VERSION ""

NS_ :

BS_:

BU_: VMCU TECU TACHO RECU_Virt IC3 HPCU EMS EBS DACU CIOM BBM ACM

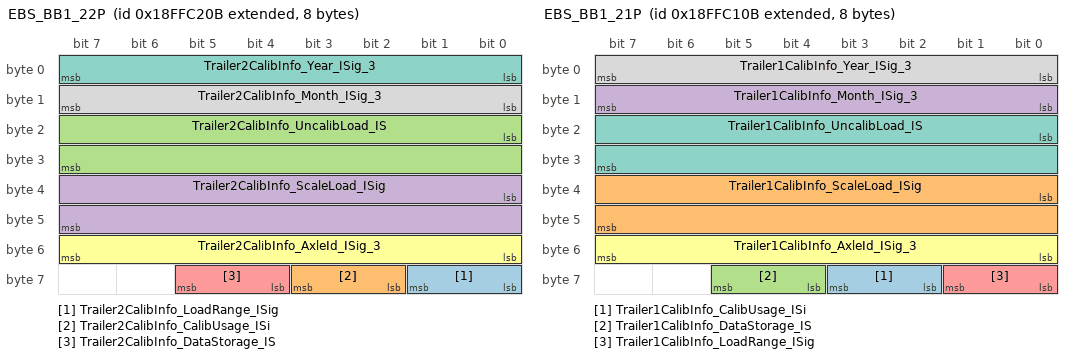
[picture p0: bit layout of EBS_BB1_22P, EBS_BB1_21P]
BO_ 2566898187 EBS_BB1_22P: 8 EBS
 SG_ Trailer2CalibInfo_LoadRange_ISig : 56|2@1+ (1,0) [0|0] ""  VMCU,IC3
 SG_ Trailer2CalibInfo_CalibUsage_ISi : 58|2@1+ (1,0) [0|0] ""  VMCU,IC3
 SG_ Trailer2CalibInfo_UncalibLoad_IS : 16|16@1+ (1,0) [0|65535] "kg"  IC3,VMCU
 SG_ Trailer2CalibInfo_ScaleLoad_ISig : 32|16@1+ (1,0) [0|65535] "kg"  IC3,VMCU
 SG_ Trailer2CalibInfo_DataStorage_IS : 60|2@1+ (1,0) [0|0] ""  IC3,VMCU
 SG_ Trailer2CalibInfo_AxleId_ISig_3 : 48|8@1+ (1,0) [0|255] "NotApplicable"  VMCU,IC3
 SG_ Trailer2CalibInfo_Year_ISig_3 : 0|8@1+ (1,1985) [1985|2240] "Years"  VMCU,IC3
 SG_ Trailer2CalibInfo_Month_ISig_3 : 8|8@1+ (1,0) [0|255] "Months"  IC3,VMCU

BO_ 2566897931 EBS_BB1_21P: 8 EBS
 SG_ Trailer1CalibInfo_CalibUsage_ISi : 58|2@1+ (1,0) [0|0] ""  IC3,VMCU
 SG_ Trailer1CalibInfo_ScaleLoad_ISig : 32|16@1+ (1,0) [0|65535] "kg"  IC3,VMCU
 SG_ Trailer1CalibInfo_DataStorage_IS : 60|2@1+ (1,0) [0|0] ""  IC3,VMCU
 SG_ Trailer1CalibInfo_Month_ISig_3 : 8|8@1+ (1,0) [0|255] "Months"  IC3,VMCU
 SG_ Trailer1CalibInfo_LoadRange_ISig : 56|2@1+ (1,0) [0|0] ""  VMCU,IC3
 SG_ Trailer1CalibInfo_AxleId_ISig_3 : 48|8@1+ (1,0) [0|255] "NotApplicable"  IC3,VMCU
 SG_ Trailer1CalibInfo_UncalibLoad_IS : 16|16@1+ (1,0) [0|65535] "kg"  VMCU,IC3
 SG_ Trailer1CalibInfo_Year_ISig_3 : 0|8@1+ (1,1985) [1985|2240] "Years"  IC3,VMCU

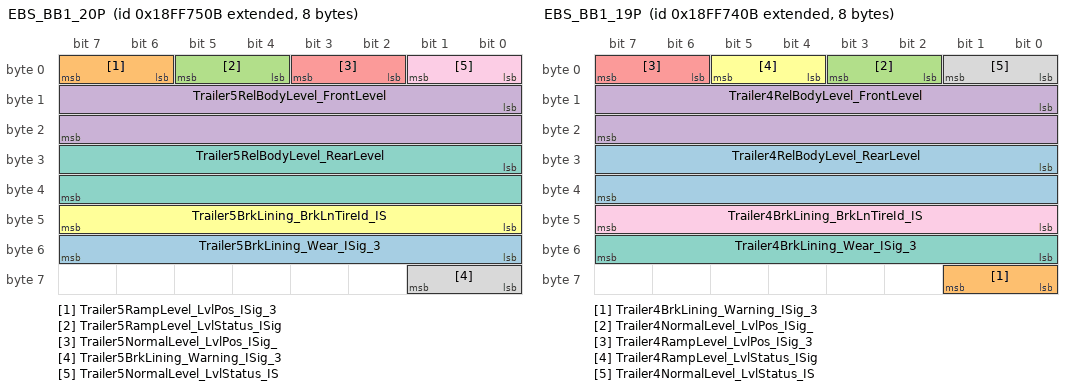
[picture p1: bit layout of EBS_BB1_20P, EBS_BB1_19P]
BO_ 2566878475 EBS_BB1_20P: 8 EBS
 SG_ Trailer5BrkLining_Wear_ISig_3 : 48|8@1+ (0.4,0) [0|102] "Percent"  IC3
 SG_ Trailer5RampLevel_LvlPos_ISig_3 : 6|2@1+ (1,0) [0|0] ""  IC3
 SG_ Trailer5RampLevel_LvlStatus_ISig : 4|2@1+ (1,0) [0|0] ""  IC3
 SG_ Trailer5RelBodyLevel_FrontLevel : 8|16@1+ (1,-32000) [-32000|33535] "mm"  VMCU
 SG_ Trailer5NormalLevel_LvlPos_ISig_ : 2|2@1+ (1,0) [0|0] ""  IC3
 SG_ Trailer5BrkLining_BrkLnTireId_IS : 40|8@1+ (1,0) [0|255] "NotApplicable"  IC3
 SG_ Trailer5RelBodyLevel_RearLevel : 24|16@1+ (1,-32000) [-32000|33535] "mm"  VMCU
 SG_ Trailer5BrkLining_Warning_ISig_3 : 56|2@1+ (1,0) [0|0] ""  IC3
 SG_ Trailer5NormalLevel_LvlStatus_IS : 0|2@1+ (1,0) [0|0] ""  IC3

BO_ 2566878219 EBS_BB1_19P: 8 EBS
 SG_ Trailer4RelBodyLevel_RearLevel : 24|16@1+ (1,-32000) [-32000|33535] "mm"  VMCU
 SG_ Trailer4BrkLining_Warning_ISig_3 : 56|2@1+ (1,0) [0|0] ""  IC3
 SG_ Trailer4NormalLevel_LvlPos_ISig_ : 2|2@1+ (1,0) [0|0] ""  IC3
 SG_ Trailer4RelBodyLevel_FrontLevel : 8|16@1+ (1,-32000) [-32000|33535] "mm"  VMCU
 SG_ Trailer4RampLevel_LvlPos_ISig_3 : 6|2@1+ (1,0) [0|0] ""  IC3
 SG_ Trailer4RampLevel_LvlStatus_ISig : 4|2@1+ (1,0) [0|0] ""  IC3
 SG_ Trailer4BrkLining_Wear_ISig_3 : 48|8@1+ (0.4,0) [0|102] "Percent"  IC3
 SG_ Trailer4NormalLevel_LvlStatus_IS : 0|2@1+ (1,0) [0|0] ""  IC3
 SG_ Trailer4BrkLining_BrkLnTireId_IS : 40|8@1+ (1,0) [0|255] "NotApplicable"  IC3

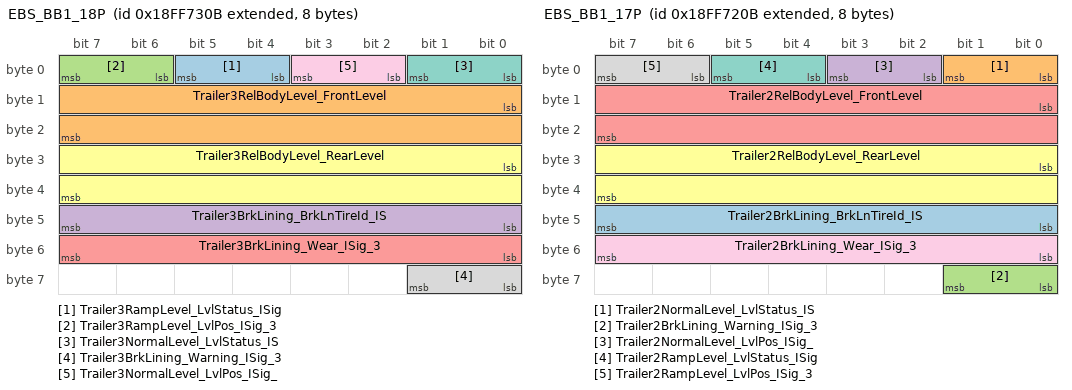
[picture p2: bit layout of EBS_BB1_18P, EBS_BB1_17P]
BO_ 2566877963 EBS_BB1_18P: 8 EBS
 SG_ Trailer3RampLevel_LvlStatus_ISig : 4|2@1+ (1,0) [0|0] ""  IC3
 SG_ Trailer3RelBodyLevel_FrontLevel : 8|16@1+ (1,-32000) [-32000|33535] "mm"  VMCU
 SG_ Trailer3RampLevel_LvlPos_ISig_3 : 6|2@1+ (1,0) [0|0] ""  IC3
 SG_ Trailer3BrkLining_BrkLnTireId_IS : 40|8@1+ (1,0) [0|255] "NotApplicable"  IC3
 SG_ Trailer3BrkLining_Wear_ISig_3 : 48|8@1+ (0.4,0) [0|102] "Percent"  IC3
 SG_ Trailer3RelBodyLevel_RearLevel : 24|16@1+ (1,-32000) [-32000|33535] "mm"  VMCU
 SG_ Trailer3NormalLevel_LvlStatus_IS : 0|2@1+ (1,0) [0|0] ""  IC3
 SG_ Trailer3BrkLining_Warning_ISig_3 : 56|2@1+ (1,0) [0|0] ""  IC3
 SG_ Trailer3NormalLevel_LvlPos_ISig_ : 2|2@1+ (1,0) [0|0] ""  IC3

BO_ 2566877707 EBS_BB1_17P: 8 EBS
 SG_ Trailer2BrkLining_BrkLnTireId_IS : 40|8@1+ (1,0) [0|255] "NotApplicable"  IC3
 SG_ Trailer2NormalLevel_LvlStatus_IS : 0|2@1+ (1,0) [0|0] ""  IC3
 SG_ Trailer2BrkLining_Warning_ISig_3 : 56|2@1+ (1,0) [0|0] ""  IC3
 SG_ Trailer2NormalLevel_LvlPos_ISig_ : 2|2@1+ (1,0) [0|0] ""  IC3
 SG_ Trailer2RelBodyLevel_FrontLevel : 8|16@1+ (1,-32000) [-32000|33535] "mm"  VMCU
 SG_ Trailer2RelBodyLevel_RearLevel : 24|16@1+ (1,-32000) [-32000|33535] "mm"  VMCU
 SG_ Trailer2RampLevel_LvlStatus_ISig : 4|2@1+ (1,0) [0|0] ""  IC3
 SG_ Trailer2RampLevel_LvlPos_ISig_3 : 6|2@1+ (1,0) [0|0] ""  IC3
 SG_ Trailer2BrkLining_Wear_ISig_3 : 48|8@1+ (0.4,0) [0|102] "Percent"  IC3

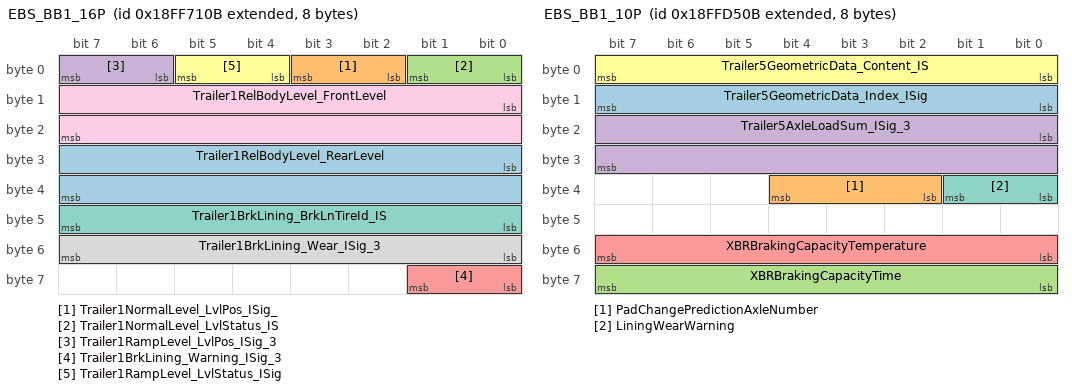
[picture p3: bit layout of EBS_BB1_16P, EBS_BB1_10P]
BO_ 2566877451 EBS_BB1_16P: 8 EBS
 SG_ Trailer1RelBodyLevel_RearLevel : 24|16@1+ (1,-32000) [-32000|33535] "mm"  VMCU
 SG_ Trailer1NormalLevel_LvlPos_ISig_ : 2|2@1+ (1,0) [0|0] ""  IC3
 SG_ Trailer1NormalLevel_LvlStatus_IS : 0|2@1+ (1,0) [0|0] ""  IC3
 SG_ Trailer1RampLevel_LvlPos_ISig_3 : 6|2@1+ (1,0) [0|0] ""  IC3
 SG_ Trailer1BrkLining_Warning_ISig_3 : 56|2@1+ (1,0) [0|0] ""  IC3
 SG_ Trailer1RampLevel_LvlStatus_ISig : 4|2@1+ (1,0) [0|0] ""  IC3
 SG_ Trailer1BrkLining_BrkLnTireId_IS : 40|8@1+ (1,0) [0|255] "NotApplicable"  IC3
 SG_ Trailer1BrkLining_Wear_ISig_3 : 48|8@1+ (0.4,0) [0|102] "Percent"  IC3
 SG_ Trailer1RelBodyLevel_FrontLevel : 8|16@1+ (1,-32000) [-32000|33535] "mm"  VMCU

BO_ 2566894859 EBS_BB1_15P: 17 EBS
 SG_ Trailer5VIN_ISig_3 : 0|136@1+ (1,0) [0|0] ""  IC3,VMCU

BO_ 2566894603 EBS_BB1_14P: 17 EBS
 SG_ Trailer4VIN_ISig_3 : 0|136@1+ (1,0) [0|0] ""  VMCU,IC3

BO_ 2566894347 EBS_BB1_13P: 17 EBS
 SG_ Trailer3VIN_ISig_3 : 0|136@1+ (1,0) [0|0] ""  VMCU,IC3

BO_ 2566894091 EBS_BB1_12P: 17 EBS
 SG_ Trailer2VIN_ISig_3 : 0|136@1+ (1,0) [0|0] ""  VMCU,IC3

BO_ 2566893835 EBS_BB1_11P: 17 EBS
 SG_ Trailer1VIN_ISig_3 : 0|136@1+ (1,0) [0|0] ""  IC3,VMCU

BO_ 2566903051 EBS_BB1_10P: 8 EBS
 SG_ Trailer5GeometricData_Index_ISig : 8|8@1+ (1,0) [0|0] ""  VMCU,IC3,DACU
 SG_ PadChangePredictionAxleNumber : 34|3@1+ (1,0) [0|0] ""  VMCU
 SG_ XBRBrakingCapacityTime : 56|8@1+ (1,0) [0|255] "s"  EMS,TECU,DACU
 SG_ Trailer5AxleLoadSum_ISig_3 : 16|16@1+ (2,0) [0|131070] "kg"  IC3,VMCU
 SG_ XBRBrakingCapacityTemperature : 48|8@1+ (0.4,0) [0|102] "Percent"  TECU,DACU,EMS
 SG_ Trailer5GeometricData_Content_IS : 0|8@1+ (1,0) [0|255] ""  VMCU,IC3,DACU
 SG_ LiningWearWarning : 32|2@1+ (1,0) [0|0] ""  IC3

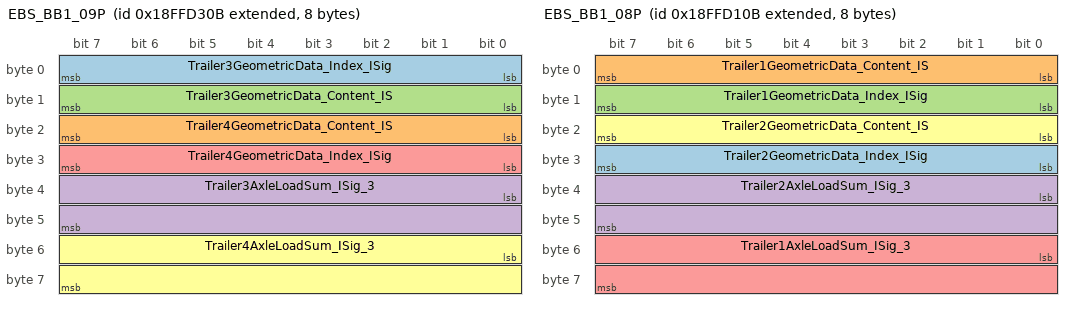
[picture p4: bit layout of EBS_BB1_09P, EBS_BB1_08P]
BO_ 2566902539 EBS_BB1_09P: 8 EBS
 SG_ Trailer3GeometricData_Index_ISig : 0|8@1+ (1,0) [0|0] ""  IC3,DACU,VMCU
 SG_ Trailer4GeometricData_Content_IS : 16|8@1+ (1,0) [0|255] ""  DACU,IC3,VMCU
 SG_ Trailer3GeometricData_Content_IS : 8|8@1+ (1,0) [0|255] ""  IC3,DACU,VMCU
 SG_ Trailer3AxleLoadSum_ISig_3 : 32|16@1+ (2,0) [0|131070] "kg"  IC3,TECU,VMCU
 SG_ Trailer4GeometricData_Index_ISig : 24|8@1+ (1,0) [0|0] ""  IC3,DACU,VMCU
 SG_ Trailer4AxleLoadSum_ISig_3 : 48|16@1+ (2,0) [0|131070] "kg"  TECU,VMCU,IC3

BO_ 2566902027 EBS_BB1_08P: 8 EBS
 SG_ Trailer2GeometricData_Index_ISig : 24|8@1+ (1,0) [0|0] ""  VMCU,DACU,IC3
 SG_ Trailer1GeometricData_Content_IS : 0|8@1+ (1,0) [0|255] ""  DACU,VMCU,IC3
 SG_ Trailer1GeometricData_Index_ISig : 8|8@1+ (1,0) [0|0] ""  IC3,DACU,VMCU
 SG_ Trailer2AxleLoadSum_ISig_3 : 32|16@1+ (2,0) [0|131070] "kg"  TECU,IC3,VMCU
 SG_ Trailer1AxleLoadSum_ISig_3 : 48|16@1+ (2,0) [0|131070] "kg"  IC3,TECU,VMCU
 SG_ Trailer2GeometricData_Content_IS : 16|8@1+ (1,0) [0|255] ""  DACU,VMCU,IC3

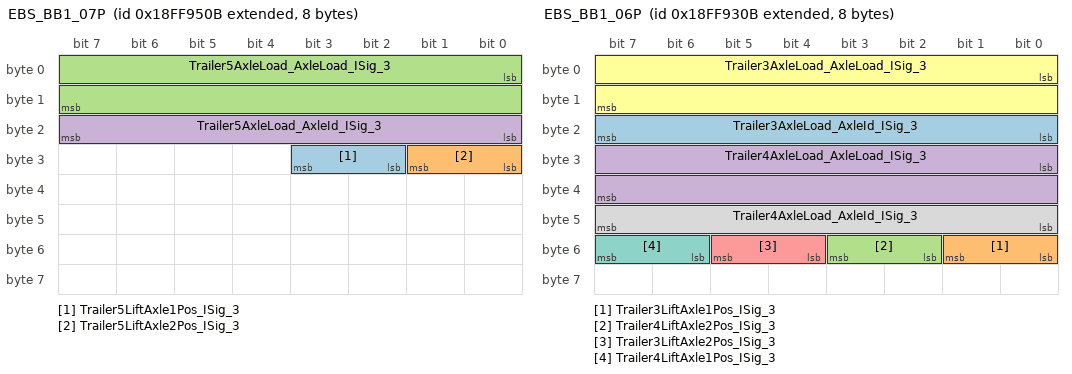
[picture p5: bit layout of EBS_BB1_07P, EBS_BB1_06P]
BO_ 2566886667 EBS_BB1_07P: 8 EBS
 SG_ Trailer5LiftAxle1Pos_ISig_3 : 26|2@1+ (1,0) [0|0] ""  VMCU,BBM,CIOM,IC3
 SG_ Trailer5LiftAxle2Pos_ISig_3 : 24|2@1+ (1,0) [0|0] ""  BBM,CIOM,VMCU,IC3
 SG_ Trailer5AxleLoad_AxleLoad_ISig_3 : 0|16@1+ (0.5,0) [0|32767.5] "kg"  BBM,VMCU,IC3
 SG_ Trailer5AxleLoad_AxleId_ISig_3 : 16|8@1+ (1,0) [0|255] "NotApplicable"  VMCU,BBM,IC3

BO_ 2566886155 EBS_BB1_06P: 8 EBS
 SG_ Trailer3AxleLoad_AxleId_ISig_3 : 16|8@1+ (1,0) [0|255] "NotApplicable"  VMCU,BBM,IC3
 SG_ Trailer3LiftAxle1Pos_ISig_3 : 48|2@1+ (1,0) [0|0] ""  BBM,VMCU,CIOM,IC3
 SG_ Trailer4LiftAxle2Pos_ISig_3 : 50|2@1+ (1,0) [0|0] ""  BBM,VMCU,CIOM,IC3
 SG_ Trailer4AxleLoad_AxleLoad_ISig_3 : 24|16@1+ (0.5,0) [0|32767.5] "kg"  BBM,VMCU,IC3
 SG_ Trailer3LiftAxle2Pos_ISig_3 : 52|2@1+ (1,0) [0|0] ""  CIOM,BBM,VMCU,IC3
 SG_ Trailer3AxleLoad_AxleLoad_ISig_3 : 0|16@1+ (0.5,0) [0|32767.5] "kg"  BBM,VMCU,IC3
 SG_ Trailer4LiftAxle1Pos_ISig_3 : 54|2@1+ (1,0) [0|0] ""  CIOM,IC3,VMCU,BBM
 SG_ Trailer4AxleLoad_AxleId_ISig_3 : 40|8@1+ (1,0) [0|255] "NotApplicable"  VMCU,IC3,BBM

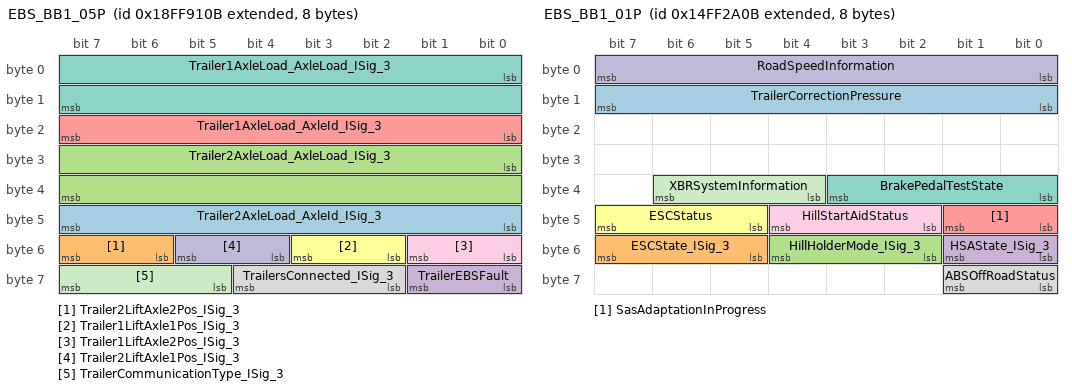
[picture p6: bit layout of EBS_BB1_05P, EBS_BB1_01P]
BO_ 2566885643 EBS_BB1_05P: 8 EBS
 SG_ Trailer2AxleLoad_AxleId_ISig_3 : 40|8@1+ (1,0) [0|255] "NotApplicable"  VMCU,BBM,IC3
 SG_ Trailer2LiftAxle2Pos_ISig_3 : 54|2@1+ (1,0) [0|0] ""  IC3,CIOM,BBM,VMCU
 SG_ Trailer2AxleLoad_AxleLoad_ISig_3 : 24|16@1+ (0.5,0) [0|32767.5] "kg"  IC3,BBM,VMCU
 SG_ TrailerEBSFault : 56|2@1+ (1,0) [0|0] ""  IC3
 SG_ Trailer1AxleLoad_AxleId_ISig_3 : 16|8@1+ (1,0) [0|255] "NotApplicable"  IC3,VMCU,BBM
 SG_ Trailer1LiftAxle1Pos_ISig_3 : 50|2@1+ (1,0) [0|0] ""  IC3,CIOM,BBM,VMCU
 SG_ Trailer1AxleLoad_AxleLoad_ISig_3 : 0|16@1+ (0.5,0) [0|32767.5] "kg"  BBM,IC3,VMCU
 SG_ TrailersConnected_ISig_3 : 58|3@1+ (1,0) [0|7] "Count"  DACU,CIOM,IC3,TECU,VMCU
 SG_ Trailer1LiftAxle2Pos_ISig_3 : 48|2@1+ (1,0) [0|0] ""  IC3,BBM,CIOM,VMCU
 SG_ Trailer2LiftAxle1Pos_ISig_3 : 52|2@1+ (1,0) [0|0] ""  IC3,CIOM,VMCU,BBM
 SG_ TrailerCommunicationType_ISig_3 : 61|3@1+ (1,0) [0|0] ""  IC3

BO_ 2566906635 EBS_BB1_04P: 8 EBS
 SG_ PredictedMileageOfNextPadChg : 0|32@1+ (1,0) [0|4294967295] "km"  IC3,VMCU
 SG_ PadChgPredictionLastPadChg : 32|32@1+ (1,0) [0|4294967295] "km"  VMCU

BO_ 2499761675 EBS_BB1_02P: 8 EBS
 SG_ HSAAvailability : 22|2@1+ (1,0) [0|0] ""  BBM,TECU
 SG_ DTCActive : 6|2@1+ (1,0) [0|0] ""  IC3
 SG_ StretchBrake_Stat_ISig_3 : 58|3@1+ (1,0) [0|0] ""  IC3,VMCU
 SG_ TrcnCtrlSlipperyRoadWarning_ISig : 4|2@1+ (1,0) [0|0] ""  BBM,IC3,DACU
 SG_ RearAxleDiffLockActvnFuncReq_ISi : 10|2@1+ (1,0) [0|0] ""  VMCU
 SG_ BrakeTempWarningLevel : 24|8@1+ (1,0) [0|255] "Percent"  VMCU,DACU,TECU,EMS
 SG_ RollerBenchModeStatus : 0|2@1+ (1,0) [0|0] ""  DACU,CIOM,IC3,VMCU
 SG_ BrakeAssistStatus : 8|2@1+ (1,0) [0|0] ""  VMCU
 SG_ LongitudinalAcceleration_ISig_3 : 32|16@1+ (0.00048828125,-15.687) [-15.687|16.31251171875] "m_per_s_squared"  BBM,IC3
 SG_ ABSManAutoInhibitionStat_ISig_3 : 61|3@1+ (1,0) [0|0] ""  IC3
 SG_ TractionFunctionSelected_ISig_3 : 53|3@1+ (1,0) [0|0] ""  IC3
 SG_ PoorBrakePerformanceWarning : 14|2@1+ (1,0) [0|0] ""  IC3
 SG_ VDCActive_ISig_3 : 56|2@1+ (1,0) [0|0] ""  IC3
 SG_ ABSInhibitionStatus_ISig_3 : 16|2@1+ (1,0) [0|0] ""  TECU,CIOM,VMCU,IC3
 SG_ RearAxleSteeringFunctionStatus : 50|3@1+ (1,0) [0|0] ""  DACU,CIOM
 SG_ AutoRearAxleDiffLockFnc_stat : 48|2@1+ (1,0) [0|0] ""  IC3
 SG_ RearAxleDiffLockActvnFuncReq_UB_ : 2|1@1+ (1,0) [0|0] ""  VMCU

BO_ 2499750411 EBS_BB1_01P: 8 EBS
 SG_ TrailerCorrectionPressure : 8|8@1+ (0.05,-1.5) [-1.5|11.25] "Bar"  VMCU
 SG_ ESCState_ISig_3 : 53|3@1+ (1,0) [0|0] ""  CIOM,IC3
 SG_ HillHolderMode_ISig_3 : 50|3@1+ (1,0) [0|0] ""  DACU,TECU
 SG_ HSAState_ISig_3 : 48|2@1+ (1,0) [0|0] ""  DACU
 SG_ SasAdaptationInProgress : 40|2@1+ (1,0) [0|0] ""  IC3
 SG_ ESCStatus : 45|3@1+ (1,0) [0|0] ""  IC3
 SG_ BrakePedalTestState : 32|4@1+ (1,0) [0|0] ""  IC3
 SG_ ABSOffRoadStatus : 56|2@1+ (1,0) [0|0] ""  VMCU,IC3,TECU
 SG_ HillStartAidStatus : 42|3@1+ (1,0) [0|0] ""  IC3
 SG_ RoadSpeedInformation : 0|8@1+ (0.805,0) [0|205.275] "Km_per_h"  VMCU
 SG_ XBRSystemInformation : 36|3@1+ (1,0) [0|0] ""  TECU,DACU,EMS

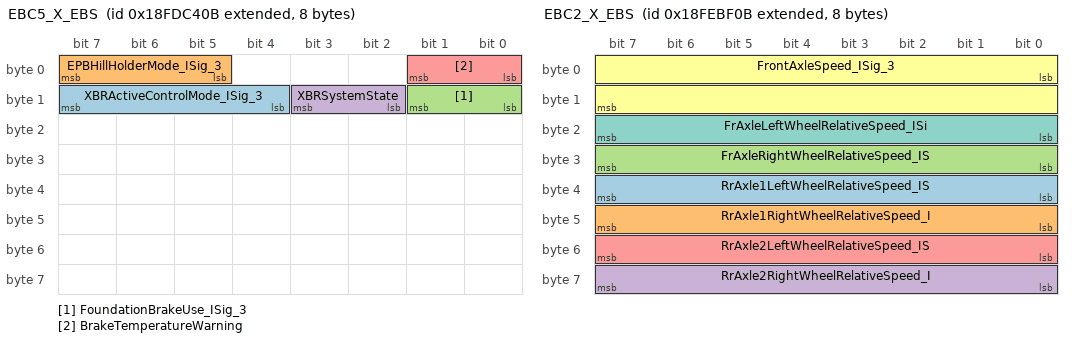
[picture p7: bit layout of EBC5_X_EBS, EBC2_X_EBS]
BO_ 2566767627 EBC5_X_EBS: 8 EBS
 SG_ XBRActiveControlMode_ISig_3 : 12|4@1+ (1,0) [0|0] ""  BBM,EMS,TECU,DACU,VMCU
 SG_ EPBHillHolderMode_ISig_3 : 5|3@1+ (1,0) [0|0] ""  TECU,IC3,VMCU
 SG_ FoundationBrakeUse_ISig_3 : 8|2@1+ (1,0) [0|0] ""  DACU,CIOM,EMS,TECU,VMCU
 SG_ XBRSystemState : 10|2@1+ (1,0) [0|0] ""  BBM,DACU,EMS,TECU
 SG_ BrakeTemperatureWarning : 0|2@1+ (1,0) [0|0] ""  IC3

BO_ 2566831883 EBC2_X_EBS: 8 EBS
 SG_ RrAxle1LeftWheelRelativeSpeed_IS : 32|8@1+ (0.0625,-7.8125) [-7.8125|8.125] "Km_per_h"  TECU,VMCU
 SG_ RrAxle1RightWheelRelativeSpeed_I : 40|8@1+ (0.0625,-7.8125) [-7.8125|8.125] "Km_per_h"  VMCU,TECU
 SG_ FrAxleRightWheelRelativeSpeed_IS : 24|8@1+ (0.0625,-7.8125) [-7.8125|8.125] "Km_per_h"  TECU,VMCU
 SG_ RrAxle2RightWheelRelativeSpeed_I : 56|8@1+ (0.0625,-7.8125) [-7.8125|8.125] "Km_per_h"  TECU,VMCU
 SG_ RrAxle2LeftWheelRelativeSpeed_IS : 48|8@1+ (0.0625,-7.8125) [-7.8125|8.125] "Km_per_h"  TECU,VMCU
 SG_ FrontAxleSpeed_ISig_3 : 0|16@1+ (0.00390625,0) [0|255.99609375] "Km_per_h"  IC3,VMCU,BBM,EMS,CIOM,DACU,TECU,TACHO
 SG_ FrAxleLeftWheelRelativeSpeed_ISi : 16|8@1+ (0.0625,-7.8125) [-7.8125|8.125] "Km_per_h"  TECU,VMCU

CM_ SG_ 2566898187 Trailer2CalibInfo_UncalibLoad_IS "10000-65023: Spare, 65024-65279: Error, 65280-65535: NotAvailable";
CM_ SG_ 2566898187 Trailer2CalibInfo_ScaleLoad_ISig "10000-65023: Spare, 65024-65279: Error, 65280-65535: NotAvailable";
CM_ SG_ 2566898187 Trailer2CalibInfo_Year_ISig_3 "254 Error ; 255 Not available";
CM_ SG_ 2566898187 Trailer2CalibInfo_Month_ISig_3 "254 Error ; 255 Not available";
CM_ SG_ 2566897931 Trailer1CalibInfo_ScaleLoad_ISig "10000-65023: Spare, 65024-65279: Error, 65280-65535: NotAvailable";
CM_ SG_ 2566897931 Trailer1CalibInfo_Month_ISig_3 "254 Error ; 255 Not available";
CM_ SG_ 2566897931 Trailer1CalibInfo_UncalibLoad_IS "10000-65023: Spare, 65024-65279: Error, 65280-65535: NotAvailable";
CM_ SG_ 2566897931 Trailer1CalibInfo_Year_ISig_3 "254 Error ; 255 Not available";
CM_ SG_ 2566903051 Trailer5AxleLoadSum_ISig_3 "65024 - 65279 Error ; 65280 - 65535 Not Available";
CM_ SG_ 2566903051 Trailer5GeometricData_Content_IS "254 Error ; 255 Not Available";
CM_ SG_ 2566902539 Trailer4GeometricData_Content_IS "254 Error ; 255 Not Available";
CM_ SG_ 2566902539 Trailer3GeometricData_Content_IS "254 Error ; 255 Not Available";
CM_ SG_ 2566902539 Trailer3AxleLoadSum_ISig_3 "65024 - 65279 Error ; 65280 - 65535 Not Available";
CM_ SG_ 2566902539 Trailer4AxleLoadSum_ISig_3 "65024 - 65279 Error ; 65280 - 65535 Not Available";
CM_ SG_ 2566902027 Trailer1GeometricData_Content_IS "254 Error ; 255 Not Available";
CM_ SG_ 2566902027 Trailer2AxleLoadSum_ISig_3 "65024 - 65279 Error ; 65280 - 65535 Not Available";
CM_ SG_ 2566902027 Trailer1AxleLoadSum_ISig_3 "65024 - 65279 Error ; 65280 - 65535 Not Available";
CM_ SG_ 2566902027 Trailer2GeometricData_Content_IS "254 Error ; 255 Not Available";
CM_ SG_ 2566886667 Trailer5AxleLoad_AxleLoad_ISig_3 "65024 - 65279 Error ; 65280 - 65535 Not available";
CM_ SG_ 2566886155 Trailer4AxleLoad_AxleLoad_ISig_3 "65024 - 65279 Error ; 65280 - 65535 Not available";
CM_ SG_ 2566886155 Trailer3AxleLoad_AxleLoad_ISig_3 "65024 - 65279 Error ; 65280 - 65535 Not available";
CM_ SG_ 2566885643 Trailer2AxleLoad_AxleLoad_ISig_3 "65024 - 65279 Error ; 65280 - 65535 Not available";
CM_ SG_ 2566885643 Trailer1AxleLoad_AxleLoad_ISig_3 "65024 - 65279 Error ; 65280 - 65535 Not available";
CM_ SG_ 2566885643 TrailersConnected_ISig_3 "6 Error ; 7 Not available";
CM_ SG_ 2566906635 PredictedMileageOfNextPadChg "4261412864 - 4278190079 Error ; 4278190080 - 4294967295 Not available";
CM_ SG_ 2566906635 PadChgPredictionLastPadChg "4261412864 - 4278190079 Error ; 4278190080 - 4294967295 Not available";
CM_ SG_ 2499761675 BrakeTempWarningLevel "254 Error ; 255 Not available";
CM_ SG_ 2499761675 LongitudinalAcceleration_ISig_3 "65024 - 65279 Error ; 65280 - 65535 Not available";
CM_ SG_ 2499750411 TrailerCorrectionPressure "254 Error ; 255 Not available";
CM_ SG_ 2499750411 RoadSpeedInformation "254 Error ; 255 Not available";
CM_ BO_ 2566767627 "PGN 64964 Electronic Brake Controller 5";
CM_ BO_ 2566831883 "PGN 65215 Wheel Speed Information";
CM_ SG_ 2566831883 RrAxle1LeftWheelRelativeSpeed_IS "254 Error ; 255 Not available";
CM_ SG_ 2566831883 RrAxle1RightWheelRelativeSpeed_I "254 Error ; 255 Not available";
CM_ SG_ 2566831883 FrAxleRightWheelRelativeSpeed_IS "254 Error ; 255 Not available";
CM_ SG_ 2566831883 RrAxle2RightWheelRelativeSpeed_I "254 Error ; 255 Not available";
CM_ SG_ 2566831883 RrAxle2LeftWheelRelativeSpeed_IS "254 Error ; 255 Not available";
CM_ SG_ 2566831883 FrontAxleSpeed_ISig_3 "65024 - 65279 Error ; 65280 - 65535 Not available";
CM_ SG_ 2566831883 FrAxleLeftWheelRelativeSpeed_ISi "254 Error ; 255 Not available";
BA_DEF_ BO_  "GenMsgStartDelayTime" INT 0 0;
BA_DEF_ BO_  "GenMsgDelayTime" INT 0 0;
BA_DEF_ BO_  "GenMsgNrOfRepetition" INT 0 0;
BA_DEF_ BO_  "GenMsgCycleTimeFast" INT 0 0;
BA_DEF_ BO_  "GenMsgCycleTime" INT 0 0;
BA_DEF_ BO_  "GenMsgSendType" ENUM  "Cyclic","NotUsed","NotUsed","NotUsed","NotUsed","NotUsed","NotUsed","IfActive","NoMsgSendType","NotUsed";
BA_DEF_ SG_  "GenSigStartValue" INT 0 0;
BA_DEF_ SG_  "GenSigCycleTimeActive" INT 0 0;
BA_DEF_ SG_  "GenSigCycleTime" INT 0 0;
BA_DEF_ SG_  "GenSigSendType" ENUM  "Cyclic","OnWrite","OnWriteWithRepetition","OnChange","OnChangeWithRepetition","IfActive","IfActiveWithRepetition","NoSigSendType","NotUsed","NotUsed","NotUsed","NotUsed","NotUsed";
BA_DEF_ BO_  "VFrameFormat" ENUM  "StandardCAN","ExtendedCAN","reserved","J1939PG","reserved","reserved","reserved","reserved","reserved","reserved","reserved","reserved","reserved","reserved","StandardCAN_FD","ExtendedCAN_FD";
BA_DEF_ BO_  "TpJ1939VarDlc" ENUM  "No","Yes";
BA_DEF_ SG_  "SigType" ENUM  "Default","Range","RangeSigned","ASCII","Discrete","Control","ReferencePGN","DTC","StringDelimiter","StringLength","StringLengthControl";
BA_DEF_ SG_  "SeToolVersion_SIGNAL" STRING ;
BA_DEF_ SG_  "SeToolUniqueID_SIGNAL" STRING ;
BA_DEF_ SG_  "SeToolOwnerSigGroup_SIGNAL" STRING ;
BA_DEF_ SG_  "SeToolOwnerSigGroupID_SIGNAL" STRING ;
BA_DEF_ SG_  "SeToolName_SIGNAL" STRING ;
BA_DEF_ SG_  "SeToolItemID_SIGNAL" STRING ;
BA_DEF_ SG_  "SeToolAncestorID_SIGNAL" STRING ;
BA_DEF_ SG_  "SPN" INT 0 524287;
BA_DEF_ SG_  "Platform_VMCU1_Sig" ENUM  "No","Yes";
BA_DEF_ SG_  "Platform_FactoryIf_Sig" ENUM  "No","Yes";
BA_DEF_ SG_  "NeedsUpdateBit" ENUM  "No","Yes";
BA_DEF_ SG_  "GenSigMaxLatency" INT 0 65535;
BA_DEF_ SG_  "GenSigILSupport" ENUM  "Yes","No";
BA_DEF_ BO_  "GenMsgILSupport" ENUM  "No","Yes";
BA_DEF_ BO_  "DiagUUDTResponse" ENUM  "No","Yes";
BA_DEF_ BO_  "DiagState" ENUM  "No","Yes";
BA_DEF_ BO_  "DiagResponse" ENUM  "No","Yes";
BA_DEF_ BO_  "DiagRequest" ENUM  "No","Yes";
BA_DEF_ BO_  "DiagConnection" HEX 0 65535;
BA_DEF_ BO_  "CanTpFcFrameId" HEX 0 2147483647;
BA_DEF_ BO_  "CanTpBs" INT 0 255;
BA_DEF_ SG_  "SystemSignalLongSymbol" STRING ;
BA_DEF_REL_ BU_SG_REL_  "GenSigTimeoutTime" INT 0 65535;
BA_DEF_REL_ BU_SG_REL_  "GenSigFirstTimeoutTime" INT 0 65535;
BA_DEF_DEF_  "GenMsgStartDelayTime" 0;
BA_DEF_DEF_  "GenMsgDelayTime" 0;
BA_DEF_DEF_  "GenMsgNrOfRepetition" 0;
BA_DEF_DEF_  "GenMsgCycleTimeFast" 0;
BA_DEF_DEF_  "GenMsgCycleTime" 0;
BA_DEF_DEF_  "GenMsgSendType" "Cyclic";
BA_DEF_DEF_  "GenSigStartValue" 0;
BA_DEF_DEF_  "GenSigCycleTimeActive" 0;
BA_DEF_DEF_  "GenSigCycleTime" 0;
BA_DEF_DEF_  "GenSigSendType" "Cyclic";
BA_DEF_DEF_  "VFrameFormat" "ExtendedCAN";
BA_DEF_DEF_  "TpJ1939VarDlc" "No";
BA_DEF_DEF_  "SigType" "Default";
BA_DEF_DEF_  "SeToolVersion_SIGNAL" "";
BA_DEF_DEF_  "SeToolUniqueID_SIGNAL" "";
BA_DEF_DEF_  "SeToolOwnerSigGroup_SIGNAL" "";
BA_DEF_DEF_  "SeToolOwnerSigGroupID_SIGNAL" "";
BA_DEF_DEF_  "SeToolName_SIGNAL" "";
BA_DEF_DEF_  "SeToolItemID_SIGNAL" "";
BA_DEF_DEF_  "SeToolAncestorID_SIGNAL" "";
BA_DEF_DEF_  "SPN" 0;
BA_DEF_DEF_  "Platform_VMCU1_Sig" "No";
BA_DEF_DEF_  "Platform_FactoryIf_Sig" "No";
BA_DEF_DEF_  "NeedsUpdateBit" "No";
BA_DEF_DEF_  "GenSigMaxLatency" 0;
BA_DEF_DEF_  "GenSigILSupport" "Yes";
BA_DEF_DEF_  "GenMsgILSupport" "Yes";
BA_DEF_DEF_  "DiagUUDTResponse" "No";
BA_DEF_DEF_  "DiagState" "No";
BA_DEF_DEF_  "DiagResponse" "No";
BA_DEF_DEF_  "DiagRequest" "No";
BA_DEF_DEF_  "DiagConnection" 0;
BA_DEF_DEF_  "CanTpFcFrameId" 2147483647;
BA_DEF_DEF_  "CanTpBs" 255;
BA_DEF_DEF_REL_ "GenSigTimeoutTime" 0;
BA_DEF_DEF_REL_ "GenSigFirstTimeoutTime" 0;
BA_DEF_DEF_  "SystemSignalLongSymbol" "";
BA_ "GenMsgCycleTime" BO_ 2566898187 1000;
BA_ "GenMsgStartDelayTime" BO_ 2566898187 160;
BA_ "VFrameFormat" BO_ 2566898187 3;
BA_ "GenMsgCycleTime" BO_ 2566897931 1000;
BA_ "GenMsgStartDelayTime" BO_ 2566897931 55;
BA_ "VFrameFormat" BO_ 2566897931 3;
BA_ "GenMsgCycleTime" BO_ 2566878475 100;
BA_ "GenMsgStartDelayTime" BO_ 2566878475 60;
BA_ "VFrameFormat" BO_ 2566878475 3;
BA_ "GenMsgCycleTime" BO_ 2566878219 100;
BA_ "GenMsgStartDelayTime" BO_ 2566878219 25;
BA_ "VFrameFormat" BO_ 2566878219 3;
BA_ "GenMsgCycleTime" BO_ 2566877963 100;
BA_ "GenMsgStartDelayTime" BO_ 2566877963 20;
BA_ "VFrameFormat" BO_ 2566877963 3;
BA_ "GenMsgCycleTime" BO_ 2566877707 100;
BA_ "GenMsgStartDelayTime" BO_ 2566877707 15;
BA_ "VFrameFormat" BO_ 2566877707 3;
BA_ "GenMsgCycleTime" BO_ 2566877451 100;
BA_ "GenMsgStartDelayTime" BO_ 2566877451 10;
BA_ "VFrameFormat" BO_ 2566877451 3;
BA_ "GenMsgCycleTime" BO_ 2566894859 10000;
BA_ "GenMsgStartDelayTime" BO_ 2566894859 2040;
BA_ "VFrameFormat" BO_ 2566894859 3;
BA_ "GenMsgCycleTime" BO_ 2566894603 10000;
BA_ "GenMsgStartDelayTime" BO_ 2566894603 1530;
BA_ "VFrameFormat" BO_ 2566894603 3;
BA_ "GenMsgCycleTime" BO_ 2566894347 10000;
BA_ "GenMsgStartDelayTime" BO_ 2566894347 1020;
BA_ "VFrameFormat" BO_ 2566894347 3;
BA_ "GenMsgCycleTime" BO_ 2566894091 10000;
BA_ "GenMsgStartDelayTime" BO_ 2566894091 510;
BA_ "VFrameFormat" BO_ 2566894091 3;
BA_ "GenMsgCycleTime" BO_ 2566893835 10000;
BA_ "GenMsgStartDelayTime" BO_ 2566893835 100;
BA_ "VFrameFormat" BO_ 2566893835 3;
BA_ "GenMsgCycleTime" BO_ 2566903051 1000;
BA_ "GenMsgStartDelayTime" BO_ 2566903051 360;
BA_ "VFrameFormat" BO_ 2566903051 3;
BA_ "GenMsgCycleTime" BO_ 2566902539 1000;
BA_ "GenMsgStartDelayTime" BO_ 2566902539 265;
BA_ "VFrameFormat" BO_ 2566902539 3;
BA_ "GenMsgCycleTime" BO_ 2566902027 1000;
BA_ "GenMsgStartDelayTime" BO_ 2566902027 170;
BA_ "VFrameFormat" BO_ 2566902027 3;
BA_ "GenMsgCycleTime" BO_ 2566886667 100;
BA_ "GenMsgStartDelayTime" BO_ 2566886667 50;
BA_ "VFrameFormat" BO_ 2566886667 3;
BA_ "GenMsgCycleTime" BO_ 2566886155 100;
BA_ "GenMsgStartDelayTime" BO_ 2566886155 45;
BA_ "VFrameFormat" BO_ 2566886155 3;
BA_ "GenMsgCycleTime" BO_ 2566885643 100;
BA_ "GenMsgStartDelayTime" BO_ 2566885643 40;
BA_ "VFrameFormat" BO_ 2566885643 3;
BA_ "GenMsgCycleTime" BO_ 2566906635 2000;
BA_ "GenMsgStartDelayTime" BO_ 2566906635 555;
BA_ "VFrameFormat" BO_ 2566906635 3;
BA_ "GenMsgCycleTime" BO_ 2499761675 40;
BA_ "GenMsgStartDelayTime" BO_ 2499761675 10;
BA_ "VFrameFormat" BO_ 2499761675 3;
BA_ "GenMsgCycleTime" BO_ 2499750411 50;
BA_ "GenMsgStartDelayTime" BO_ 2499750411 15;
BA_ "VFrameFormat" BO_ 2499750411 3;
BA_ "GenMsgCycleTime" BO_ 2566767627 100;
BA_ "GenMsgStartDelayTime" BO_ 2566767627 35;
BA_ "VFrameFormat" BO_ 2566767627 3;
BA_ "GenMsgCycleTime" BO_ 2566831883 40;
BA_ "GenMsgStartDelayTime" BO_ 2566831883 30;
BA_ "VFrameFormat" BO_ 2566831883 3;
BA_ "GenSigCycleTime" SG_ 2566898187 Trailer2CalibInfo_LoadRange_ISig 100;
BA_ "GenSigCycleTimeActive" SG_ 2566898187 Trailer2CalibInfo_LoadRange_ISig 100;
BA_ "GenSigMaxLatency" SG_ 2566898187 Trailer2CalibInfo_LoadRange_ISig 1220;
BA_ "SystemSignalLongSymbol" SG_ 2566898187 Trailer2CalibInfo_LoadRange_ISig "Trailer2CalibInfo_LoadRange_ISig_3";
BA_ "GenSigCycleTime" SG_ 2566898187 Trailer2CalibInfo_CalibUsage_ISi 100;
BA_ "GenSigCycleTimeActive" SG_ 2566898187 Trailer2CalibInfo_CalibUsage_ISi 100;
BA_ "SystemSignalLongSymbol" SG_ 2566898187 Trailer2CalibInfo_CalibUsage_ISi "Trailer2CalibInfo_CalibUsage_ISig_3";
BA_ "GenSigCycleTime" SG_ 2566898187 Trailer2CalibInfo_UncalibLoad_IS 100;
BA_ "GenSigCycleTimeActive" SG_ 2566898187 Trailer2CalibInfo_UncalibLoad_IS 100;
BA_ "GenSigStartValue" SG_ 2566898187 Trailer2CalibInfo_UncalibLoad_IS 65535;
BA_ "GenSigMaxLatency" SG_ 2566898187 Trailer2CalibInfo_UncalibLoad_IS 1220;
BA_ "SystemSignalLongSymbol" SG_ 2566898187 Trailer2CalibInfo_UncalibLoad_IS "Trailer2CalibInfo_UncalibLoad_ISig_3";
BA_ "GenSigCycleTime" SG_ 2566898187 Trailer2CalibInfo_ScaleLoad_ISig 100;
BA_ "GenSigCycleTimeActive" SG_ 2566898187 Trailer2CalibInfo_ScaleLoad_ISig 100;
BA_ "GenSigStartValue" SG_ 2566898187 Trailer2CalibInfo_ScaleLoad_ISig 65535;
BA_ "GenSigMaxLatency" SG_ 2566898187 Trailer2CalibInfo_ScaleLoad_ISig 1220;
BA_ "SystemSignalLongSymbol" SG_ 2566898187 Trailer2CalibInfo_ScaleLoad_ISig "Trailer2CalibInfo_ScaleLoad_ISig_3";
BA_ "GenSigCycleTime" SG_ 2566898187 Trailer2CalibInfo_DataStorage_IS 100;
BA_ "GenSigCycleTimeActive" SG_ 2566898187 Trailer2CalibInfo_DataStorage_IS 100;
BA_ "GenSigStartValue" SG_ 2566898187 Trailer2CalibInfo_DataStorage_IS 3;
BA_ "SystemSignalLongSymbol" SG_ 2566898187 Trailer2CalibInfo_DataStorage_IS "Trailer2CalibInfo_DataStorage_ISig_3";
BA_ "GenSigCycleTime" SG_ 2566898187 Trailer2CalibInfo_AxleId_ISig_3 100;
BA_ "GenSigCycleTimeActive" SG_ 2566898187 Trailer2CalibInfo_AxleId_ISig_3 100;
BA_ "GenSigMaxLatency" SG_ 2566898187 Trailer2CalibInfo_AxleId_ISig_3 1220;
BA_ "GenSigCycleTime" SG_ 2566898187 Trailer2CalibInfo_Year_ISig_3 100;
BA_ "GenSigCycleTimeActive" SG_ 2566898187 Trailer2CalibInfo_Year_ISig_3 100;
BA_ "GenSigStartValue" SG_ 2566898187 Trailer2CalibInfo_Year_ISig_3 255;
BA_ "GenSigMaxLatency" SG_ 2566898187 Trailer2CalibInfo_Year_ISig_3 1220;
BA_ "GenSigCycleTime" SG_ 2566898187 Trailer2CalibInfo_Month_ISig_3 100;
BA_ "GenSigCycleTimeActive" SG_ 2566898187 Trailer2CalibInfo_Month_ISig_3 100;
BA_ "GenSigStartValue" SG_ 2566898187 Trailer2CalibInfo_Month_ISig_3 255;
BA_ "GenSigMaxLatency" SG_ 2566898187 Trailer2CalibInfo_Month_ISig_3 1220;
BA_ "GenSigCycleTime" SG_ 2566897931 Trailer1CalibInfo_CalibUsage_ISi 100;
BA_ "GenSigCycleTimeActive" SG_ 2566897931 Trailer1CalibInfo_CalibUsage_ISi 100;
BA_ "SystemSignalLongSymbol" SG_ 2566897931 Trailer1CalibInfo_CalibUsage_ISi "Trailer1CalibInfo_CalibUsage_ISig_3";
BA_ "GenSigCycleTime" SG_ 2566897931 Trailer1CalibInfo_ScaleLoad_ISig 100;
BA_ "GenSigCycleTimeActive" SG_ 2566897931 Trailer1CalibInfo_ScaleLoad_ISig 100;
BA_ "GenSigStartValue" SG_ 2566897931 Trailer1CalibInfo_ScaleLoad_ISig 65535;
BA_ "GenSigMaxLatency" SG_ 2566897931 Trailer1CalibInfo_ScaleLoad_ISig 1210;
BA_ "SystemSignalLongSymbol" SG_ 2566897931 Trailer1CalibInfo_ScaleLoad_ISig "Trailer1CalibInfo_ScaleLoad_ISig_3";
BA_ "GenSigCycleTime" SG_ 2566897931 Trailer1CalibInfo_DataStorage_IS 100;
BA_ "GenSigCycleTimeActive" SG_ 2566897931 Trailer1CalibInfo_DataStorage_IS 100;
BA_ "GenSigStartValue" SG_ 2566897931 Trailer1CalibInfo_DataStorage_IS 3;
BA_ "SystemSignalLongSymbol" SG_ 2566897931 Trailer1CalibInfo_DataStorage_IS "Trailer1CalibInfo_DataStorage_ISig_3";
BA_ "GenSigCycleTime" SG_ 2566897931 Trailer1CalibInfo_Month_ISig_3 100;
BA_ "GenSigCycleTimeActive" SG_ 2566897931 Trailer1CalibInfo_Month_ISig_3 100;
BA_ "GenSigStartValue" SG_ 2566897931 Trailer1CalibInfo_Month_ISig_3 255;
BA_ "GenSigMaxLatency" SG_ 2566897931 Trailer1CalibInfo_Month_ISig_3 1210;
BA_ "GenSigCycleTime" SG_ 2566897931 Trailer1CalibInfo_LoadRange_ISig 100;
BA_ "GenSigCycleTimeActive" SG_ 2566897931 Trailer1CalibInfo_LoadRange_ISig 100;
BA_ "GenSigMaxLatency" SG_ 2566897931 Trailer1CalibInfo_LoadRange_ISig 1210;
BA_ "SystemSignalLongSymbol" SG_ 2566897931 Trailer1CalibInfo_LoadRange_ISig "Trailer1CalibInfo_LoadRange_ISig_3";
BA_ "GenSigCycleTime" SG_ 2566897931 Trailer1CalibInfo_AxleId_ISig_3 100;
BA_ "GenSigCycleTimeActive" SG_ 2566897931 Trailer1CalibInfo_AxleId_ISig_3 100;
BA_ "GenSigMaxLatency" SG_ 2566897931 Trailer1CalibInfo_AxleId_ISig_3 1210;
BA_ "GenSigCycleTime" SG_ 2566897931 Trailer1CalibInfo_UncalibLoad_IS 100;
BA_ "GenSigCycleTimeActive" SG_ 2566897931 Trailer1CalibInfo_UncalibLoad_IS 100;
BA_ "GenSigStartValue" SG_ 2566897931 Trailer1CalibInfo_UncalibLoad_IS 65535;
BA_ "GenSigMaxLatency" SG_ 2566897931 Trailer1CalibInfo_UncalibLoad_IS 1210;
BA_ "SystemSignalLongSymbol" SG_ 2566897931 Trailer1CalibInfo_UncalibLoad_IS "Trailer1CalibInfo_UncalibLoad_ISig_3";
BA_ "GenSigCycleTime" SG_ 2566897931 Trailer1CalibInfo_Year_ISig_3 100;
BA_ "GenSigCycleTimeActive" SG_ 2566897931 Trailer1CalibInfo_Year_ISig_3 100;
BA_ "GenSigStartValue" SG_ 2566897931 Trailer1CalibInfo_Year_ISig_3 255;
BA_ "GenSigMaxLatency" SG_ 2566897931 Trailer1CalibInfo_Year_ISig_3 1210;
BA_ "GenSigCycleTime" SG_ 2566878475 Trailer5BrkLining_Wear_ISig_3 100;
BA_ "GenSigCycleTimeActive" SG_ 2566878475 Trailer5BrkLining_Wear_ISig_3 100;
BA_ "GenSigStartValue" SG_ 2566878475 Trailer5BrkLining_Wear_ISig_3 255;
BA_ "GenSigMaxLatency" SG_ 2566878475 Trailer5BrkLining_Wear_ISig_3 100;
BA_ "GenSigCycleTime" SG_ 2566878475 Trailer5RampLevel_LvlPos_ISig_3 100;
BA_ "GenSigCycleTimeActive" SG_ 2566878475 Trailer5RampLevel_LvlPos_ISig_3 100;
BA_ "GenSigStartValue" SG_ 2566878475 Trailer5RampLevel_LvlPos_ISig_3 3;
BA_ "GenSigMaxLatency" SG_ 2566878475 Trailer5RampLevel_LvlPos_ISig_3 150;
BA_ "GenSigCycleTime" SG_ 2566878475 Trailer5RampLevel_LvlStatus_ISig 100;
BA_ "GenSigCycleTimeActive" SG_ 2566878475 Trailer5RampLevel_LvlStatus_ISig 100;
BA_ "GenSigStartValue" SG_ 2566878475 Trailer5RampLevel_LvlStatus_ISig 3;
BA_ "GenSigMaxLatency" SG_ 2566878475 Trailer5RampLevel_LvlStatus_ISig 150;
BA_ "SystemSignalLongSymbol" SG_ 2566878475 Trailer5RampLevel_LvlStatus_ISig "Trailer5RampLevel_LvlStatus_ISig_3";
BA_ "GenSigCycleTime" SG_ 2566878475 Trailer5RelBodyLevel_FrontLevel 100;
BA_ "GenSigCycleTimeActive" SG_ 2566878475 Trailer5RelBodyLevel_FrontLevel 100;
BA_ "GenSigStartValue" SG_ 2566878475 Trailer5RelBodyLevel_FrontLevel 65535;
BA_ "GenSigMaxLatency" SG_ 2566878475 Trailer5RelBodyLevel_FrontLevel 150;
BA_ "GenSigCycleTime" SG_ 2566878475 Trailer5NormalLevel_LvlPos_ISig_ 100;
BA_ "GenSigCycleTimeActive" SG_ 2566878475 Trailer5NormalLevel_LvlPos_ISig_ 100;
BA_ "GenSigStartValue" SG_ 2566878475 Trailer5NormalLevel_LvlPos_ISig_ 3;
BA_ "GenSigMaxLatency" SG_ 2566878475 Trailer5NormalLevel_LvlPos_ISig_ 150;
BA_ "SystemSignalLongSymbol" SG_ 2566878475 Trailer5NormalLevel_LvlPos_ISig_ "Trailer5NormalLevel_LvlPos_ISig_3";
BA_ "GenSigCycleTime" SG_ 2566878475 Trailer5BrkLining_BrkLnTireId_IS 100;
BA_ "GenSigCycleTimeActive" SG_ 2566878475 Trailer5BrkLining_BrkLnTireId_IS 100;
BA_ "GenSigMaxLatency" SG_ 2566878475 Trailer5BrkLining_BrkLnTireId_IS 100;
BA_ "SystemSignalLongSymbol" SG_ 2566878475 Trailer5BrkLining_BrkLnTireId_IS "Trailer5BrkLining_BrkLnTireId_ISig_3";
BA_ "GenSigCycleTime" SG_ 2566878475 Trailer5RelBodyLevel_RearLevel 100;
BA_ "GenSigCycleTimeActive" SG_ 2566878475 Trailer5RelBodyLevel_RearLevel 100;
BA_ "GenSigStartValue" SG_ 2566878475 Trailer5RelBodyLevel_RearLevel 65535;
BA_ "GenSigMaxLatency" SG_ 2566878475 Trailer5RelBodyLevel_RearLevel 150;
BA_ "GenSigCycleTime" SG_ 2566878475 Trailer5BrkLining_Warning_ISig_3 100;
BA_ "GenSigCycleTimeActive" SG_ 2566878475 Trailer5BrkLining_Warning_ISig_3 100;
BA_ "GenSigStartValue" SG_ 2566878475 Trailer5BrkLining_Warning_ISig_3 3;
BA_ "GenSigMaxLatency" SG_ 2566878475 Trailer5BrkLining_Warning_ISig_3 100;
BA_ "GenSigCycleTime" SG_ 2566878475 Trailer5NormalLevel_LvlStatus_IS 100;
BA_ "GenSigCycleTimeActive" SG_ 2566878475 Trailer5NormalLevel_LvlStatus_IS 100;
BA_ "GenSigStartValue" SG_ 2566878475 Trailer5NormalLevel_LvlStatus_IS 3;
BA_ "GenSigMaxLatency" SG_ 2566878475 Trailer5NormalLevel_LvlStatus_IS 150;
BA_ "SystemSignalLongSymbol" SG_ 2566878475 Trailer5NormalLevel_LvlStatus_IS "Trailer5NormalLevel_LvlStatus_ISig_3";
BA_ "GenSigCycleTime" SG_ 2566878219 Trailer4RelBodyLevel_RearLevel 100;
BA_ "GenSigCycleTimeActive" SG_ 2566878219 Trailer4RelBodyLevel_RearLevel 100;
BA_ "GenSigStartValue" SG_ 2566878219 Trailer4RelBodyLevel_RearLevel 65535;
BA_ "GenSigMaxLatency" SG_ 2566878219 Trailer4RelBodyLevel_RearLevel 140;
BA_ "GenSigCycleTime" SG_ 2566878219 Trailer4BrkLining_Warning_ISig_3 100;
BA_ "GenSigCycleTimeActive" SG_ 2566878219 Trailer4BrkLining_Warning_ISig_3 100;
BA_ "GenSigStartValue" SG_ 2566878219 Trailer4BrkLining_Warning_ISig_3 3;
BA_ "GenSigMaxLatency" SG_ 2566878219 Trailer4BrkLining_Warning_ISig_3 100;
BA_ "GenSigCycleTime" SG_ 2566878219 Trailer4NormalLevel_LvlPos_ISig_ 100;
BA_ "GenSigCycleTimeActive" SG_ 2566878219 Trailer4NormalLevel_LvlPos_ISig_ 100;
BA_ "GenSigStartValue" SG_ 2566878219 Trailer4NormalLevel_LvlPos_ISig_ 3;
BA_ "GenSigMaxLatency" SG_ 2566878219 Trailer4NormalLevel_LvlPos_ISig_ 140;
BA_ "SystemSignalLongSymbol" SG_ 2566878219 Trailer4NormalLevel_LvlPos_ISig_ "Trailer4NormalLevel_LvlPos_ISig_3";
BA_ "GenSigCycleTime" SG_ 2566878219 Trailer4RelBodyLevel_FrontLevel 100;
BA_ "GenSigCycleTimeActive" SG_ 2566878219 Trailer4RelBodyLevel_FrontLevel 100;
BA_ "GenSigStartValue" SG_ 2566878219 Trailer4RelBodyLevel_FrontLevel 65535;
BA_ "GenSigMaxLatency" SG_ 2566878219 Trailer4RelBodyLevel_FrontLevel 140;
BA_ "GenSigCycleTime" SG_ 2566878219 Trailer4RampLevel_LvlPos_ISig_3 100;
BA_ "GenSigCycleTimeActive" SG_ 2566878219 Trailer4RampLevel_LvlPos_ISig_3 100;
BA_ "GenSigStartValue" SG_ 2566878219 Trailer4RampLevel_LvlPos_ISig_3 3;
BA_ "GenSigMaxLatency" SG_ 2566878219 Trailer4RampLevel_LvlPos_ISig_3 140;
BA_ "GenSigCycleTime" SG_ 2566878219 Trailer4RampLevel_LvlStatus_ISig 100;
BA_ "GenSigCycleTimeActive" SG_ 2566878219 Trailer4RampLevel_LvlStatus_ISig 100;
BA_ "GenSigStartValue" SG_ 2566878219 Trailer4RampLevel_LvlStatus_ISig 3;
BA_ "GenSigMaxLatency" SG_ 2566878219 Trailer4RampLevel_LvlStatus_ISig 140;
BA_ "SystemSignalLongSymbol" SG_ 2566878219 Trailer4RampLevel_LvlStatus_ISig "Trailer4RampLevel_LvlStatus_ISig_3";
BA_ "GenSigCycleTime" SG_ 2566878219 Trailer4BrkLining_Wear_ISig_3 100;
BA_ "GenSigCycleTimeActive" SG_ 2566878219 Trailer4BrkLining_Wear_ISig_3 100;
BA_ "GenSigStartValue" SG_ 2566878219 Trailer4BrkLining_Wear_ISig_3 255;
BA_ "GenSigMaxLatency" SG_ 2566878219 Trailer4BrkLining_Wear_ISig_3 100;
BA_ "GenSigCycleTime" SG_ 2566878219 Trailer4NormalLevel_LvlStatus_IS 100;
BA_ "GenSigCycleTimeActive" SG_ 2566878219 Trailer4NormalLevel_LvlStatus_IS 100;
BA_ "GenSigStartValue" SG_ 2566878219 Trailer4NormalLevel_LvlStatus_IS 3;
BA_ "GenSigMaxLatency" SG_ 2566878219 Trailer4NormalLevel_LvlStatus_IS 140;
BA_ "SystemSignalLongSymbol" SG_ 2566878219 Trailer4NormalLevel_LvlStatus_IS "Trailer4NormalLevel_LvlStatus_ISig_3";
BA_ "GenSigCycleTime" SG_ 2566878219 Trailer4BrkLining_BrkLnTireId_IS 100;
BA_ "GenSigCycleTimeActive" SG_ 2566878219 Trailer4BrkLining_BrkLnTireId_IS 100;
BA_ "GenSigMaxLatency" SG_ 2566878219 Trailer4BrkLining_BrkLnTireId_IS 100;
BA_ "SystemSignalLongSymbol" SG_ 2566878219 Trailer4BrkLining_BrkLnTireId_IS "Trailer4BrkLining_BrkLnTireId_ISig_3";
BA_ "GenSigCycleTime" SG_ 2566877963 Trailer3RampLevel_LvlStatus_ISig 100;
BA_ "GenSigCycleTimeActive" SG_ 2566877963 Trailer3RampLevel_LvlStatus_ISig 100;
BA_ "GenSigStartValue" SG_ 2566877963 Trailer3RampLevel_LvlStatus_ISig 3;
BA_ "GenSigMaxLatency" SG_ 2566877963 Trailer3RampLevel_LvlStatus_ISig 130;
BA_ "SystemSignalLongSymbol" SG_ 2566877963 Trailer3RampLevel_LvlStatus_ISig "Trailer3RampLevel_LvlStatus_ISig_3";
BA_ "GenSigCycleTime" SG_ 2566877963 Trailer3RelBodyLevel_FrontLevel 100;
BA_ "GenSigCycleTimeActive" SG_ 2566877963 Trailer3RelBodyLevel_FrontLevel 100;
BA_ "GenSigStartValue" SG_ 2566877963 Trailer3RelBodyLevel_FrontLevel 65535;
BA_ "GenSigMaxLatency" SG_ 2566877963 Trailer3RelBodyLevel_FrontLevel 130;
BA_ "GenSigCycleTime" SG_ 2566877963 Trailer3RampLevel_LvlPos_ISig_3 100;
BA_ "GenSigCycleTimeActive" SG_ 2566877963 Trailer3RampLevel_LvlPos_ISig_3 100;
BA_ "GenSigStartValue" SG_ 2566877963 Trailer3RampLevel_LvlPos_ISig_3 3;
BA_ "GenSigMaxLatency" SG_ 2566877963 Trailer3RampLevel_LvlPos_ISig_3 130;
BA_ "GenSigCycleTime" SG_ 2566877963 Trailer3BrkLining_BrkLnTireId_IS 100;
BA_ "GenSigCycleTimeActive" SG_ 2566877963 Trailer3BrkLining_BrkLnTireId_IS 100;
BA_ "GenSigMaxLatency" SG_ 2566877963 Trailer3BrkLining_BrkLnTireId_IS 100;
BA_ "SystemSignalLongSymbol" SG_ 2566877963 Trailer3BrkLining_BrkLnTireId_IS "Trailer3BrkLining_BrkLnTireId_ISig_3";
BA_ "GenSigCycleTime" SG_ 2566877963 Trailer3BrkLining_Wear_ISig_3 100;
BA_ "GenSigCycleTimeActive" SG_ 2566877963 Trailer3BrkLining_Wear_ISig_3 100;
BA_ "GenSigStartValue" SG_ 2566877963 Trailer3BrkLining_Wear_ISig_3 255;
BA_ "GenSigMaxLatency" SG_ 2566877963 Trailer3BrkLining_Wear_ISig_3 100;
BA_ "GenSigCycleTime" SG_ 2566877963 Trailer3RelBodyLevel_RearLevel 100;
BA_ "GenSigCycleTimeActive" SG_ 2566877963 Trailer3RelBodyLevel_RearLevel 100;
BA_ "GenSigStartValue" SG_ 2566877963 Trailer3RelBodyLevel_RearLevel 65535;
BA_ "GenSigMaxLatency" SG_ 2566877963 Trailer3RelBodyLevel_RearLevel 130;
BA_ "GenSigCycleTime" SG_ 2566877963 Trailer3NormalLevel_LvlStatus_IS 100;
BA_ "GenSigCycleTimeActive" SG_ 2566877963 Trailer3NormalLevel_LvlStatus_IS 100;
BA_ "GenSigStartValue" SG_ 2566877963 Trailer3NormalLevel_LvlStatus_IS 3;
BA_ "GenSigMaxLatency" SG_ 2566877963 Trailer3NormalLevel_LvlStatus_IS 130;
BA_ "SystemSignalLongSymbol" SG_ 2566877963 Trailer3NormalLevel_LvlStatus_IS "Trailer3NormalLevel_LvlStatus_ISig_3";
BA_ "GenSigCycleTime" SG_ 2566877963 Trailer3BrkLining_Warning_ISig_3 100;
BA_ "GenSigCycleTimeActive" SG_ 2566877963 Trailer3BrkLining_Warning_ISig_3 100;
BA_ "GenSigStartValue" SG_ 2566877963 Trailer3BrkLining_Warning_ISig_3 3;
BA_ "GenSigMaxLatency" SG_ 2566877963 Trailer3BrkLining_Warning_ISig_3 100;
BA_ "GenSigCycleTime" SG_ 2566877963 Trailer3NormalLevel_LvlPos_ISig_ 100;
BA_ "GenSigCycleTimeActive" SG_ 2566877963 Trailer3NormalLevel_LvlPos_ISig_ 100;
BA_ "GenSigStartValue" SG_ 2566877963 Trailer3NormalLevel_LvlPos_ISig_ 3;
BA_ "GenSigMaxLatency" SG_ 2566877963 Trailer3NormalLevel_LvlPos_ISig_ 130;
BA_ "SystemSignalLongSymbol" SG_ 2566877963 Trailer3NormalLevel_LvlPos_ISig_ "Trailer3NormalLevel_LvlPos_ISig_3";
BA_ "GenSigCycleTime" SG_ 2566877707 Trailer2BrkLining_BrkLnTireId_IS 100;
BA_ "GenSigCycleTimeActive" SG_ 2566877707 Trailer2BrkLining_BrkLnTireId_IS 100;
BA_ "GenSigMaxLatency" SG_ 2566877707 Trailer2BrkLining_BrkLnTireId_IS 100;
BA_ "SystemSignalLongSymbol" SG_ 2566877707 Trailer2BrkLining_BrkLnTireId_IS "Trailer2BrkLining_BrkLnTireId_ISig_3";
BA_ "GenSigCycleTime" SG_ 2566877707 Trailer2NormalLevel_LvlStatus_IS 100;
BA_ "GenSigCycleTimeActive" SG_ 2566877707 Trailer2NormalLevel_LvlStatus_IS 100;
BA_ "GenSigStartValue" SG_ 2566877707 Trailer2NormalLevel_LvlStatus_IS 3;
BA_ "GenSigMaxLatency" SG_ 2566877707 Trailer2NormalLevel_LvlStatus_IS 120;
BA_ "SystemSignalLongSymbol" SG_ 2566877707 Trailer2NormalLevel_LvlStatus_IS "Trailer2NormalLevel_LvlStatus_ISig_3";
BA_ "GenSigCycleTime" SG_ 2566877707 Trailer2BrkLining_Warning_ISig_3 100;
BA_ "GenSigCycleTimeActive" SG_ 2566877707 Trailer2BrkLining_Warning_ISig_3 100;
BA_ "GenSigStartValue" SG_ 2566877707 Trailer2BrkLining_Warning_ISig_3 3;
BA_ "GenSigMaxLatency" SG_ 2566877707 Trailer2BrkLining_Warning_ISig_3 100;
BA_ "GenSigCycleTime" SG_ 2566877707 Trailer2NormalLevel_LvlPos_ISig_ 100;
BA_ "GenSigCycleTimeActive" SG_ 2566877707 Trailer2NormalLevel_LvlPos_ISig_ 100;
BA_ "GenSigStartValue" SG_ 2566877707 Trailer2NormalLevel_LvlPos_ISig_ 3;
BA_ "GenSigMaxLatency" SG_ 2566877707 Trailer2NormalLevel_LvlPos_ISig_ 120;
BA_ "SystemSignalLongSymbol" SG_ 2566877707 Trailer2NormalLevel_LvlPos_ISig_ "Trailer2NormalLevel_LvlPos_ISig_3";
BA_ "GenSigCycleTime" SG_ 2566877707 Trailer2RelBodyLevel_FrontLevel 100;
BA_ "GenSigCycleTimeActive" SG_ 2566877707 Trailer2RelBodyLevel_FrontLevel 100;
BA_ "GenSigStartValue" SG_ 2566877707 Trailer2RelBodyLevel_FrontLevel 65535;
BA_ "GenSigMaxLatency" SG_ 2566877707 Trailer2RelBodyLevel_FrontLevel 120;
BA_ "GenSigCycleTime" SG_ 2566877707 Trailer2RelBodyLevel_RearLevel 100;
BA_ "GenSigCycleTimeActive" SG_ 2566877707 Trailer2RelBodyLevel_RearLevel 100;
BA_ "GenSigStartValue" SG_ 2566877707 Trailer2RelBodyLevel_RearLevel 65535;
BA_ "GenSigMaxLatency" SG_ 2566877707 Trailer2RelBodyLevel_RearLevel 120;
BA_ "GenSigCycleTime" SG_ 2566877707 Trailer2RampLevel_LvlStatus_ISig 100;
BA_ "GenSigCycleTimeActive" SG_ 2566877707 Trailer2RampLevel_LvlStatus_ISig 100;
BA_ "GenSigStartValue" SG_ 2566877707 Trailer2RampLevel_LvlStatus_ISig 3;
BA_ "GenSigMaxLatency" SG_ 2566877707 Trailer2RampLevel_LvlStatus_ISig 120;
BA_ "SystemSignalLongSymbol" SG_ 2566877707 Trailer2RampLevel_LvlStatus_ISig "Trailer2RampLevel_LvlStatus_ISig_3";
BA_ "GenSigCycleTime" SG_ 2566877707 Trailer2RampLevel_LvlPos_ISig_3 100;
BA_ "GenSigCycleTimeActive" SG_ 2566877707 Trailer2RampLevel_LvlPos_ISig_3 100;
BA_ "GenSigStartValue" SG_ 2566877707 Trailer2RampLevel_LvlPos_ISig_3 3;
BA_ "GenSigMaxLatency" SG_ 2566877707 Trailer2RampLevel_LvlPos_ISig_3 120;
BA_ "GenSigCycleTime" SG_ 2566877707 Trailer2BrkLining_Wear_ISig_3 100;
BA_ "GenSigCycleTimeActive" SG_ 2566877707 Trailer2BrkLining_Wear_ISig_3 100;
BA_ "GenSigStartValue" SG_ 2566877707 Trailer2BrkLining_Wear_ISig_3 255;
BA_ "GenSigMaxLatency" SG_ 2566877707 Trailer2BrkLining_Wear_ISig_3 100;
BA_ "GenSigCycleTime" SG_ 2566877451 Trailer1RelBodyLevel_RearLevel 100;
BA_ "GenSigCycleTimeActive" SG_ 2566877451 Trailer1RelBodyLevel_RearLevel 100;
BA_ "GenSigStartValue" SG_ 2566877451 Trailer1RelBodyLevel_RearLevel 65535;
BA_ "GenSigMaxLatency" SG_ 2566877451 Trailer1RelBodyLevel_RearLevel 110;
BA_ "GenSigCycleTime" SG_ 2566877451 Trailer1NormalLevel_LvlPos_ISig_ 100;
BA_ "GenSigCycleTimeActive" SG_ 2566877451 Trailer1NormalLevel_LvlPos_ISig_ 100;
BA_ "GenSigStartValue" SG_ 2566877451 Trailer1NormalLevel_LvlPos_ISig_ 3;
BA_ "GenSigMaxLatency" SG_ 2566877451 Trailer1NormalLevel_LvlPos_ISig_ 110;
BA_ "SystemSignalLongSymbol" SG_ 2566877451 Trailer1NormalLevel_LvlPos_ISig_ "Trailer1NormalLevel_LvlPos_ISig_3";
BA_ "GenSigCycleTime" SG_ 2566877451 Trailer1NormalLevel_LvlStatus_IS 100;
BA_ "GenSigCycleTimeActive" SG_ 2566877451 Trailer1NormalLevel_LvlStatus_IS 100;
BA_ "GenSigStartValue" SG_ 2566877451 Trailer1NormalLevel_LvlStatus_IS 3;
BA_ "GenSigMaxLatency" SG_ 2566877451 Trailer1NormalLevel_LvlStatus_IS 110;
BA_ "SystemSignalLongSymbol" SG_ 2566877451 Trailer1NormalLevel_LvlStatus_IS "Trailer1NormalLevel_LvlStatus_ISig_3";
BA_ "GenSigCycleTime" SG_ 2566877451 Trailer1RampLevel_LvlPos_ISig_3 100;
BA_ "GenSigCycleTimeActive" SG_ 2566877451 Trailer1RampLevel_LvlPos_ISig_3 100;
BA_ "GenSigStartValue" SG_ 2566877451 Trailer1RampLevel_LvlPos_ISig_3 3;
BA_ "GenSigMaxLatency" SG_ 2566877451 Trailer1RampLevel_LvlPos_ISig_3 110;
BA_ "GenSigCycleTime" SG_ 2566877451 Trailer1BrkLining_Warning_ISig_3 100;
BA_ "GenSigCycleTimeActive" SG_ 2566877451 Trailer1BrkLining_Warning_ISig_3 100;
BA_ "GenSigStartValue" SG_ 2566877451 Trailer1BrkLining_Warning_ISig_3 3;
BA_ "GenSigMaxLatency" SG_ 2566877451 Trailer1BrkLining_Warning_ISig_3 100;
BA_ "GenSigCycleTime" SG_ 2566877451 Trailer1RampLevel_LvlStatus_ISig 100;
BA_ "GenSigCycleTimeActive" SG_ 2566877451 Trailer1RampLevel_LvlStatus_ISig 100;
BA_ "GenSigStartValue" SG_ 2566877451 Trailer1RampLevel_LvlStatus_ISig 3;
BA_ "GenSigMaxLatency" SG_ 2566877451 Trailer1RampLevel_LvlStatus_ISig 110;
BA_ "SystemSignalLongSymbol" SG_ 2566877451 Trailer1RampLevel_LvlStatus_ISig "Trailer1RampLevel_LvlStatus_ISig_3";
BA_ "GenSigCycleTime" SG_ 2566877451 Trailer1BrkLining_BrkLnTireId_IS 100;
BA_ "GenSigCycleTimeActive" SG_ 2566877451 Trailer1BrkLining_BrkLnTireId_IS 100;
BA_ "GenSigMaxLatency" SG_ 2566877451 Trailer1BrkLining_BrkLnTireId_IS 100;
BA_ "SystemSignalLongSymbol" SG_ 2566877451 Trailer1BrkLining_BrkLnTireId_IS "Trailer1BrkLining_BrkLnTireId_ISig_3";
BA_ "GenSigCycleTime" SG_ 2566877451 Trailer1BrkLining_Wear_ISig_3 100;
BA_ "GenSigCycleTimeActive" SG_ 2566877451 Trailer1BrkLining_Wear_ISig_3 100;
BA_ "GenSigStartValue" SG_ 2566877451 Trailer1BrkLining_Wear_ISig_3 255;
BA_ "GenSigMaxLatency" SG_ 2566877451 Trailer1BrkLining_Wear_ISig_3 100;
BA_ "GenSigCycleTime" SG_ 2566877451 Trailer1RelBodyLevel_FrontLevel 100;
BA_ "GenSigCycleTimeActive" SG_ 2566877451 Trailer1RelBodyLevel_FrontLevel 100;
BA_ "GenSigStartValue" SG_ 2566877451 Trailer1RelBodyLevel_FrontLevel 65535;
BA_ "GenSigMaxLatency" SG_ 2566877451 Trailer1RelBodyLevel_FrontLevel 110;
BA_ "GenSigCycleTime" SG_ 2566894859 Trailer5VIN_ISig_3 100;
BA_ "GenSigCycleTimeActive" SG_ 2566894859 Trailer5VIN_ISig_3 100;
BA_ "GenSigMaxLatency" SG_ 2566894859 Trailer5VIN_ISig_3 10000;
BA_ "GenSigCycleTime" SG_ 2566894603 Trailer4VIN_ISig_3 100;
BA_ "GenSigCycleTimeActive" SG_ 2566894603 Trailer4VIN_ISig_3 100;
BA_ "GenSigMaxLatency" SG_ 2566894603 Trailer4VIN_ISig_3 10000;
BA_ "GenSigCycleTime" SG_ 2566894347 Trailer3VIN_ISig_3 100;
BA_ "GenSigCycleTimeActive" SG_ 2566894347 Trailer3VIN_ISig_3 100;
BA_ "GenSigMaxLatency" SG_ 2566894347 Trailer3VIN_ISig_3 10000;
BA_ "GenSigCycleTime" SG_ 2566894091 Trailer2VIN_ISig_3 100;
BA_ "GenSigCycleTimeActive" SG_ 2566894091 Trailer2VIN_ISig_3 100;
BA_ "GenSigMaxLatency" SG_ 2566894091 Trailer2VIN_ISig_3 10000;
BA_ "GenSigCycleTime" SG_ 2566893835 Trailer1VIN_ISig_3 100;
BA_ "GenSigCycleTimeActive" SG_ 2566893835 Trailer1VIN_ISig_3 100;
BA_ "GenSigMaxLatency" SG_ 2566893835 Trailer1VIN_ISig_3 10000;
BA_ "GenSigCycleTime" SG_ 2566903051 Trailer5GeometricData_Index_ISig 100;
BA_ "GenSigCycleTimeActive" SG_ 2566903051 Trailer5GeometricData_Index_ISig 100;
BA_ "GenSigStartValue" SG_ 2566903051 Trailer5GeometricData_Index_ISig 255;
BA_ "GenSigMaxLatency" SG_ 2566903051 Trailer5GeometricData_Index_ISig 1010;
BA_ "Platform_VMCU1_Sig" SG_ 2566903051 Trailer5GeometricData_Index_ISig 1;
BA_ "SystemSignalLongSymbol" SG_ 2566903051 Trailer5GeometricData_Index_ISig "Trailer5GeometricData_Index_ISig_3";
BA_ "GenSigCycleTime" SG_ 2566903051 PadChangePredictionAxleNumber 100;
BA_ "GenSigCycleTimeActive" SG_ 2566903051 PadChangePredictionAxleNumber 100;
BA_ "GenSigStartValue" SG_ 2566903051 PadChangePredictionAxleNumber 7;
BA_ "Platform_VMCU1_Sig" SG_ 2566903051 PadChangePredictionAxleNumber 1;
BA_ "GenSigCycleTime" SG_ 2566903051 XBRBrakingCapacityTime 100;
BA_ "GenSigCycleTimeActive" SG_ 2566903051 XBRBrakingCapacityTime 100;
BA_ "GenSigStartValue" SG_ 2566903051 XBRBrakingCapacityTime 255;
BA_ "Platform_VMCU1_Sig" SG_ 2566903051 XBRBrakingCapacityTime 1;
BA_ "GenSigCycleTime" SG_ 2566903051 Trailer5AxleLoadSum_ISig_3 100;
BA_ "GenSigCycleTimeActive" SG_ 2566903051 Trailer5AxleLoadSum_ISig_3 100;
BA_ "GenSigStartValue" SG_ 2566903051 Trailer5AxleLoadSum_ISig_3 65535;
BA_ "GenSigMaxLatency" SG_ 2566903051 Trailer5AxleLoadSum_ISig_3 500;
BA_ "Platform_VMCU1_Sig" SG_ 2566903051 Trailer5AxleLoadSum_ISig_3 1;
BA_ "GenSigCycleTime" SG_ 2566903051 XBRBrakingCapacityTemperature 100;
BA_ "GenSigCycleTimeActive" SG_ 2566903051 XBRBrakingCapacityTemperature 100;
BA_ "GenSigStartValue" SG_ 2566903051 XBRBrakingCapacityTemperature 255;
BA_ "Platform_VMCU1_Sig" SG_ 2566903051 XBRBrakingCapacityTemperature 1;
BA_ "GenSigCycleTime" SG_ 2566903051 Trailer5GeometricData_Content_IS 100;
BA_ "GenSigCycleTimeActive" SG_ 2566903051 Trailer5GeometricData_Content_IS 100;
BA_ "GenSigStartValue" SG_ 2566903051 Trailer5GeometricData_Content_IS 255;
BA_ "GenSigMaxLatency" SG_ 2566903051 Trailer5GeometricData_Content_IS 1010;
BA_ "Platform_VMCU1_Sig" SG_ 2566903051 Trailer5GeometricData_Content_IS 1;
BA_ "SystemSignalLongSymbol" SG_ 2566903051 Trailer5GeometricData_Content_IS "Trailer5GeometricData_Content_ISig_3";
BA_ "GenSigCycleTime" SG_ 2566903051 LiningWearWarning 100;
BA_ "GenSigCycleTimeActive" SG_ 2566903051 LiningWearWarning 100;
BA_ "GenSigStartValue" SG_ 2566903051 LiningWearWarning 3;
BA_ "Platform_VMCU1_Sig" SG_ 2566903051 LiningWearWarning 1;
BA_ "GenSigCycleTime" SG_ 2566902539 Trailer3GeometricData_Index_ISig 100;
BA_ "GenSigCycleTimeActive" SG_ 2566902539 Trailer3GeometricData_Index_ISig 100;
BA_ "GenSigStartValue" SG_ 2566902539 Trailer3GeometricData_Index_ISig 255;
BA_ "GenSigMaxLatency" SG_ 2566902539 Trailer3GeometricData_Index_ISig 1012;
BA_ "Platform_VMCU1_Sig" SG_ 2566902539 Trailer3GeometricData_Index_ISig 1;
BA_ "SystemSignalLongSymbol" SG_ 2566902539 Trailer3GeometricData_Index_ISig "Trailer3GeometricData_Index_ISig_3";
BA_ "GenSigCycleTime" SG_ 2566902539 Trailer4GeometricData_Content_IS 100;
BA_ "GenSigCycleTimeActive" SG_ 2566902539 Trailer4GeometricData_Content_IS 100;
BA_ "GenSigStartValue" SG_ 2566902539 Trailer4GeometricData_Content_IS 255;
BA_ "GenSigMaxLatency" SG_ 2566902539 Trailer4GeometricData_Content_IS 1012;
BA_ "Platform_VMCU1_Sig" SG_ 2566902539 Trailer4GeometricData_Content_IS 1;
BA_ "SystemSignalLongSymbol" SG_ 2566902539 Trailer4GeometricData_Content_IS "Trailer4GeometricData_Content_ISig_3";
BA_ "GenSigCycleTime" SG_ 2566902539 Trailer3GeometricData_Content_IS 100;
BA_ "GenSigCycleTimeActive" SG_ 2566902539 Trailer3GeometricData_Content_IS 100;
BA_ "GenSigStartValue" SG_ 2566902539 Trailer3GeometricData_Content_IS 255;
BA_ "GenSigMaxLatency" SG_ 2566902539 Trailer3GeometricData_Content_IS 1012;
BA_ "Platform_VMCU1_Sig" SG_ 2566902539 Trailer3GeometricData_Content_IS 1;
BA_ "SystemSignalLongSymbol" SG_ 2566902539 Trailer3GeometricData_Content_IS "Trailer3GeometricData_Content_ISig_3";
BA_ "GenSigCycleTime" SG_ 2566902539 Trailer3AxleLoadSum_ISig_3 100;
BA_ "GenSigCycleTimeActive" SG_ 2566902539 Trailer3AxleLoadSum_ISig_3 100;
BA_ "GenSigStartValue" SG_ 2566902539 Trailer3AxleLoadSum_ISig_3 65535;
BA_ "GenSigMaxLatency" SG_ 2566902539 Trailer3AxleLoadSum_ISig_3 1012;
BA_ "Platform_VMCU1_Sig" SG_ 2566902539 Trailer3AxleLoadSum_ISig_3 1;
BA_ "GenSigCycleTime" SG_ 2566902539 Trailer4GeometricData_Index_ISig 100;
BA_ "GenSigCycleTimeActive" SG_ 2566902539 Trailer4GeometricData_Index_ISig 100;
BA_ "GenSigStartValue" SG_ 2566902539 Trailer4GeometricData_Index_ISig 255;
BA_ "GenSigMaxLatency" SG_ 2566902539 Trailer4GeometricData_Index_ISig 1012;
BA_ "Platform_VMCU1_Sig" SG_ 2566902539 Trailer4GeometricData_Index_ISig 1;
BA_ "SystemSignalLongSymbol" SG_ 2566902539 Trailer4GeometricData_Index_ISig "Trailer4GeometricData_Index_ISig_3";
BA_ "GenSigCycleTime" SG_ 2566902539 Trailer4AxleLoadSum_ISig_3 100;
BA_ "GenSigCycleTimeActive" SG_ 2566902539 Trailer4AxleLoadSum_ISig_3 100;
BA_ "GenSigStartValue" SG_ 2566902539 Trailer4AxleLoadSum_ISig_3 65535;
BA_ "GenSigMaxLatency" SG_ 2566902539 Trailer4AxleLoadSum_ISig_3 1012;
BA_ "Platform_VMCU1_Sig" SG_ 2566902539 Trailer4AxleLoadSum_ISig_3 1;
BA_ "GenSigCycleTime" SG_ 2566902027 Trailer2GeometricData_Index_ISig 100;
BA_ "GenSigCycleTimeActive" SG_ 2566902027 Trailer2GeometricData_Index_ISig 100;
BA_ "GenSigStartValue" SG_ 2566902027 Trailer2GeometricData_Index_ISig 255;
BA_ "GenSigMaxLatency" SG_ 2566902027 Trailer2GeometricData_Index_ISig 1011;
BA_ "Platform_VMCU1_Sig" SG_ 2566902027 Trailer2GeometricData_Index_ISig 1;
BA_ "SystemSignalLongSymbol" SG_ 2566902027 Trailer2GeometricData_Index_ISig "Trailer2GeometricData_Index_ISig_3";
BA_ "GenSigCycleTime" SG_ 2566902027 Trailer1GeometricData_Content_IS 100;
BA_ "GenSigCycleTimeActive" SG_ 2566902027 Trailer1GeometricData_Content_IS 100;
BA_ "GenSigStartValue" SG_ 2566902027 Trailer1GeometricData_Content_IS 255;
BA_ "GenSigMaxLatency" SG_ 2566902027 Trailer1GeometricData_Content_IS 1011;
BA_ "Platform_VMCU1_Sig" SG_ 2566902027 Trailer1GeometricData_Content_IS 1;
BA_ "SystemSignalLongSymbol" SG_ 2566902027 Trailer1GeometricData_Content_IS "Trailer1GeometricData_Content_ISig_3";
BA_ "GenSigCycleTime" SG_ 2566902027 Trailer1GeometricData_Index_ISig 100;
BA_ "GenSigCycleTimeActive" SG_ 2566902027 Trailer1GeometricData_Index_ISig 100;
BA_ "GenSigStartValue" SG_ 2566902027 Trailer1GeometricData_Index_ISig 255;
BA_ "GenSigMaxLatency" SG_ 2566902027 Trailer1GeometricData_Index_ISig 1011;
BA_ "Platform_VMCU1_Sig" SG_ 2566902027 Trailer1GeometricData_Index_ISig 1;
BA_ "SystemSignalLongSymbol" SG_ 2566902027 Trailer1GeometricData_Index_ISig "Trailer1GeometricData_Index_ISig_3";
BA_ "GenSigCycleTime" SG_ 2566902027 Trailer2AxleLoadSum_ISig_3 100;
BA_ "GenSigCycleTimeActive" SG_ 2566902027 Trailer2AxleLoadSum_ISig_3 100;
BA_ "GenSigStartValue" SG_ 2566902027 Trailer2AxleLoadSum_ISig_3 65535;
BA_ "GenSigMaxLatency" SG_ 2566902027 Trailer2AxleLoadSum_ISig_3 1011;
BA_ "Platform_VMCU1_Sig" SG_ 2566902027 Trailer2AxleLoadSum_ISig_3 1;
BA_ "GenSigCycleTime" SG_ 2566902027 Trailer1AxleLoadSum_ISig_3 100;
BA_ "GenSigCycleTimeActive" SG_ 2566902027 Trailer1AxleLoadSum_ISig_3 100;
BA_ "GenSigStartValue" SG_ 2566902027 Trailer1AxleLoadSum_ISig_3 65535;
BA_ "GenSigMaxLatency" SG_ 2566902027 Trailer1AxleLoadSum_ISig_3 1011;
BA_ "Platform_VMCU1_Sig" SG_ 2566902027 Trailer1AxleLoadSum_ISig_3 1;
BA_ "GenSigCycleTime" SG_ 2566902027 Trailer2GeometricData_Content_IS 100;
BA_ "GenSigCycleTimeActive" SG_ 2566902027 Trailer2GeometricData_Content_IS 100;
BA_ "GenSigStartValue" SG_ 2566902027 Trailer2GeometricData_Content_IS 255;
BA_ "GenSigMaxLatency" SG_ 2566902027 Trailer2GeometricData_Content_IS 1011;
BA_ "Platform_VMCU1_Sig" SG_ 2566902027 Trailer2GeometricData_Content_IS 1;
BA_ "SystemSignalLongSymbol" SG_ 2566902027 Trailer2GeometricData_Content_IS "Trailer2GeometricData_Content_ISig_3";
BA_ "GenSigCycleTime" SG_ 2566886667 Trailer5LiftAxle1Pos_ISig_3 100;
BA_ "GenSigCycleTimeActive" SG_ 2566886667 Trailer5LiftAxle1Pos_ISig_3 100;
BA_ "GenSigStartValue" SG_ 2566886667 Trailer5LiftAxle1Pos_ISig_3 3;
BA_ "GenSigMaxLatency" SG_ 2566886667 Trailer5LiftAxle1Pos_ISig_3 111;
BA_ "Platform_VMCU1_Sig" SG_ 2566886667 Trailer5LiftAxle1Pos_ISig_3 1;
BA_ "GenSigCycleTime" SG_ 2566886667 Trailer5LiftAxle2Pos_ISig_3 100;
BA_ "GenSigCycleTimeActive" SG_ 2566886667 Trailer5LiftAxle2Pos_ISig_3 100;
BA_ "GenSigStartValue" SG_ 2566886667 Trailer5LiftAxle2Pos_ISig_3 3;
BA_ "GenSigMaxLatency" SG_ 2566886667 Trailer5LiftAxle2Pos_ISig_3 111;
BA_ "Platform_VMCU1_Sig" SG_ 2566886667 Trailer5LiftAxle2Pos_ISig_3 1;
BA_ "GenSigCycleTime" SG_ 2566886667 Trailer5AxleLoad_AxleLoad_ISig_3 100;
BA_ "GenSigCycleTimeActive" SG_ 2566886667 Trailer5AxleLoad_AxleLoad_ISig_3 100;
BA_ "GenSigStartValue" SG_ 2566886667 Trailer5AxleLoad_AxleLoad_ISig_3 65535;
BA_ "GenSigMaxLatency" SG_ 2566886667 Trailer5AxleLoad_AxleLoad_ISig_3 111;
BA_ "Platform_VMCU1_Sig" SG_ 2566886667 Trailer5AxleLoad_AxleLoad_ISig_3 1;
BA_ "GenSigCycleTime" SG_ 2566886667 Trailer5AxleLoad_AxleId_ISig_3 100;
BA_ "GenSigCycleTimeActive" SG_ 2566886667 Trailer5AxleLoad_AxleId_ISig_3 100;
BA_ "GenSigMaxLatency" SG_ 2566886667 Trailer5AxleLoad_AxleId_ISig_3 111;
BA_ "Platform_VMCU1_Sig" SG_ 2566886667 Trailer5AxleLoad_AxleId_ISig_3 1;
BA_ "GenSigCycleTime" SG_ 2566886155 Trailer3AxleLoad_AxleId_ISig_3 100;
BA_ "GenSigCycleTimeActive" SG_ 2566886155 Trailer3AxleLoad_AxleId_ISig_3 100;
BA_ "GenSigMaxLatency" SG_ 2566886155 Trailer3AxleLoad_AxleId_ISig_3 110;
BA_ "Platform_VMCU1_Sig" SG_ 2566886155 Trailer3AxleLoad_AxleId_ISig_3 1;
BA_ "GenSigCycleTime" SG_ 2566886155 Trailer3LiftAxle1Pos_ISig_3 100;
BA_ "GenSigCycleTimeActive" SG_ 2566886155 Trailer3LiftAxle1Pos_ISig_3 100;
BA_ "GenSigStartValue" SG_ 2566886155 Trailer3LiftAxle1Pos_ISig_3 3;
BA_ "GenSigMaxLatency" SG_ 2566886155 Trailer3LiftAxle1Pos_ISig_3 110;
BA_ "Platform_VMCU1_Sig" SG_ 2566886155 Trailer3LiftAxle1Pos_ISig_3 1;
BA_ "GenSigCycleTime" SG_ 2566886155 Trailer4LiftAxle2Pos_ISig_3 100;
BA_ "GenSigCycleTimeActive" SG_ 2566886155 Trailer4LiftAxle2Pos_ISig_3 100;
BA_ "GenSigStartValue" SG_ 2566886155 Trailer4LiftAxle2Pos_ISig_3 3;
BA_ "GenSigMaxLatency" SG_ 2566886155 Trailer4LiftAxle2Pos_ISig_3 110;
BA_ "Platform_VMCU1_Sig" SG_ 2566886155 Trailer4LiftAxle2Pos_ISig_3 1;
BA_ "GenSigCycleTime" SG_ 2566886155 Trailer4AxleLoad_AxleLoad_ISig_3 100;
BA_ "GenSigCycleTimeActive" SG_ 2566886155 Trailer4AxleLoad_AxleLoad_ISig_3 100;
BA_ "GenSigStartValue" SG_ 2566886155 Trailer4AxleLoad_AxleLoad_ISig_3 65535;
BA_ "GenSigMaxLatency" SG_ 2566886155 Trailer4AxleLoad_AxleLoad_ISig_3 110;
BA_ "Platform_VMCU1_Sig" SG_ 2566886155 Trailer4AxleLoad_AxleLoad_ISig_3 1;
BA_ "GenSigCycleTime" SG_ 2566886155 Trailer3LiftAxle2Pos_ISig_3 100;
BA_ "GenSigCycleTimeActive" SG_ 2566886155 Trailer3LiftAxle2Pos_ISig_3 100;
BA_ "GenSigStartValue" SG_ 2566886155 Trailer3LiftAxle2Pos_ISig_3 3;
BA_ "GenSigMaxLatency" SG_ 2566886155 Trailer3LiftAxle2Pos_ISig_3 110;
BA_ "Platform_VMCU1_Sig" SG_ 2566886155 Trailer3LiftAxle2Pos_ISig_3 1;
BA_ "GenSigCycleTime" SG_ 2566886155 Trailer3AxleLoad_AxleLoad_ISig_3 100;
BA_ "GenSigCycleTimeActive" SG_ 2566886155 Trailer3AxleLoad_AxleLoad_ISig_3 100;
BA_ "GenSigStartValue" SG_ 2566886155 Trailer3AxleLoad_AxleLoad_ISig_3 65535;
BA_ "GenSigMaxLatency" SG_ 2566886155 Trailer3AxleLoad_AxleLoad_ISig_3 110;
BA_ "Platform_VMCU1_Sig" SG_ 2566886155 Trailer3AxleLoad_AxleLoad_ISig_3 1;
BA_ "GenSigCycleTime" SG_ 2566886155 Trailer4LiftAxle1Pos_ISig_3 100;
BA_ "GenSigCycleTimeActive" SG_ 2566886155 Trailer4LiftAxle1Pos_ISig_3 100;
BA_ "GenSigStartValue" SG_ 2566886155 Trailer4LiftAxle1Pos_ISig_3 3;
BA_ "GenSigMaxLatency" SG_ 2566886155 Trailer4LiftAxle1Pos_ISig_3 110;
BA_ "Platform_VMCU1_Sig" SG_ 2566886155 Trailer4LiftAxle1Pos_ISig_3 1;
BA_ "GenSigCycleTime" SG_ 2566886155 Trailer4AxleLoad_AxleId_ISig_3 100;
BA_ "GenSigCycleTimeActive" SG_ 2566886155 Trailer4AxleLoad_AxleId_ISig_3 100;
BA_ "GenSigMaxLatency" SG_ 2566886155 Trailer4AxleLoad_AxleId_ISig_3 110;
BA_ "Platform_VMCU1_Sig" SG_ 2566886155 Trailer4AxleLoad_AxleId_ISig_3 1;
BA_ "GenSigCycleTime" SG_ 2566885643 Trailer2AxleLoad_AxleId_ISig_3 100;
BA_ "GenSigCycleTimeActive" SG_ 2566885643 Trailer2AxleLoad_AxleId_ISig_3 100;
BA_ "GenSigMaxLatency" SG_ 2566885643 Trailer2AxleLoad_AxleId_ISig_3 109;
BA_ "Platform_VMCU1_Sig" SG_ 2566885643 Trailer2AxleLoad_AxleId_ISig_3 1;
BA_ "GenSigCycleTime" SG_ 2566885643 Trailer2LiftAxle2Pos_ISig_3 100;
BA_ "GenSigCycleTimeActive" SG_ 2566885643 Trailer2LiftAxle2Pos_ISig_3 100;
BA_ "GenSigStartValue" SG_ 2566885643 Trailer2LiftAxle2Pos_ISig_3 3;
BA_ "GenSigMaxLatency" SG_ 2566885643 Trailer2LiftAxle2Pos_ISig_3 109;
BA_ "Platform_VMCU1_Sig" SG_ 2566885643 Trailer2LiftAxle2Pos_ISig_3 1;
BA_ "GenSigCycleTime" SG_ 2566885643 Trailer2AxleLoad_AxleLoad_ISig_3 100;
BA_ "GenSigCycleTimeActive" SG_ 2566885643 Trailer2AxleLoad_AxleLoad_ISig_3 100;
BA_ "GenSigStartValue" SG_ 2566885643 Trailer2AxleLoad_AxleLoad_ISig_3 65535;
BA_ "GenSigMaxLatency" SG_ 2566885643 Trailer2AxleLoad_AxleLoad_ISig_3 109;
BA_ "Platform_VMCU1_Sig" SG_ 2566885643 Trailer2AxleLoad_AxleLoad_ISig_3 1;
BA_ "GenSigCycleTime" SG_ 2566885643 TrailerEBSFault 100;
BA_ "GenSigCycleTimeActive" SG_ 2566885643 TrailerEBSFault 100;
BA_ "GenSigStartValue" SG_ 2566885643 TrailerEBSFault 3;
BA_ "GenSigMaxLatency" SG_ 2566885643 TrailerEBSFault 109;
BA_ "Platform_VMCU1_Sig" SG_ 2566885643 TrailerEBSFault 1;
BA_ "GenSigCycleTime" SG_ 2566885643 Trailer1AxleLoad_AxleId_ISig_3 100;
BA_ "GenSigCycleTimeActive" SG_ 2566885643 Trailer1AxleLoad_AxleId_ISig_3 100;
BA_ "GenSigMaxLatency" SG_ 2566885643 Trailer1AxleLoad_AxleId_ISig_3 109;
BA_ "Platform_VMCU1_Sig" SG_ 2566885643 Trailer1AxleLoad_AxleId_ISig_3 1;
BA_ "GenSigCycleTime" SG_ 2566885643 Trailer1LiftAxle1Pos_ISig_3 100;
BA_ "GenSigCycleTimeActive" SG_ 2566885643 Trailer1LiftAxle1Pos_ISig_3 100;
BA_ "GenSigStartValue" SG_ 2566885643 Trailer1LiftAxle1Pos_ISig_3 3;
BA_ "GenSigCycleTime" SG_ 2566885643 Trailer1AxleLoad_AxleLoad_ISig_3 100;
BA_ "GenSigCycleTimeActive" SG_ 2566885643 Trailer1AxleLoad_AxleLoad_ISig_3 100;
BA_ "GenSigStartValue" SG_ 2566885643 Trailer1AxleLoad_AxleLoad_ISig_3 65535;
BA_ "GenSigMaxLatency" SG_ 2566885643 Trailer1AxleLoad_AxleLoad_ISig_3 109;
BA_ "Platform_VMCU1_Sig" SG_ 2566885643 Trailer1AxleLoad_AxleLoad_ISig_3 1;
BA_ "GenSigCycleTime" SG_ 2566885643 TrailersConnected_ISig_3 100;
BA_ "GenSigCycleTimeActive" SG_ 2566885643 TrailersConnected_ISig_3 100;
BA_ "GenSigStartValue" SG_ 2566885643 TrailersConnected_ISig_3 7;
BA_ "GenSigMaxLatency" SG_ 2566885643 TrailersConnected_ISig_3 1010;
BA_ "Platform_VMCU1_Sig" SG_ 2566885643 TrailersConnected_ISig_3 1;
BA_ "GenSigCycleTime" SG_ 2566885643 Trailer1LiftAxle2Pos_ISig_3 100;
BA_ "GenSigCycleTimeActive" SG_ 2566885643 Trailer1LiftAxle2Pos_ISig_3 100;
BA_ "GenSigStartValue" SG_ 2566885643 Trailer1LiftAxle2Pos_ISig_3 3;
BA_ "GenSigMaxLatency" SG_ 2566885643 Trailer1LiftAxle2Pos_ISig_3 109;
BA_ "Platform_VMCU1_Sig" SG_ 2566885643 Trailer1LiftAxle2Pos_ISig_3 1;
BA_ "GenSigCycleTime" SG_ 2566885643 Trailer2LiftAxle1Pos_ISig_3 100;
BA_ "GenSigCycleTimeActive" SG_ 2566885643 Trailer2LiftAxle1Pos_ISig_3 100;
BA_ "GenSigStartValue" SG_ 2566885643 Trailer2LiftAxle1Pos_ISig_3 3;
BA_ "GenSigMaxLatency" SG_ 2566885643 Trailer2LiftAxle1Pos_ISig_3 109;
BA_ "Platform_VMCU1_Sig" SG_ 2566885643 Trailer2LiftAxle1Pos_ISig_3 1;
BA_ "GenSigCycleTime" SG_ 2566885643 TrailerCommunicationType_ISig_3 100;
BA_ "GenSigCycleTimeActive" SG_ 2566885643 TrailerCommunicationType_ISig_3 100;
BA_ "GenSigStartValue" SG_ 2566885643 TrailerCommunicationType_ISig_3 7;
BA_ "GenSigCycleTime" SG_ 2566906635 PredictedMileageOfNextPadChg 100;
BA_ "GenSigCycleTimeActive" SG_ 2566906635 PredictedMileageOfNextPadChg 100;
BA_ "GenSigStartValue" SG_ 2566906635 PredictedMileageOfNextPadChg 4294967295;
BA_ "Platform_VMCU1_Sig" SG_ 2566906635 PredictedMileageOfNextPadChg 1;
BA_ "GenSigCycleTime" SG_ 2566906635 PadChgPredictionLastPadChg 100;
BA_ "GenSigCycleTimeActive" SG_ 2566906635 PadChgPredictionLastPadChg 100;
BA_ "GenSigStartValue" SG_ 2566906635 PadChgPredictionLastPadChg 4294967295;
BA_ "Platform_VMCU1_Sig" SG_ 2566906635 PadChgPredictionLastPadChg 1;
BA_ "GenSigCycleTime" SG_ 2499761675 HSAAvailability 100;
BA_ "GenSigCycleTimeActive" SG_ 2499761675 HSAAvailability 100;
BA_ "GenSigStartValue" SG_ 2499761675 HSAAvailability 3;
BA_ "GenSigMaxLatency" SG_ 2499761675 HSAAvailability 60;
BA_ "Platform_VMCU1_Sig" SG_ 2499761675 HSAAvailability 1;
BA_ "SeToolAncestorID_SIGNAL" SG_ 2499761675 HSAAvailability "x0000001D0410DBE6";
BA_ "SeToolItemID_SIGNAL" SG_ 2499761675 HSAAvailability "x0000001D0410DBE6";
BA_ "SeToolName_SIGNAL" SG_ 2499761675 HSAAvailability "HSAAvailability";
BA_ "SeToolVersion_SIGNAL" SG_ 2499761675 HSAAvailability "1";
BA_ "GenSigCycleTime" SG_ 2499761675 DTCActive 100;
BA_ "GenSigCycleTimeActive" SG_ 2499761675 DTCActive 100;
BA_ "GenSigStartValue" SG_ 2499761675 DTCActive 3;
BA_ "Platform_VMCU1_Sig" SG_ 2499761675 DTCActive 1;
BA_ "GenSigCycleTime" SG_ 2499761675 StretchBrake_Stat_ISig_3 100;
BA_ "GenSigCycleTimeActive" SG_ 2499761675 StretchBrake_Stat_ISig_3 100;
BA_ "GenSigStartValue" SG_ 2499761675 StretchBrake_Stat_ISig_3 7;
BA_ "Platform_VMCU1_Sig" SG_ 2499761675 StretchBrake_Stat_ISig_3 1;
BA_ "GenSigCycleTime" SG_ 2499761675 TrcnCtrlSlipperyRoadWarning_ISig 100;
BA_ "GenSigCycleTimeActive" SG_ 2499761675 TrcnCtrlSlipperyRoadWarning_ISig 100;
BA_ "GenSigStartValue" SG_ 2499761675 TrcnCtrlSlipperyRoadWarning_ISig 3;
BA_ "GenSigMaxLatency" SG_ 2499761675 TrcnCtrlSlipperyRoadWarning_ISig 60;
BA_ "Platform_VMCU1_Sig" SG_ 2499761675 TrcnCtrlSlipperyRoadWarning_ISig 1;
BA_ "SeToolAncestorID_SIGNAL" SG_ 2499761675 TrcnCtrlSlipperyRoadWarning_ISig "x0000001D04125C5E";
BA_ "SeToolItemID_SIGNAL" SG_ 2499761675 TrcnCtrlSlipperyRoadWarning_ISig "x0000001D04125C5E";
BA_ "SeToolName_SIGNAL" SG_ 2499761675 TrcnCtrlSlipperyRoadWarning_ISig "TractionControlSlipperyRoadWarning";
BA_ "SeToolVersion_SIGNAL" SG_ 2499761675 TrcnCtrlSlipperyRoadWarning_ISig "1";
BA_ "SystemSignalLongSymbol" SG_ 2499761675 TrcnCtrlSlipperyRoadWarning_ISig "TrcnCtrlSlipperyRoadWarning_ISig_3";
BA_ "GenSigCycleTime" SG_ 2499761675 RearAxleDiffLockActvnFuncReq_ISi 100;
BA_ "GenSigCycleTimeActive" SG_ 2499761675 RearAxleDiffLockActvnFuncReq_ISi 100;
BA_ "GenSigStartValue" SG_ 2499761675 RearAxleDiffLockActvnFuncReq_ISi 3;
BA_ "GenSigMaxLatency" SG_ 2499761675 RearAxleDiffLockActvnFuncReq_ISi 60;
BA_ "NeedsUpdateBit" SG_ 2499761675 RearAxleDiffLockActvnFuncReq_ISi 1;
BA_ "Platform_VMCU1_Sig" SG_ 2499761675 RearAxleDiffLockActvnFuncReq_ISi 1;
BA_ "SeToolAncestorID_SIGNAL" SG_ 2499761675 RearAxleDiffLockActvnFuncReq_ISi "x0000001D0412880F";
BA_ "SeToolItemID_SIGNAL" SG_ 2499761675 RearAxleDiffLockActvnFuncReq_ISi "x0000001D0412880F";
BA_ "SeToolName_SIGNAL" SG_ 2499761675 RearAxleDiffLockActvnFuncReq_ISi "RearAxleDiffLockActivationFunctionRequest";
BA_ "SeToolVersion_SIGNAL" SG_ 2499761675 RearAxleDiffLockActvnFuncReq_ISi "1";
BA_ "SystemSignalLongSymbol" SG_ 2499761675 RearAxleDiffLockActvnFuncReq_ISi "RearAxleDiffLockActvnFuncReq_ISig_3";
BA_ "GenSigCycleTime" SG_ 2499761675 BrakeTempWarningLevel 100;
BA_ "GenSigCycleTimeActive" SG_ 2499761675 BrakeTempWarningLevel 100;
BA_ "GenSigStartValue" SG_ 2499761675 BrakeTempWarningLevel 255;
BA_ "Platform_VMCU1_Sig" SG_ 2499761675 BrakeTempWarningLevel 1;
BA_ "SeToolAncestorID_SIGNAL" SG_ 2499761675 BrakeTempWarningLevel "x0000001D0417DD85";
BA_ "SeToolItemID_SIGNAL" SG_ 2499761675 BrakeTempWarningLevel "x0000001D0417DD85";
BA_ "SeToolName_SIGNAL" SG_ 2499761675 BrakeTempWarningLevel "BrakeTempartureWarningLevelPercentage";
BA_ "SeToolVersion_SIGNAL" SG_ 2499761675 BrakeTempWarningLevel "1";
BA_ "GenSigCycleTime" SG_ 2499761675 RollerBenchModeStatus 100;
BA_ "GenSigCycleTimeActive" SG_ 2499761675 RollerBenchModeStatus 100;
BA_ "GenSigStartValue" SG_ 2499761675 RollerBenchModeStatus 3;
BA_ "GenSigMaxLatency" SG_ 2499761675 RollerBenchModeStatus 60;
BA_ "Platform_VMCU1_Sig" SG_ 2499761675 RollerBenchModeStatus 1;
BA_ "SeToolAncestorID_SIGNAL" SG_ 2499761675 RollerBenchModeStatus "x0000001D0412BB57";
BA_ "SeToolItemID_SIGNAL" SG_ 2499761675 RollerBenchModeStatus "x0000001D0412BB57";
BA_ "SeToolName_SIGNAL" SG_ 2499761675 RollerBenchModeStatus "RollerBenchModeStatus";
BA_ "SeToolVersion_SIGNAL" SG_ 2499761675 RollerBenchModeStatus "1";
BA_ "GenSigCycleTime" SG_ 2499761675 BrakeAssistStatus 100;
BA_ "GenSigCycleTimeActive" SG_ 2499761675 BrakeAssistStatus 100;
BA_ "GenSigStartValue" SG_ 2499761675 BrakeAssistStatus 3;
BA_ "Platform_VMCU1_Sig" SG_ 2499761675 BrakeAssistStatus 1;
BA_ "GenSigCycleTime" SG_ 2499761675 LongitudinalAcceleration_ISig_3 100;
BA_ "GenSigCycleTimeActive" SG_ 2499761675 LongitudinalAcceleration_ISig_3 100;
BA_ "GenSigStartValue" SG_ 2499761675 LongitudinalAcceleration_ISig_3 65535;
BA_ "Platform_VMCU1_Sig" SG_ 2499761675 LongitudinalAcceleration_ISig_3 1;
BA_ "GenSigCycleTime" SG_ 2499761675 ABSManAutoInhibitionStat_ISig_3 100;
BA_ "GenSigCycleTimeActive" SG_ 2499761675 ABSManAutoInhibitionStat_ISig_3 100;
BA_ "GenSigStartValue" SG_ 2499761675 ABSManAutoInhibitionStat_ISig_3 7;
BA_ "GenSigCycleTime" SG_ 2499761675 TractionFunctionSelected_ISig_3 100;
BA_ "GenSigCycleTimeActive" SG_ 2499761675 TractionFunctionSelected_ISig_3 100;
BA_ "GenSigStartValue" SG_ 2499761675 TractionFunctionSelected_ISig_3 7;
BA_ "Platform_VMCU1_Sig" SG_ 2499761675 TractionFunctionSelected_ISig_3 1;
BA_ "GenSigCycleTime" SG_ 2499761675 PoorBrakePerformanceWarning 100;
BA_ "GenSigCycleTimeActive" SG_ 2499761675 PoorBrakePerformanceWarning 100;
BA_ "GenSigStartValue" SG_ 2499761675 PoorBrakePerformanceWarning 3;
BA_ "GenSigMaxLatency" SG_ 2499761675 PoorBrakePerformanceWarning 60;
BA_ "Platform_VMCU1_Sig" SG_ 2499761675 PoorBrakePerformanceWarning 1;
BA_ "SeToolAncestorID_SIGNAL" SG_ 2499761675 PoorBrakePerformanceWarning "x0000001D04161723";
BA_ "SeToolItemID_SIGNAL" SG_ 2499761675 PoorBrakePerformanceWarning "x0000001D04161723";
BA_ "SeToolName_SIGNAL" SG_ 2499761675 PoorBrakePerformanceWarning "PoorBrakePerformanceWarning";
BA_ "SeToolVersion_SIGNAL" SG_ 2499761675 PoorBrakePerformanceWarning "1";
BA_ "GenSigCycleTime" SG_ 2499761675 VDCActive_ISig_3 100;
BA_ "GenSigCycleTimeActive" SG_ 2499761675 VDCActive_ISig_3 100;
BA_ "GenSigStartValue" SG_ 2499761675 VDCActive_ISig_3 3;
BA_ "Platform_VMCU1_Sig" SG_ 2499761675 VDCActive_ISig_3 1;
BA_ "GenSigCycleTime" SG_ 2499761675 ABSInhibitionStatus_ISig_3 100;
BA_ "GenSigCycleTimeActive" SG_ 2499761675 ABSInhibitionStatus_ISig_3 100;
BA_ "GenSigStartValue" SG_ 2499761675 ABSInhibitionStatus_ISig_3 3;
BA_ "GenSigMaxLatency" SG_ 2499761675 ABSInhibitionStatus_ISig_3 60;
BA_ "Platform_VMCU1_Sig" SG_ 2499761675 ABSInhibitionStatus_ISig_3 1;
BA_ "SeToolAncestorID_SIGNAL" SG_ 2499761675 ABSInhibitionStatus_ISig_3 "x0000001D0412B5DD";
BA_ "SeToolItemID_SIGNAL" SG_ 2499761675 ABSInhibitionStatus_ISig_3 "x0000001D042957DE";
BA_ "SeToolName_SIGNAL" SG_ 2499761675 ABSInhibitionStatus_ISig_3 "ABSInhibitionStatus";
BA_ "SeToolVersion_SIGNAL" SG_ 2499761675 ABSInhibitionStatus_ISig_3 "2";
BA_ "GenSigCycleTime" SG_ 2499761675 RearAxleSteeringFunctionStatus 100;
BA_ "GenSigCycleTimeActive" SG_ 2499761675 RearAxleSteeringFunctionStatus 100;
BA_ "GenSigStartValue" SG_ 2499761675 RearAxleSteeringFunctionStatus 7;
BA_ "Platform_VMCU1_Sig" SG_ 2499761675 RearAxleSteeringFunctionStatus 1;
BA_ "GenSigCycleTime" SG_ 2499761675 AutoRearAxleDiffLockFnc_stat 100;
BA_ "GenSigCycleTimeActive" SG_ 2499761675 AutoRearAxleDiffLockFnc_stat 100;
BA_ "GenSigStartValue" SG_ 2499761675 AutoRearAxleDiffLockFnc_stat 3;
BA_ "Platform_VMCU1_Sig" SG_ 2499761675 AutoRearAxleDiffLockFnc_stat 1;
BA_ "GenSigSendType" SG_ 2499761675 RearAxleDiffLockActvnFuncReq_UB_ 7;
BA_ "Platform_VMCU1_Sig" SG_ 2499761675 RearAxleDiffLockActvnFuncReq_UB_ 1;
BA_ "SystemSignalLongSymbol" SG_ 2499761675 RearAxleDiffLockActvnFuncReq_UB_ "RearAxleDiffLockActvnFuncReq_UB_ISig_3";
BA_ "GenSigCycleTime" SG_ 2499750411 TrailerCorrectionPressure 100;
BA_ "GenSigCycleTimeActive" SG_ 2499750411 TrailerCorrectionPressure 100;
BA_ "GenSigStartValue" SG_ 2499750411 TrailerCorrectionPressure 255;
BA_ "Platform_VMCU1_Sig" SG_ 2499750411 TrailerCorrectionPressure 1;
BA_ "GenSigCycleTime" SG_ 2499750411 ESCState_ISig_3 100;
BA_ "GenSigCycleTimeActive" SG_ 2499750411 ESCState_ISig_3 100;
BA_ "GenSigStartValue" SG_ 2499750411 ESCState_ISig_3 7;
BA_ "Platform_VMCU1_Sig" SG_ 2499750411 ESCState_ISig_3 1;
BA_ "GenSigCycleTime" SG_ 2499750411 HillHolderMode_ISig_3 100;
BA_ "GenSigCycleTimeActive" SG_ 2499750411 HillHolderMode_ISig_3 100;
BA_ "GenSigStartValue" SG_ 2499750411 HillHolderMode_ISig_3 7;
BA_ "Platform_VMCU1_Sig" SG_ 2499750411 HillHolderMode_ISig_3 1;
BA_ "GenSigCycleTime" SG_ 2499750411 HSAState_ISig_3 100;
BA_ "GenSigCycleTimeActive" SG_ 2499750411 HSAState_ISig_3 100;
BA_ "GenSigStartValue" SG_ 2499750411 HSAState_ISig_3 3;
BA_ "Platform_VMCU1_Sig" SG_ 2499750411 HSAState_ISig_3 1;
BA_ "GenSigCycleTime" SG_ 2499750411 SasAdaptationInProgress 100;
BA_ "GenSigCycleTimeActive" SG_ 2499750411 SasAdaptationInProgress 100;
BA_ "GenSigStartValue" SG_ 2499750411 SasAdaptationInProgress 3;
BA_ "Platform_VMCU1_Sig" SG_ 2499750411 SasAdaptationInProgress 1;
BA_ "GenSigCycleTime" SG_ 2499750411 ESCStatus 100;
BA_ "GenSigCycleTimeActive" SG_ 2499750411 ESCStatus 100;
BA_ "GenSigStartValue" SG_ 2499750411 ESCStatus 7;
BA_ "Platform_VMCU1_Sig" SG_ 2499750411 ESCStatus 1;
BA_ "GenSigCycleTime" SG_ 2499750411 BrakePedalTestState 100;
BA_ "GenSigCycleTimeActive" SG_ 2499750411 BrakePedalTestState 100;
BA_ "GenSigStartValue" SG_ 2499750411 BrakePedalTestState 15;
BA_ "Platform_VMCU1_Sig" SG_ 2499750411 BrakePedalTestState 1;
BA_ "GenSigCycleTime" SG_ 2499750411 ABSOffRoadStatus 100;
BA_ "GenSigCycleTimeActive" SG_ 2499750411 ABSOffRoadStatus 100;
BA_ "GenSigStartValue" SG_ 2499750411 ABSOffRoadStatus 3;
BA_ "GenSigCycleTime" SG_ 2499750411 HillStartAidStatus 100;
BA_ "GenSigCycleTimeActive" SG_ 2499750411 HillStartAidStatus 100;
BA_ "GenSigStartValue" SG_ 2499750411 HillStartAidStatus 7;
BA_ "Platform_VMCU1_Sig" SG_ 2499750411 HillStartAidStatus 1;
BA_ "GenSigCycleTime" SG_ 2499750411 RoadSpeedInformation 100;
BA_ "GenSigCycleTimeActive" SG_ 2499750411 RoadSpeedInformation 100;
BA_ "GenSigStartValue" SG_ 2499750411 RoadSpeedInformation 255;
BA_ "GenSigMaxLatency" SG_ 2499750411 RoadSpeedInformation 59;
BA_ "Platform_VMCU1_Sig" SG_ 2499750411 RoadSpeedInformation 1;
BA_ "SeToolAncestorID_SIGNAL" SG_ 2499750411 RoadSpeedInformation "x0000001D0416ED0C";
BA_ "SeToolItemID_SIGNAL" SG_ 2499750411 RoadSpeedInformation "x0000001D0416ED0C";
BA_ "SeToolName_SIGNAL" SG_ 2499750411 RoadSpeedInformation "RoadSpeedInformation";
BA_ "SeToolVersion_SIGNAL" SG_ 2499750411 RoadSpeedInformation "1";
BA_ "GenSigCycleTime" SG_ 2499750411 XBRSystemInformation 100;
BA_ "GenSigCycleTimeActive" SG_ 2499750411 XBRSystemInformation 100;
BA_ "GenSigStartValue" SG_ 2499750411 XBRSystemInformation 7;
BA_ "Platform_VMCU1_Sig" SG_ 2499750411 XBRSystemInformation 1;
BA_ "GenSigCycleTime" SG_ 2566767627 XBRActiveControlMode_ISig_3 100;
BA_ "GenSigCycleTimeActive" SG_ 2566767627 XBRActiveControlMode_ISig_3 100;
BA_ "GenSigStartValue" SG_ 2566767627 XBRActiveControlMode_ISig_3 15;
BA_ "Platform_VMCU1_Sig" SG_ 2566767627 XBRActiveControlMode_ISig_3 1;
BA_ "SPN" SG_ 2566767627 XBRActiveControlMode_ISig_3 2918;
BA_ "SeToolAncestorID_SIGNAL" SG_ 2566767627 XBRActiveControlMode_ISig_3 "x0000001D0415286A";
BA_ "SeToolItemID_SIGNAL" SG_ 2566767627 XBRActiveControlMode_ISig_3 "x0000001D0415286A";
BA_ "SeToolName_SIGNAL" SG_ 2566767627 XBRActiveControlMode_ISig_3 "XBRActiveControlMode";
BA_ "SeToolVersion_SIGNAL" SG_ 2566767627 XBRActiveControlMode_ISig_3 "1";
BA_ "GenSigCycleTime" SG_ 2566767627 EPBHillHolderMode_ISig_3 100;
BA_ "GenSigCycleTimeActive" SG_ 2566767627 EPBHillHolderMode_ISig_3 100;
BA_ "GenSigStartValue" SG_ 2566767627 EPBHillHolderMode_ISig_3 7;
BA_ "Platform_VMCU1_Sig" SG_ 2566767627 EPBHillHolderMode_ISig_3 1;
BA_ "SPN" SG_ 2566767627 EPBHillHolderMode_ISig_3 2912;
BA_ "SeToolAncestorID_SIGNAL" SG_ 2566767627 EPBHillHolderMode_ISig_3 "x0000001D0410DBE4";
BA_ "SeToolItemID_SIGNAL" SG_ 2566767627 EPBHillHolderMode_ISig_3 "x0000001D04295780";
BA_ "SeToolName_SIGNAL" SG_ 2566767627 EPBHillHolderMode_ISig_3 "HillHolderMode";
BA_ "SeToolVersion_SIGNAL" SG_ 2566767627 EPBHillHolderMode_ISig_3 "2";
BA_ "GenSigCycleTime" SG_ 2566767627 FoundationBrakeUse_ISig_3 100;
BA_ "GenSigCycleTimeActive" SG_ 2566767627 FoundationBrakeUse_ISig_3 100;
BA_ "GenSigStartValue" SG_ 2566767627 FoundationBrakeUse_ISig_3 3;
BA_ "Platform_VMCU1_Sig" SG_ 2566767627 FoundationBrakeUse_ISig_3 1;
BA_ "SPN" SG_ 2566767627 FoundationBrakeUse_ISig_3 2919;
BA_ "SeToolAncestorID_SIGNAL" SG_ 2566767627 FoundationBrakeUse_ISig_3 "x0000001D04149A2F";
BA_ "SeToolItemID_SIGNAL" SG_ 2566767627 FoundationBrakeUse_ISig_3 "x0000001D043574DF";
BA_ "SeToolName_SIGNAL" SG_ 2566767627 FoundationBrakeUse_ISig_3 "FoundationBrakeUse";
BA_ "SeToolVersion_SIGNAL" SG_ 2566767627 FoundationBrakeUse_ISig_3 "2";
BA_ "GenSigCycleTime" SG_ 2566767627 XBRSystemState 100;
BA_ "GenSigCycleTimeActive" SG_ 2566767627 XBRSystemState 100;
BA_ "GenSigStartValue" SG_ 2566767627 XBRSystemState 3;
BA_ "Platform_VMCU1_Sig" SG_ 2566767627 XBRSystemState 1;
BA_ "SPN" SG_ 2566767627 XBRSystemState 2917;
BA_ "SeToolAncestorID_SIGNAL" SG_ 2566767627 XBRSystemState "x0000001D04151C3B";
BA_ "SeToolItemID_SIGNAL" SG_ 2566767627 XBRSystemState "x0000001D04151C3B";
BA_ "SeToolName_SIGNAL" SG_ 2566767627 XBRSystemState "XBRSystemState";
BA_ "SeToolVersion_SIGNAL" SG_ 2566767627 XBRSystemState "1";
BA_ "GenSigCycleTime" SG_ 2566767627 BrakeTemperatureWarning 100;
BA_ "GenSigCycleTimeActive" SG_ 2566767627 BrakeTemperatureWarning 100;
BA_ "GenSigStartValue" SG_ 2566767627 BrakeTemperatureWarning 3;
BA_ "Platform_VMCU1_Sig" SG_ 2566767627 BrakeTemperatureWarning 1;
BA_ "SPN" SG_ 2566767627 BrakeTemperatureWarning 3839;
BA_ "GenSigCycleTime" SG_ 2566831883 RrAxle1LeftWheelRelativeSpeed_IS 100;
BA_ "GenSigCycleTimeActive" SG_ 2566831883 RrAxle1LeftWheelRelativeSpeed_IS 100;
BA_ "GenSigStartValue" SG_ 2566831883 RrAxle1LeftWheelRelativeSpeed_IS 255;
BA_ "Platform_VMCU1_Sig" SG_ 2566831883 RrAxle1LeftWheelRelativeSpeed_IS 1;
BA_ "SPN" SG_ 2566831883 RrAxle1LeftWheelRelativeSpeed_IS 907;
BA_ "SeToolAncestorID_SIGNAL" SG_ 2566831883 RrAxle1LeftWheelRelativeSpeed_IS "x0000001D041519CB";
BA_ "SeToolItemID_SIGNAL" SG_ 2566831883 RrAxle1LeftWheelRelativeSpeed_IS "x0000001D041519CB";
BA_ "SeToolName_SIGNAL" SG_ 2566831883 RrAxle1LeftWheelRelativeSpeed_IS "RelativeSpeedRearAxle#1LeftWheel";
BA_ "SeToolVersion_SIGNAL" SG_ 2566831883 RrAxle1LeftWheelRelativeSpeed_IS "1";
BA_ "SystemSignalLongSymbol" SG_ 2566831883 RrAxle1LeftWheelRelativeSpeed_IS "RrAxle1LeftWheelRelativeSpeed_ISig_3";
BA_ "GenSigCycleTime" SG_ 2566831883 RrAxle1RightWheelRelativeSpeed_I 100;
BA_ "GenSigCycleTimeActive" SG_ 2566831883 RrAxle1RightWheelRelativeSpeed_I 100;
BA_ "GenSigStartValue" SG_ 2566831883 RrAxle1RightWheelRelativeSpeed_I 255;
BA_ "Platform_VMCU1_Sig" SG_ 2566831883 RrAxle1RightWheelRelativeSpeed_I 1;
BA_ "SPN" SG_ 2566831883 RrAxle1RightWheelRelativeSpeed_I 908;
BA_ "SeToolAncestorID_SIGNAL" SG_ 2566831883 RrAxle1RightWheelRelativeSpeed_I "x0000001D041519CD";
BA_ "SeToolItemID_SIGNAL" SG_ 2566831883 RrAxle1RightWheelRelativeSpeed_I "x0000001D041519CD";
BA_ "SeToolName_SIGNAL" SG_ 2566831883 RrAxle1RightWheelRelativeSpeed_I "RelativeSpeedRearAxle#1RightWheel";
BA_ "SeToolVersion_SIGNAL" SG_ 2566831883 RrAxle1RightWheelRelativeSpeed_I "1";
BA_ "SystemSignalLongSymbol" SG_ 2566831883 RrAxle1RightWheelRelativeSpeed_I "RrAxle1RightWheelRelativeSpeed_ISig_3";
BA_ "GenSigCycleTime" SG_ 2566831883 FrAxleRightWheelRelativeSpeed_IS 100;
BA_ "GenSigCycleTimeActive" SG_ 2566831883 FrAxleRightWheelRelativeSpeed_IS 100;
BA_ "GenSigStartValue" SG_ 2566831883 FrAxleRightWheelRelativeSpeed_IS 255;
BA_ "Platform_VMCU1_Sig" SG_ 2566831883 FrAxleRightWheelRelativeSpeed_IS 1;
BA_ "SPN" SG_ 2566831883 FrAxleRightWheelRelativeSpeed_IS 906;
BA_ "SeToolAncestorID_SIGNAL" SG_ 2566831883 FrAxleRightWheelRelativeSpeed_IS "x0000001D041519BA";
BA_ "SeToolItemID_SIGNAL" SG_ 2566831883 FrAxleRightWheelRelativeSpeed_IS "x0000001D041519BA";
BA_ "SeToolName_SIGNAL" SG_ 2566831883 FrAxleRightWheelRelativeSpeed_IS "RelativeSpeedFrontAxleRightWheel";
BA_ "SeToolVersion_SIGNAL" SG_ 2566831883 FrAxleRightWheelRelativeSpeed_IS "1";
BA_ "SystemSignalLongSymbol" SG_ 2566831883 FrAxleRightWheelRelativeSpeed_IS "FrAxleRightWheelRelativeSpeed_ISig_3";
BA_ "GenSigCycleTime" SG_ 2566831883 RrAxle2RightWheelRelativeSpeed_I 100;
BA_ "GenSigCycleTimeActive" SG_ 2566831883 RrAxle2RightWheelRelativeSpeed_I 100;
BA_ "GenSigStartValue" SG_ 2566831883 RrAxle2RightWheelRelativeSpeed_I 255;
BA_ "Platform_VMCU1_Sig" SG_ 2566831883 RrAxle2RightWheelRelativeSpeed_I 1;
BA_ "SPN" SG_ 2566831883 RrAxle2RightWheelRelativeSpeed_I 910;
BA_ "SeToolAncestorID_SIGNAL" SG_ 2566831883 RrAxle2RightWheelRelativeSpeed_I "x0000001D041519D3";
BA_ "SeToolItemID_SIGNAL" SG_ 2566831883 RrAxle2RightWheelRelativeSpeed_I "x0000001D041519D3";
BA_ "SeToolName_SIGNAL" SG_ 2566831883 RrAxle2RightWheelRelativeSpeed_I "RelativeSpeedRearAxle#2RightWheel";
BA_ "SeToolVersion_SIGNAL" SG_ 2566831883 RrAxle2RightWheelRelativeSpeed_I "1";
BA_ "SystemSignalLongSymbol" SG_ 2566831883 RrAxle2RightWheelRelativeSpeed_I "RrAxle2RightWheelRelativeSpeed_ISig_3";
BA_ "GenSigCycleTime" SG_ 2566831883 RrAxle2LeftWheelRelativeSpeed_IS 100;
BA_ "GenSigCycleTimeActive" SG_ 2566831883 RrAxle2LeftWheelRelativeSpeed_IS 100;
BA_ "GenSigStartValue" SG_ 2566831883 RrAxle2LeftWheelRelativeSpeed_IS 255;
BA_ "Platform_VMCU1_Sig" SG_ 2566831883 RrAxle2LeftWheelRelativeSpeed_IS 1;
BA_ "SPN" SG_ 2566831883 RrAxle2LeftWheelRelativeSpeed_IS 909;
BA_ "SeToolAncestorID_SIGNAL" SG_ 2566831883 RrAxle2LeftWheelRelativeSpeed_IS "x0000001D041519D1";
BA_ "SeToolItemID_SIGNAL" SG_ 2566831883 RrAxle2LeftWheelRelativeSpeed_IS "x0000001D041519D1";
BA_ "SeToolName_SIGNAL" SG_ 2566831883 RrAxle2LeftWheelRelativeSpeed_IS "RelativeSpeedRearAxle#2LeftWheel";
BA_ "SeToolVersion_SIGNAL" SG_ 2566831883 RrAxle2LeftWheelRelativeSpeed_IS "1";
BA_ "SystemSignalLongSymbol" SG_ 2566831883 RrAxle2LeftWheelRelativeSpeed_IS "RrAxle2LeftWheelRelativeSpeed_ISig_3";
BA_ "GenSigCycleTime" SG_ 2566831883 FrontAxleSpeed_ISig_3 100;
BA_ "GenSigCycleTimeActive" SG_ 2566831883 FrontAxleSpeed_ISig_3 100;
BA_ "GenSigStartValue" SG_ 2566831883 FrontAxleSpeed_ISig_3 65535;
BA_ "Platform_VMCU1_Sig" SG_ 2566831883 FrontAxleSpeed_ISig_3 1;
BA_ "SPN" SG_ 2566831883 FrontAxleSpeed_ISig_3 904;
BA_ "SeToolAncestorID_SIGNAL" SG_ 2566831883 FrontAxleSpeed_ISig_3 "x0000001D041519B4";
BA_ "SeToolItemID_SIGNAL" SG_ 2566831883 FrontAxleSpeed_ISig_3 "x0000001D041519B4";
BA_ "SeToolName_SIGNAL" SG_ 2566831883 FrontAxleSpeed_ISig_3 "FrontAxleSpeed";
BA_ "SeToolVersion_SIGNAL" SG_ 2566831883 FrontAxleSpeed_ISig_3 "1";
BA_ "GenSigCycleTime" SG_ 2566831883 FrAxleLeftWheelRelativeSpeed_ISi 100;
BA_ "GenSigCycleTimeActive" SG_ 2566831883 FrAxleLeftWheelRelativeSpeed_ISi 100;
BA_ "GenSigStartValue" SG_ 2566831883 FrAxleLeftWheelRelativeSpeed_ISi 255;
BA_ "Platform_VMCU1_Sig" SG_ 2566831883 FrAxleLeftWheelRelativeSpeed_ISi 1;
BA_ "SPN" SG_ 2566831883 FrAxleLeftWheelRelativeSpeed_ISi 905;
BA_ "SeToolAncestorID_SIGNAL" SG_ 2566831883 FrAxleLeftWheelRelativeSpeed_ISi "x0000001D041519B8";
BA_ "SeToolItemID_SIGNAL" SG_ 2566831883 FrAxleLeftWheelRelativeSpeed_ISi "x0000001D041519B8";
BA_ "SeToolName_SIGNAL" SG_ 2566831883 FrAxleLeftWheelRelativeSpeed_ISi "RelativeSpeedFrontAxleLeftWheel";
BA_ "SeToolVersion_SIGNAL" SG_ 2566831883 FrAxleLeftWheelRelativeSpeed_ISi "1";
BA_ "SystemSignalLongSymbol" SG_ 2566831883 FrAxleLeftWheelRelativeSpeed_ISi "FrAxleLeftWheelRelativeSpeed_ISig_3";
BA_REL_ "GenSigFirstTimeoutTime" BU_SG_REL_ VMCU SG_ 2566898187 Trailer2CalibInfo_LoadRange_ISig 24000;
BA_REL_ "GenSigTimeoutTime" BU_SG_REL_ VMCU SG_ 2566898187 Trailer2CalibInfo_LoadRange_ISig 6000;
BA_REL_ "GenSigFirstTimeoutTime" BU_SG_REL_ IC3 SG_ 2566898187 Trailer2CalibInfo_LoadRange_ISig 24000;
BA_REL_ "GenSigTimeoutTime" BU_SG_REL_ IC3 SG_ 2566898187 Trailer2CalibInfo_LoadRange_ISig 6000;
BA_REL_ "GenSigFirstTimeoutTime" BU_SG_REL_ VMCU SG_ 2566898187 Trailer2CalibInfo_CalibUsage_ISi 24000;
BA_REL_ "GenSigTimeoutTime" BU_SG_REL_ VMCU SG_ 2566898187 Trailer2CalibInfo_CalibUsage_ISi 6000;
BA_REL_ "GenSigFirstTimeoutTime" BU_SG_REL_ IC3 SG_ 2566898187 Trailer2CalibInfo_CalibUsage_ISi 24000;
BA_REL_ "GenSigTimeoutTime" BU_SG_REL_ IC3 SG_ 2566898187 Trailer2CalibInfo_CalibUsage_ISi 6000;
BA_REL_ "GenSigFirstTimeoutTime" BU_SG_REL_ IC3 SG_ 2566898187 Trailer2CalibInfo_UncalibLoad_IS 24000;
BA_REL_ "GenSigTimeoutTime" BU_SG_REL_ IC3 SG_ 2566898187 Trailer2CalibInfo_UncalibLoad_IS 6000;
BA_REL_ "GenSigFirstTimeoutTime" BU_SG_REL_ VMCU SG_ 2566898187 Trailer2CalibInfo_UncalibLoad_IS 24000;
BA_REL_ "GenSigTimeoutTime" BU_SG_REL_ VMCU SG_ 2566898187 Trailer2CalibInfo_UncalibLoad_IS 6000;
BA_REL_ "GenSigFirstTimeoutTime" BU_SG_REL_ IC3 SG_ 2566898187 Trailer2CalibInfo_ScaleLoad_ISig 24000;
BA_REL_ "GenSigTimeoutTime" BU_SG_REL_ IC3 SG_ 2566898187 Trailer2CalibInfo_ScaleLoad_ISig 6000;
BA_REL_ "GenSigFirstTimeoutTime" BU_SG_REL_ VMCU SG_ 2566898187 Trailer2CalibInfo_ScaleLoad_ISig 24000;
BA_REL_ "GenSigTimeoutTime" BU_SG_REL_ VMCU SG_ 2566898187 Trailer2CalibInfo_ScaleLoad_ISig 6000;
BA_REL_ "GenSigFirstTimeoutTime" BU_SG_REL_ IC3 SG_ 2566898187 Trailer2CalibInfo_DataStorage_IS 24000;
BA_REL_ "GenSigTimeoutTime" BU_SG_REL_ IC3 SG_ 2566898187 Trailer2CalibInfo_DataStorage_IS 6000;
BA_REL_ "GenSigFirstTimeoutTime" BU_SG_REL_ VMCU SG_ 2566898187 Trailer2CalibInfo_DataStorage_IS 24000;
BA_REL_ "GenSigTimeoutTime" BU_SG_REL_ VMCU SG_ 2566898187 Trailer2CalibInfo_DataStorage_IS 6000;
BA_REL_ "GenSigFirstTimeoutTime" BU_SG_REL_ VMCU SG_ 2566898187 Trailer2CalibInfo_AxleId_ISig_3 24000;
BA_REL_ "GenSigTimeoutTime" BU_SG_REL_ VMCU SG_ 2566898187 Trailer2CalibInfo_AxleId_ISig_3 6000;
BA_REL_ "GenSigFirstTimeoutTime" BU_SG_REL_ IC3 SG_ 2566898187 Trailer2CalibInfo_AxleId_ISig_3 24000;
BA_REL_ "GenSigTimeoutTime" BU_SG_REL_ IC3 SG_ 2566898187 Trailer2CalibInfo_AxleId_ISig_3 6000;
BA_REL_ "GenSigFirstTimeoutTime" BU_SG_REL_ VMCU SG_ 2566898187 Trailer2CalibInfo_Year_ISig_3 24000;
BA_REL_ "GenSigTimeoutTime" BU_SG_REL_ VMCU SG_ 2566898187 Trailer2CalibInfo_Year_ISig_3 6000;
BA_REL_ "GenSigFirstTimeoutTime" BU_SG_REL_ IC3 SG_ 2566898187 Trailer2CalibInfo_Year_ISig_3 24000;
BA_REL_ "GenSigTimeoutTime" BU_SG_REL_ IC3 SG_ 2566898187 Trailer2CalibInfo_Year_ISig_3 6000;
BA_REL_ "GenSigFirstTimeoutTime" BU_SG_REL_ IC3 SG_ 2566898187 Trailer2CalibInfo_Month_ISig_3 24000;
BA_REL_ "GenSigTimeoutTime" BU_SG_REL_ IC3 SG_ 2566898187 Trailer2CalibInfo_Month_ISig_3 6000;
BA_REL_ "GenSigFirstTimeoutTime" BU_SG_REL_ VMCU SG_ 2566898187 Trailer2CalibInfo_Month_ISig_3 24000;
BA_REL_ "GenSigTimeoutTime" BU_SG_REL_ VMCU SG_ 2566898187 Trailer2CalibInfo_Month_ISig_3 6000;
BA_REL_ "GenSigFirstTimeoutTime" BU_SG_REL_ IC3 SG_ 2566897931 Trailer1CalibInfo_CalibUsage_ISi 24000;
BA_REL_ "GenSigTimeoutTime" BU_SG_REL_ IC3 SG_ 2566897931 Trailer1CalibInfo_CalibUsage_ISi 6000;
BA_REL_ "GenSigFirstTimeoutTime" BU_SG_REL_ VMCU SG_ 2566897931 Trailer1CalibInfo_CalibUsage_ISi 24000;
BA_REL_ "GenSigTimeoutTime" BU_SG_REL_ VMCU SG_ 2566897931 Trailer1CalibInfo_CalibUsage_ISi 6000;
BA_REL_ "GenSigFirstTimeoutTime" BU_SG_REL_ IC3 SG_ 2566897931 Trailer1CalibInfo_ScaleLoad_ISig 24000;
BA_REL_ "GenSigTimeoutTime" BU_SG_REL_ IC3 SG_ 2566897931 Trailer1CalibInfo_ScaleLoad_ISig 6000;
BA_REL_ "GenSigFirstTimeoutTime" BU_SG_REL_ VMCU SG_ 2566897931 Trailer1CalibInfo_ScaleLoad_ISig 24000;
BA_REL_ "GenSigTimeoutTime" BU_SG_REL_ VMCU SG_ 2566897931 Trailer1CalibInfo_ScaleLoad_ISig 6000;
BA_REL_ "GenSigFirstTimeoutTime" BU_SG_REL_ IC3 SG_ 2566897931 Trailer1CalibInfo_DataStorage_IS 24000;
BA_REL_ "GenSigTimeoutTime" BU_SG_REL_ IC3 SG_ 2566897931 Trailer1CalibInfo_DataStorage_IS 6000;
BA_REL_ "GenSigFirstTimeoutTime" BU_SG_REL_ VMCU SG_ 2566897931 Trailer1CalibInfo_DataStorage_IS 24000;
BA_REL_ "GenSigTimeoutTime" BU_SG_REL_ VMCU SG_ 2566897931 Trailer1CalibInfo_DataStorage_IS 6000;
BA_REL_ "GenSigFirstTimeoutTime" BU_SG_REL_ IC3 SG_ 2566897931 Trailer1CalibInfo_Month_ISig_3 24000;
BA_REL_ "GenSigTimeoutTime" BU_SG_REL_ IC3 SG_ 2566897931 Trailer1CalibInfo_Month_ISig_3 6000;
BA_REL_ "GenSigFirstTimeoutTime" BU_SG_REL_ VMCU SG_ 2566897931 Trailer1CalibInfo_Month_ISig_3 24000;
BA_REL_ "GenSigTimeoutTime" BU_SG_REL_ VMCU SG_ 2566897931 Trailer1CalibInfo_Month_ISig_3 6000;
BA_REL_ "GenSigFirstTimeoutTime" BU_SG_REL_ VMCU SG_ 2566897931 Trailer1CalibInfo_LoadRange_ISig 24000;
BA_REL_ "GenSigTimeoutTime" BU_SG_REL_ VMCU SG_ 2566897931 Trailer1CalibInfo_LoadRange_ISig 6000;
BA_REL_ "GenSigFirstTimeoutTime" BU_SG_REL_ IC3 SG_ 2566897931 Trailer1CalibInfo_LoadRange_ISig 24000;
BA_REL_ "GenSigTimeoutTime" BU_SG_REL_ IC3 SG_ 2566897931 Trailer1CalibInfo_LoadRange_ISig 6000;
BA_REL_ "GenSigFirstTimeoutTime" BU_SG_REL_ IC3 SG_ 2566897931 Trailer1CalibInfo_AxleId_ISig_3 24000;
BA_REL_ "GenSigTimeoutTime" BU_SG_REL_ IC3 SG_ 2566897931 Trailer1CalibInfo_AxleId_ISig_3 6000;
BA_REL_ "GenSigFirstTimeoutTime" BU_SG_REL_ VMCU SG_ 2566897931 Trailer1CalibInfo_AxleId_ISig_3 24000;
BA_REL_ "GenSigTimeoutTime" BU_SG_REL_ VMCU SG_ 2566897931 Trailer1CalibInfo_AxleId_ISig_3 6000;
BA_REL_ "GenSigFirstTimeoutTime" BU_SG_REL_ VMCU SG_ 2566897931 Trailer1CalibInfo_UncalibLoad_IS 24000;
BA_REL_ "GenSigTimeoutTime" BU_SG_REL_ VMCU SG_ 2566897931 Trailer1CalibInfo_UncalibLoad_IS 6000;
BA_REL_ "GenSigFirstTimeoutTime" BU_SG_REL_ IC3 SG_ 2566897931 Trailer1CalibInfo_UncalibLoad_IS 24000;
BA_REL_ "GenSigTimeoutTime" BU_SG_REL_ IC3 SG_ 2566897931 Trailer1CalibInfo_UncalibLoad_IS 6000;
BA_REL_ "GenSigFirstTimeoutTime" BU_SG_REL_ IC3 SG_ 2566897931 Trailer1CalibInfo_Year_ISig_3 24000;
BA_REL_ "GenSigTimeoutTime" BU_SG_REL_ IC3 SG_ 2566897931 Trailer1CalibInfo_Year_ISig_3 6000;
BA_REL_ "GenSigFirstTimeoutTime" BU_SG_REL_ VMCU SG_ 2566897931 Trailer1CalibInfo_Year_ISig_3 24000;
BA_REL_ "GenSigTimeoutTime" BU_SG_REL_ VMCU SG_ 2566897931 Trailer1CalibInfo_Year_ISig_3 6000;
BA_REL_ "GenSigFirstTimeoutTime" BU_SG_REL_ IC3 SG_ 2566878475 Trailer5BrkLining_Wear_ISig_3 3000;
BA_REL_ "GenSigTimeoutTime" BU_SG_REL_ IC3 SG_ 2566878475 Trailer5BrkLining_Wear_ISig_3 600;
BA_REL_ "GenSigFirstTimeoutTime" BU_SG_REL_ IC3 SG_ 2566878475 Trailer5RampLevel_LvlPos_ISig_3 3000;
BA_REL_ "GenSigTimeoutTime" BU_SG_REL_ IC3 SG_ 2566878475 Trailer5RampLevel_LvlPos_ISig_3 600;
BA_REL_ "GenSigFirstTimeoutTime" BU_SG_REL_ IC3 SG_ 2566878475 Trailer5RampLevel_LvlStatus_ISig 3000;
BA_REL_ "GenSigTimeoutTime" BU_SG_REL_ IC3 SG_ 2566878475 Trailer5RampLevel_LvlStatus_ISig 600;
BA_REL_ "GenSigFirstTimeoutTime" BU_SG_REL_ VMCU SG_ 2566878475 Trailer5RelBodyLevel_FrontLevel 3000;
BA_REL_ "GenSigTimeoutTime" BU_SG_REL_ VMCU SG_ 2566878475 Trailer5RelBodyLevel_FrontLevel 600;
BA_REL_ "GenSigFirstTimeoutTime" BU_SG_REL_ IC3 SG_ 2566878475 Trailer5NormalLevel_LvlPos_ISig_ 3000;
BA_REL_ "GenSigTimeoutTime" BU_SG_REL_ IC3 SG_ 2566878475 Trailer5NormalLevel_LvlPos_ISig_ 600;
BA_REL_ "GenSigFirstTimeoutTime" BU_SG_REL_ IC3 SG_ 2566878475 Trailer5BrkLining_BrkLnTireId_IS 3000;
BA_REL_ "GenSigTimeoutTime" BU_SG_REL_ IC3 SG_ 2566878475 Trailer5BrkLining_BrkLnTireId_IS 600;
BA_REL_ "GenSigFirstTimeoutTime" BU_SG_REL_ VMCU SG_ 2566878475 Trailer5RelBodyLevel_RearLevel 3000;
BA_REL_ "GenSigTimeoutTime" BU_SG_REL_ VMCU SG_ 2566878475 Trailer5RelBodyLevel_RearLevel 600;
BA_REL_ "GenSigFirstTimeoutTime" BU_SG_REL_ IC3 SG_ 2566878475 Trailer5BrkLining_Warning_ISig_3 3000;
BA_REL_ "GenSigTimeoutTime" BU_SG_REL_ IC3 SG_ 2566878475 Trailer5BrkLining_Warning_ISig_3 600;
BA_REL_ "GenSigFirstTimeoutTime" BU_SG_REL_ IC3 SG_ 2566878475 Trailer5NormalLevel_LvlStatus_IS 3000;
BA_REL_ "GenSigTimeoutTime" BU_SG_REL_ IC3 SG_ 2566878475 Trailer5NormalLevel_LvlStatus_IS 600;
BA_REL_ "GenSigFirstTimeoutTime" BU_SG_REL_ VMCU SG_ 2566878219 Trailer4RelBodyLevel_RearLevel 3000;
BA_REL_ "GenSigTimeoutTime" BU_SG_REL_ VMCU SG_ 2566878219 Trailer4RelBodyLevel_RearLevel 600;
BA_REL_ "GenSigFirstTimeoutTime" BU_SG_REL_ IC3 SG_ 2566878219 Trailer4BrkLining_Warning_ISig_3 3000;
BA_REL_ "GenSigTimeoutTime" BU_SG_REL_ IC3 SG_ 2566878219 Trailer4BrkLining_Warning_ISig_3 600;
BA_REL_ "GenSigFirstTimeoutTime" BU_SG_REL_ IC3 SG_ 2566878219 Trailer4NormalLevel_LvlPos_ISig_ 3000;
BA_REL_ "GenSigTimeoutTime" BU_SG_REL_ IC3 SG_ 2566878219 Trailer4NormalLevel_LvlPos_ISig_ 600;
BA_REL_ "GenSigFirstTimeoutTime" BU_SG_REL_ VMCU SG_ 2566878219 Trailer4RelBodyLevel_FrontLevel 3000;
BA_REL_ "GenSigTimeoutTime" BU_SG_REL_ VMCU SG_ 2566878219 Trailer4RelBodyLevel_FrontLevel 600;
BA_REL_ "GenSigFirstTimeoutTime" BU_SG_REL_ IC3 SG_ 2566878219 Trailer4RampLevel_LvlPos_ISig_3 3000;
BA_REL_ "GenSigTimeoutTime" BU_SG_REL_ IC3 SG_ 2566878219 Trailer4RampLevel_LvlPos_ISig_3 600;
BA_REL_ "GenSigFirstTimeoutTime" BU_SG_REL_ IC3 SG_ 2566878219 Trailer4RampLevel_LvlStatus_ISig 3000;
BA_REL_ "GenSigTimeoutTime" BU_SG_REL_ IC3 SG_ 2566878219 Trailer4RampLevel_LvlStatus_ISig 600;
BA_REL_ "GenSigFirstTimeoutTime" BU_SG_REL_ IC3 SG_ 2566878219 Trailer4BrkLining_Wear_ISig_3 3000;
BA_REL_ "GenSigTimeoutTime" BU_SG_REL_ IC3 SG_ 2566878219 Trailer4BrkLining_Wear_ISig_3 600;
BA_REL_ "GenSigFirstTimeoutTime" BU_SG_REL_ IC3 SG_ 2566878219 Trailer4NormalLevel_LvlStatus_IS 3000;
BA_REL_ "GenSigTimeoutTime" BU_SG_REL_ IC3 SG_ 2566878219 Trailer4NormalLevel_LvlStatus_IS 600;
BA_REL_ "GenSigFirstTimeoutTime" BU_SG_REL_ IC3 SG_ 2566878219 Trailer4BrkLining_BrkLnTireId_IS 3000;
BA_REL_ "GenSigTimeoutTime" BU_SG_REL_ IC3 SG_ 2566878219 Trailer4BrkLining_BrkLnTireId_IS 600;
BA_REL_ "GenSigFirstTimeoutTime" BU_SG_REL_ IC3 SG_ 2566877963 Trailer3RampLevel_LvlStatus_ISig 3000;
BA_REL_ "GenSigTimeoutTime" BU_SG_REL_ IC3 SG_ 2566877963 Trailer3RampLevel_LvlStatus_ISig 600;
BA_REL_ "GenSigFirstTimeoutTime" BU_SG_REL_ VMCU SG_ 2566877963 Trailer3RelBodyLevel_FrontLevel 3000;
BA_REL_ "GenSigTimeoutTime" BU_SG_REL_ VMCU SG_ 2566877963 Trailer3RelBodyLevel_FrontLevel 600;
BA_REL_ "GenSigFirstTimeoutTime" BU_SG_REL_ IC3 SG_ 2566877963 Trailer3RampLevel_LvlPos_ISig_3 3000;
BA_REL_ "GenSigTimeoutTime" BU_SG_REL_ IC3 SG_ 2566877963 Trailer3RampLevel_LvlPos_ISig_3 600;
BA_REL_ "GenSigFirstTimeoutTime" BU_SG_REL_ IC3 SG_ 2566877963 Trailer3BrkLining_BrkLnTireId_IS 3000;
BA_REL_ "GenSigTimeoutTime" BU_SG_REL_ IC3 SG_ 2566877963 Trailer3BrkLining_BrkLnTireId_IS 600;
BA_REL_ "GenSigFirstTimeoutTime" BU_SG_REL_ IC3 SG_ 2566877963 Trailer3BrkLining_Wear_ISig_3 3000;
BA_REL_ "GenSigTimeoutTime" BU_SG_REL_ IC3 SG_ 2566877963 Trailer3BrkLining_Wear_ISig_3 600;
BA_REL_ "GenSigFirstTimeoutTime" BU_SG_REL_ VMCU SG_ 2566877963 Trailer3RelBodyLevel_RearLevel 3000;
BA_REL_ "GenSigTimeoutTime" BU_SG_REL_ VMCU SG_ 2566877963 Trailer3RelBodyLevel_RearLevel 600;
BA_REL_ "GenSigFirstTimeoutTime" BU_SG_REL_ IC3 SG_ 2566877963 Trailer3NormalLevel_LvlStatus_IS 3000;
BA_REL_ "GenSigTimeoutTime" BU_SG_REL_ IC3 SG_ 2566877963 Trailer3NormalLevel_LvlStatus_IS 600;
BA_REL_ "GenSigFirstTimeoutTime" BU_SG_REL_ IC3 SG_ 2566877963 Trailer3BrkLining_Warning_ISig_3 3000;
BA_REL_ "GenSigTimeoutTime" BU_SG_REL_ IC3 SG_ 2566877963 Trailer3BrkLining_Warning_ISig_3 600;
BA_REL_ "GenSigFirstTimeoutTime" BU_SG_REL_ IC3 SG_ 2566877963 Trailer3NormalLevel_LvlPos_ISig_ 3000;
BA_REL_ "GenSigTimeoutTime" BU_SG_REL_ IC3 SG_ 2566877963 Trailer3NormalLevel_LvlPos_ISig_ 600;
BA_REL_ "GenSigFirstTimeoutTime" BU_SG_REL_ IC3 SG_ 2566877707 Trailer2BrkLining_BrkLnTireId_IS 3000;
BA_REL_ "GenSigTimeoutTime" BU_SG_REL_ IC3 SG_ 2566877707 Trailer2BrkLining_BrkLnTireId_IS 600;
BA_REL_ "GenSigFirstTimeoutTime" BU_SG_REL_ IC3 SG_ 2566877707 Trailer2NormalLevel_LvlStatus_IS 3000;
BA_REL_ "GenSigTimeoutTime" BU_SG_REL_ IC3 SG_ 2566877707 Trailer2NormalLevel_LvlStatus_IS 600;
BA_REL_ "GenSigFirstTimeoutTime" BU_SG_REL_ IC3 SG_ 2566877707 Trailer2BrkLining_Warning_ISig_3 3000;
BA_REL_ "GenSigTimeoutTime" BU_SG_REL_ IC3 SG_ 2566877707 Trailer2BrkLining_Warning_ISig_3 600;
BA_REL_ "GenSigFirstTimeoutTime" BU_SG_REL_ IC3 SG_ 2566877707 Trailer2NormalLevel_LvlPos_ISig_ 3000;
BA_REL_ "GenSigTimeoutTime" BU_SG_REL_ IC3 SG_ 2566877707 Trailer2NormalLevel_LvlPos_ISig_ 600;
BA_REL_ "GenSigFirstTimeoutTime" BU_SG_REL_ VMCU SG_ 2566877707 Trailer2RelBodyLevel_FrontLevel 3000;
BA_REL_ "GenSigTimeoutTime" BU_SG_REL_ VMCU SG_ 2566877707 Trailer2RelBodyLevel_FrontLevel 600;
BA_REL_ "GenSigFirstTimeoutTime" BU_SG_REL_ VMCU SG_ 2566877707 Trailer2RelBodyLevel_RearLevel 3000;
BA_REL_ "GenSigTimeoutTime" BU_SG_REL_ VMCU SG_ 2566877707 Trailer2RelBodyLevel_RearLevel 600;
BA_REL_ "GenSigFirstTimeoutTime" BU_SG_REL_ IC3 SG_ 2566877707 Trailer2RampLevel_LvlStatus_ISig 3000;
BA_REL_ "GenSigTimeoutTime" BU_SG_REL_ IC3 SG_ 2566877707 Trailer2RampLevel_LvlStatus_ISig 600;
BA_REL_ "GenSigFirstTimeoutTime" BU_SG_REL_ IC3 SG_ 2566877707 Trailer2RampLevel_LvlPos_ISig_3 3000;
BA_REL_ "GenSigTimeoutTime" BU_SG_REL_ IC3 SG_ 2566877707 Trailer2RampLevel_LvlPos_ISig_3 600;
BA_REL_ "GenSigFirstTimeoutTime" BU_SG_REL_ IC3 SG_ 2566877707 Trailer2BrkLining_Wear_ISig_3 3000;
BA_REL_ "GenSigTimeoutTime" BU_SG_REL_ IC3 SG_ 2566877707 Trailer2BrkLining_Wear_ISig_3 600;
BA_REL_ "GenSigFirstTimeoutTime" BU_SG_REL_ VMCU SG_ 2566877451 Trailer1RelBodyLevel_RearLevel 3000;
BA_REL_ "GenSigTimeoutTime" BU_SG_REL_ VMCU SG_ 2566877451 Trailer1RelBodyLevel_RearLevel 600;
BA_REL_ "GenSigFirstTimeoutTime" BU_SG_REL_ IC3 SG_ 2566877451 Trailer1NormalLevel_LvlPos_ISig_ 3000;
BA_REL_ "GenSigTimeoutTime" BU_SG_REL_ IC3 SG_ 2566877451 Trailer1NormalLevel_LvlPos_ISig_ 600;
BA_REL_ "GenSigFirstTimeoutTime" BU_SG_REL_ IC3 SG_ 2566877451 Trailer1NormalLevel_LvlStatus_IS 3000;
BA_REL_ "GenSigTimeoutTime" BU_SG_REL_ IC3 SG_ 2566877451 Trailer1NormalLevel_LvlStatus_IS 600;
BA_REL_ "GenSigFirstTimeoutTime" BU_SG_REL_ IC3 SG_ 2566877451 Trailer1RampLevel_LvlPos_ISig_3 3000;
BA_REL_ "GenSigTimeoutTime" BU_SG_REL_ IC3 SG_ 2566877451 Trailer1RampLevel_LvlPos_ISig_3 600;
BA_REL_ "GenSigFirstTimeoutTime" BU_SG_REL_ IC3 SG_ 2566877451 Trailer1BrkLining_Warning_ISig_3 3000;
BA_REL_ "GenSigTimeoutTime" BU_SG_REL_ IC3 SG_ 2566877451 Trailer1BrkLining_Warning_ISig_3 600;
BA_REL_ "GenSigFirstTimeoutTime" BU_SG_REL_ IC3 SG_ 2566877451 Trailer1RampLevel_LvlStatus_ISig 3000;
BA_REL_ "GenSigTimeoutTime" BU_SG_REL_ IC3 SG_ 2566877451 Trailer1RampLevel_LvlStatus_ISig 600;
BA_REL_ "GenSigFirstTimeoutTime" BU_SG_REL_ IC3 SG_ 2566877451 Trailer1BrkLining_BrkLnTireId_IS 3000;
BA_REL_ "GenSigTimeoutTime" BU_SG_REL_ IC3 SG_ 2566877451 Trailer1BrkLining_BrkLnTireId_IS 600;
BA_REL_ "GenSigFirstTimeoutTime" BU_SG_REL_ IC3 SG_ 2566877451 Trailer1BrkLining_Wear_ISig_3 3000;
BA_REL_ "GenSigTimeoutTime" BU_SG_REL_ IC3 SG_ 2566877451 Trailer1BrkLining_Wear_ISig_3 600;
BA_REL_ "GenSigFirstTimeoutTime" BU_SG_REL_ VMCU SG_ 2566877451 Trailer1RelBodyLevel_FrontLevel 3000;
BA_REL_ "GenSigTimeoutTime" BU_SG_REL_ VMCU SG_ 2566877451 Trailer1RelBodyLevel_FrontLevel 600;
BA_REL_ "GenSigFirstTimeoutTime" BU_SG_REL_ IC3 SG_ 2566894859 Trailer5VIN_ISig_3 60000;
BA_REL_ "GenSigTimeoutTime" BU_SG_REL_ IC3 SG_ 2566894859 Trailer5VIN_ISig_3 60000;
BA_REL_ "GenSigFirstTimeoutTime" BU_SG_REL_ VMCU SG_ 2566894859 Trailer5VIN_ISig_3 60000;
BA_REL_ "GenSigTimeoutTime" BU_SG_REL_ VMCU SG_ 2566894859 Trailer5VIN_ISig_3 60000;
BA_REL_ "GenSigFirstTimeoutTime" BU_SG_REL_ VMCU SG_ 2566894603 Trailer4VIN_ISig_3 60000;
BA_REL_ "GenSigTimeoutTime" BU_SG_REL_ VMCU SG_ 2566894603 Trailer4VIN_ISig_3 60000;
BA_REL_ "GenSigFirstTimeoutTime" BU_SG_REL_ IC3 SG_ 2566894603 Trailer4VIN_ISig_3 60000;
BA_REL_ "GenSigTimeoutTime" BU_SG_REL_ IC3 SG_ 2566894603 Trailer4VIN_ISig_3 60000;
BA_REL_ "GenSigFirstTimeoutTime" BU_SG_REL_ VMCU SG_ 2566894347 Trailer3VIN_ISig_3 60000;
BA_REL_ "GenSigTimeoutTime" BU_SG_REL_ VMCU SG_ 2566894347 Trailer3VIN_ISig_3 60000;
BA_REL_ "GenSigFirstTimeoutTime" BU_SG_REL_ IC3 SG_ 2566894347 Trailer3VIN_ISig_3 60000;
BA_REL_ "GenSigTimeoutTime" BU_SG_REL_ IC3 SG_ 2566894347 Trailer3VIN_ISig_3 60000;
BA_REL_ "GenSigFirstTimeoutTime" BU_SG_REL_ VMCU SG_ 2566894091 Trailer2VIN_ISig_3 60000;
BA_REL_ "GenSigTimeoutTime" BU_SG_REL_ VMCU SG_ 2566894091 Trailer2VIN_ISig_3 60000;
BA_REL_ "GenSigFirstTimeoutTime" BU_SG_REL_ IC3 SG_ 2566894091 Trailer2VIN_ISig_3 60000;
BA_REL_ "GenSigTimeoutTime" BU_SG_REL_ IC3 SG_ 2566894091 Trailer2VIN_ISig_3 60000;
BA_REL_ "GenSigFirstTimeoutTime" BU_SG_REL_ IC3 SG_ 2566893835 Trailer1VIN_ISig_3 60000;
BA_REL_ "GenSigTimeoutTime" BU_SG_REL_ IC3 SG_ 2566893835 Trailer1VIN_ISig_3 60000;
BA_REL_ "GenSigFirstTimeoutTime" BU_SG_REL_ VMCU SG_ 2566893835 Trailer1VIN_ISig_3 60000;
BA_REL_ "GenSigTimeoutTime" BU_SG_REL_ VMCU SG_ 2566893835 Trailer1VIN_ISig_3 60000;
BA_REL_ "GenSigFirstTimeoutTime" BU_SG_REL_ VMCU SG_ 2566903051 Trailer5GeometricData_Index_ISig 24000;
BA_REL_ "GenSigTimeoutTime" BU_SG_REL_ VMCU SG_ 2566903051 Trailer5GeometricData_Index_ISig 6000;
BA_REL_ "GenSigFirstTimeoutTime" BU_SG_REL_ IC3 SG_ 2566903051 Trailer5GeometricData_Index_ISig 24000;
BA_REL_ "GenSigTimeoutTime" BU_SG_REL_ IC3 SG_ 2566903051 Trailer5GeometricData_Index_ISig 6000;
BA_REL_ "GenSigFirstTimeoutTime" BU_SG_REL_ DACU SG_ 2566903051 Trailer5GeometricData_Index_ISig 24000;
BA_REL_ "GenSigTimeoutTime" BU_SG_REL_ DACU SG_ 2566903051 Trailer5GeometricData_Index_ISig 6000;
BA_REL_ "GenSigFirstTimeoutTime" BU_SG_REL_ VMCU SG_ 2566903051 PadChangePredictionAxleNumber 24000;
BA_REL_ "GenSigTimeoutTime" BU_SG_REL_ VMCU SG_ 2566903051 PadChangePredictionAxleNumber 6000;
BA_REL_ "GenSigFirstTimeoutTime" BU_SG_REL_ EMS SG_ 2566903051 XBRBrakingCapacityTime 24000;
BA_REL_ "GenSigTimeoutTime" BU_SG_REL_ EMS SG_ 2566903051 XBRBrakingCapacityTime 6000;
BA_REL_ "GenSigFirstTimeoutTime" BU_SG_REL_ TECU SG_ 2566903051 XBRBrakingCapacityTime 24000;
BA_REL_ "GenSigTimeoutTime" BU_SG_REL_ TECU SG_ 2566903051 XBRBrakingCapacityTime 6000;
BA_REL_ "GenSigFirstTimeoutTime" BU_SG_REL_ DACU SG_ 2566903051 XBRBrakingCapacityTime 24000;
BA_REL_ "GenSigTimeoutTime" BU_SG_REL_ DACU SG_ 2566903051 XBRBrakingCapacityTime 6000;
BA_REL_ "GenSigFirstTimeoutTime" BU_SG_REL_ IC3 SG_ 2566903051 Trailer5AxleLoadSum_ISig_3 24000;
BA_REL_ "GenSigTimeoutTime" BU_SG_REL_ IC3 SG_ 2566903051 Trailer5AxleLoadSum_ISig_3 6000;
BA_REL_ "GenSigFirstTimeoutTime" BU_SG_REL_ VMCU SG_ 2566903051 Trailer5AxleLoadSum_ISig_3 24000;
BA_REL_ "GenSigTimeoutTime" BU_SG_REL_ VMCU SG_ 2566903051 Trailer5AxleLoadSum_ISig_3 6000;
BA_REL_ "GenSigFirstTimeoutTime" BU_SG_REL_ TECU SG_ 2566903051 XBRBrakingCapacityTemperature 24000;
BA_REL_ "GenSigTimeoutTime" BU_SG_REL_ TECU SG_ 2566903051 XBRBrakingCapacityTemperature 6000;
BA_REL_ "GenSigFirstTimeoutTime" BU_SG_REL_ DACU SG_ 2566903051 XBRBrakingCapacityTemperature 24000;
BA_REL_ "GenSigTimeoutTime" BU_SG_REL_ DACU SG_ 2566903051 XBRBrakingCapacityTemperature 6000;
BA_REL_ "GenSigFirstTimeoutTime" BU_SG_REL_ EMS SG_ 2566903051 XBRBrakingCapacityTemperature 24000;
BA_REL_ "GenSigTimeoutTime" BU_SG_REL_ EMS SG_ 2566903051 XBRBrakingCapacityTemperature 6000;
BA_REL_ "GenSigFirstTimeoutTime" BU_SG_REL_ VMCU SG_ 2566903051 Trailer5GeometricData_Content_IS 24000;
BA_REL_ "GenSigTimeoutTime" BU_SG_REL_ VMCU SG_ 2566903051 Trailer5GeometricData_Content_IS 6000;
BA_REL_ "GenSigFirstTimeoutTime" BU_SG_REL_ IC3 SG_ 2566903051 Trailer5GeometricData_Content_IS 24000;
BA_REL_ "GenSigTimeoutTime" BU_SG_REL_ IC3 SG_ 2566903051 Trailer5GeometricData_Content_IS 6000;
BA_REL_ "GenSigFirstTimeoutTime" BU_SG_REL_ DACU SG_ 2566903051 Trailer5GeometricData_Content_IS 24000;
BA_REL_ "GenSigTimeoutTime" BU_SG_REL_ DACU SG_ 2566903051 Trailer5GeometricData_Content_IS 6000;
BA_REL_ "GenSigFirstTimeoutTime" BU_SG_REL_ IC3 SG_ 2566903051 LiningWearWarning 24000;
BA_REL_ "GenSigTimeoutTime" BU_SG_REL_ IC3 SG_ 2566903051 LiningWearWarning 6000;
BA_REL_ "GenSigFirstTimeoutTime" BU_SG_REL_ IC3 SG_ 2566902539 Trailer3GeometricData_Index_ISig 24000;
BA_REL_ "GenSigTimeoutTime" BU_SG_REL_ IC3 SG_ 2566902539 Trailer3GeometricData_Index_ISig 6000;
BA_REL_ "GenSigFirstTimeoutTime" BU_SG_REL_ DACU SG_ 2566902539 Trailer3GeometricData_Index_ISig 24000;
BA_REL_ "GenSigTimeoutTime" BU_SG_REL_ DACU SG_ 2566902539 Trailer3GeometricData_Index_ISig 6000;
BA_REL_ "GenSigFirstTimeoutTime" BU_SG_REL_ VMCU SG_ 2566902539 Trailer3GeometricData_Index_ISig 24000;
BA_REL_ "GenSigTimeoutTime" BU_SG_REL_ VMCU SG_ 2566902539 Trailer3GeometricData_Index_ISig 6000;
BA_REL_ "GenSigFirstTimeoutTime" BU_SG_REL_ DACU SG_ 2566902539 Trailer4GeometricData_Content_IS 24000;
BA_REL_ "GenSigTimeoutTime" BU_SG_REL_ DACU SG_ 2566902539 Trailer4GeometricData_Content_IS 6000;
BA_REL_ "GenSigFirstTimeoutTime" BU_SG_REL_ IC3 SG_ 2566902539 Trailer4GeometricData_Content_IS 24000;
BA_REL_ "GenSigTimeoutTime" BU_SG_REL_ IC3 SG_ 2566902539 Trailer4GeometricData_Content_IS 6000;
BA_REL_ "GenSigFirstTimeoutTime" BU_SG_REL_ VMCU SG_ 2566902539 Trailer4GeometricData_Content_IS 24000;
BA_REL_ "GenSigTimeoutTime" BU_SG_REL_ VMCU SG_ 2566902539 Trailer4GeometricData_Content_IS 6000;
BA_REL_ "GenSigFirstTimeoutTime" BU_SG_REL_ IC3 SG_ 2566902539 Trailer3GeometricData_Content_IS 24000;
BA_REL_ "GenSigTimeoutTime" BU_SG_REL_ IC3 SG_ 2566902539 Trailer3GeometricData_Content_IS 6000;
BA_REL_ "GenSigFirstTimeoutTime" BU_SG_REL_ DACU SG_ 2566902539 Trailer3GeometricData_Content_IS 24000;
BA_REL_ "GenSigTimeoutTime" BU_SG_REL_ DACU SG_ 2566902539 Trailer3GeometricData_Content_IS 6000;
BA_REL_ "GenSigFirstTimeoutTime" BU_SG_REL_ VMCU SG_ 2566902539 Trailer3GeometricData_Content_IS 24000;
BA_REL_ "GenSigTimeoutTime" BU_SG_REL_ VMCU SG_ 2566902539 Trailer3GeometricData_Content_IS 6000;
BA_REL_ "GenSigFirstTimeoutTime" BU_SG_REL_ IC3 SG_ 2566902539 Trailer3AxleLoadSum_ISig_3 24000;
BA_REL_ "GenSigTimeoutTime" BU_SG_REL_ IC3 SG_ 2566902539 Trailer3AxleLoadSum_ISig_3 6000;
BA_REL_ "GenSigFirstTimeoutTime" BU_SG_REL_ TECU SG_ 2566902539 Trailer3AxleLoadSum_ISig_3 24000;
BA_REL_ "GenSigTimeoutTime" BU_SG_REL_ TECU SG_ 2566902539 Trailer3AxleLoadSum_ISig_3 6000;
BA_REL_ "GenSigFirstTimeoutTime" BU_SG_REL_ VMCU SG_ 2566902539 Trailer3AxleLoadSum_ISig_3 24000;
BA_REL_ "GenSigTimeoutTime" BU_SG_REL_ VMCU SG_ 2566902539 Trailer3AxleLoadSum_ISig_3 6000;
BA_REL_ "GenSigFirstTimeoutTime" BU_SG_REL_ IC3 SG_ 2566902539 Trailer4GeometricData_Index_ISig 24000;
BA_REL_ "GenSigTimeoutTime" BU_SG_REL_ IC3 SG_ 2566902539 Trailer4GeometricData_Index_ISig 6000;
BA_REL_ "GenSigFirstTimeoutTime" BU_SG_REL_ DACU SG_ 2566902539 Trailer4GeometricData_Index_ISig 24000;
BA_REL_ "GenSigTimeoutTime" BU_SG_REL_ DACU SG_ 2566902539 Trailer4GeometricData_Index_ISig 6000;
BA_REL_ "GenSigFirstTimeoutTime" BU_SG_REL_ VMCU SG_ 2566902539 Trailer4GeometricData_Index_ISig 24000;
BA_REL_ "GenSigTimeoutTime" BU_SG_REL_ VMCU SG_ 2566902539 Trailer4GeometricData_Index_ISig 6000;
BA_REL_ "GenSigFirstTimeoutTime" BU_SG_REL_ TECU SG_ 2566902539 Trailer4AxleLoadSum_ISig_3 24000;
BA_REL_ "GenSigTimeoutTime" BU_SG_REL_ TECU SG_ 2566902539 Trailer4AxleLoadSum_ISig_3 6000;
BA_REL_ "GenSigFirstTimeoutTime" BU_SG_REL_ VMCU SG_ 2566902539 Trailer4AxleLoadSum_ISig_3 24000;
BA_REL_ "GenSigTimeoutTime" BU_SG_REL_ VMCU SG_ 2566902539 Trailer4AxleLoadSum_ISig_3 6000;
BA_REL_ "GenSigFirstTimeoutTime" BU_SG_REL_ IC3 SG_ 2566902539 Trailer4AxleLoadSum_ISig_3 24000;
BA_REL_ "GenSigTimeoutTime" BU_SG_REL_ IC3 SG_ 2566902539 Trailer4AxleLoadSum_ISig_3 6000;
BA_REL_ "GenSigFirstTimeoutTime" BU_SG_REL_ VMCU SG_ 2566902027 Trailer2GeometricData_Index_ISig 24000;
BA_REL_ "GenSigTimeoutTime" BU_SG_REL_ VMCU SG_ 2566902027 Trailer2GeometricData_Index_ISig 6000;
BA_REL_ "GenSigFirstTimeoutTime" BU_SG_REL_ DACU SG_ 2566902027 Trailer2GeometricData_Index_ISig 24000;
BA_REL_ "GenSigTimeoutTime" BU_SG_REL_ DACU SG_ 2566902027 Trailer2GeometricData_Index_ISig 6000;
BA_REL_ "GenSigFirstTimeoutTime" BU_SG_REL_ IC3 SG_ 2566902027 Trailer2GeometricData_Index_ISig 24000;
BA_REL_ "GenSigTimeoutTime" BU_SG_REL_ IC3 SG_ 2566902027 Trailer2GeometricData_Index_ISig 6000;
BA_REL_ "GenSigFirstTimeoutTime" BU_SG_REL_ DACU SG_ 2566902027 Trailer1GeometricData_Content_IS 24000;
BA_REL_ "GenSigTimeoutTime" BU_SG_REL_ DACU SG_ 2566902027 Trailer1GeometricData_Content_IS 6000;
BA_REL_ "GenSigFirstTimeoutTime" BU_SG_REL_ VMCU SG_ 2566902027 Trailer1GeometricData_Content_IS 24000;
BA_REL_ "GenSigTimeoutTime" BU_SG_REL_ VMCU SG_ 2566902027 Trailer1GeometricData_Content_IS 6000;
BA_REL_ "GenSigFirstTimeoutTime" BU_SG_REL_ IC3 SG_ 2566902027 Trailer1GeometricData_Content_IS 24000;
BA_REL_ "GenSigTimeoutTime" BU_SG_REL_ IC3 SG_ 2566902027 Trailer1GeometricData_Content_IS 6000;
BA_REL_ "GenSigFirstTimeoutTime" BU_SG_REL_ IC3 SG_ 2566902027 Trailer1GeometricData_Index_ISig 24000;
BA_REL_ "GenSigTimeoutTime" BU_SG_REL_ IC3 SG_ 2566902027 Trailer1GeometricData_Index_ISig 6000;
BA_REL_ "GenSigFirstTimeoutTime" BU_SG_REL_ DACU SG_ 2566902027 Trailer1GeometricData_Index_ISig 24000;
BA_REL_ "GenSigTimeoutTime" BU_SG_REL_ DACU SG_ 2566902027 Trailer1GeometricData_Index_ISig 6000;
BA_REL_ "GenSigFirstTimeoutTime" BU_SG_REL_ VMCU SG_ 2566902027 Trailer1GeometricData_Index_ISig 24000;
BA_REL_ "GenSigTimeoutTime" BU_SG_REL_ VMCU SG_ 2566902027 Trailer1GeometricData_Index_ISig 6000;
BA_REL_ "GenSigFirstTimeoutTime" BU_SG_REL_ TECU SG_ 2566902027 Trailer2AxleLoadSum_ISig_3 24000;
BA_REL_ "GenSigTimeoutTime" BU_SG_REL_ TECU SG_ 2566902027 Trailer2AxleLoadSum_ISig_3 6000;
BA_REL_ "GenSigFirstTimeoutTime" BU_SG_REL_ IC3 SG_ 2566902027 Trailer2AxleLoadSum_ISig_3 24000;
BA_REL_ "GenSigTimeoutTime" BU_SG_REL_ IC3 SG_ 2566902027 Trailer2AxleLoadSum_ISig_3 6000;
BA_REL_ "GenSigFirstTimeoutTime" BU_SG_REL_ VMCU SG_ 2566902027 Trailer2AxleLoadSum_ISig_3 24000;
BA_REL_ "GenSigTimeoutTime" BU_SG_REL_ VMCU SG_ 2566902027 Trailer2AxleLoadSum_ISig_3 6000;
BA_REL_ "GenSigFirstTimeoutTime" BU_SG_REL_ IC3 SG_ 2566902027 Trailer1AxleLoadSum_ISig_3 24000;
BA_REL_ "GenSigTimeoutTime" BU_SG_REL_ IC3 SG_ 2566902027 Trailer1AxleLoadSum_ISig_3 6000;
BA_REL_ "GenSigFirstTimeoutTime" BU_SG_REL_ TECU SG_ 2566902027 Trailer1AxleLoadSum_ISig_3 24000;
BA_REL_ "GenSigTimeoutTime" BU_SG_REL_ TECU SG_ 2566902027 Trailer1AxleLoadSum_ISig_3 6000;
BA_REL_ "GenSigFirstTimeoutTime" BU_SG_REL_ VMCU SG_ 2566902027 Trailer1AxleLoadSum_ISig_3 24000;
BA_REL_ "GenSigTimeoutTime" BU_SG_REL_ VMCU SG_ 2566902027 Trailer1AxleLoadSum_ISig_3 6000;
BA_REL_ "GenSigFirstTimeoutTime" BU_SG_REL_ DACU SG_ 2566902027 Trailer2GeometricData_Content_IS 24000;
BA_REL_ "GenSigTimeoutTime" BU_SG_REL_ DACU SG_ 2566902027 Trailer2GeometricData_Content_IS 6000;
BA_REL_ "GenSigFirstTimeoutTime" BU_SG_REL_ VMCU SG_ 2566902027 Trailer2GeometricData_Content_IS 24000;
BA_REL_ "GenSigTimeoutTime" BU_SG_REL_ VMCU SG_ 2566902027 Trailer2GeometricData_Content_IS 6000;
BA_REL_ "GenSigFirstTimeoutTime" BU_SG_REL_ IC3 SG_ 2566902027 Trailer2GeometricData_Content_IS 24000;
BA_REL_ "GenSigTimeoutTime" BU_SG_REL_ IC3 SG_ 2566902027 Trailer2GeometricData_Content_IS 6000;
BA_REL_ "GenSigFirstTimeoutTime" BU_SG_REL_ VMCU SG_ 2566886667 Trailer5LiftAxle1Pos_ISig_3 3000;
BA_REL_ "GenSigTimeoutTime" BU_SG_REL_ VMCU SG_ 2566886667 Trailer5LiftAxle1Pos_ISig_3 600;
BA_REL_ "GenSigFirstTimeoutTime" BU_SG_REL_ BBM SG_ 2566886667 Trailer5LiftAxle1Pos_ISig_3 3000;
BA_REL_ "GenSigTimeoutTime" BU_SG_REL_ BBM SG_ 2566886667 Trailer5LiftAxle1Pos_ISig_3 600;
BA_REL_ "GenSigFirstTimeoutTime" BU_SG_REL_ CIOM SG_ 2566886667 Trailer5LiftAxle1Pos_ISig_3 3000;
BA_REL_ "GenSigTimeoutTime" BU_SG_REL_ CIOM SG_ 2566886667 Trailer5LiftAxle1Pos_ISig_3 600;
BA_REL_ "GenSigFirstTimeoutTime" BU_SG_REL_ IC3 SG_ 2566886667 Trailer5LiftAxle1Pos_ISig_3 3000;
BA_REL_ "GenSigTimeoutTime" BU_SG_REL_ IC3 SG_ 2566886667 Trailer5LiftAxle1Pos_ISig_3 600;
BA_REL_ "GenSigFirstTimeoutTime" BU_SG_REL_ BBM SG_ 2566886667 Trailer5LiftAxle2Pos_ISig_3 3000;
BA_REL_ "GenSigTimeoutTime" BU_SG_REL_ BBM SG_ 2566886667 Trailer5LiftAxle2Pos_ISig_3 600;
BA_REL_ "GenSigFirstTimeoutTime" BU_SG_REL_ CIOM SG_ 2566886667 Trailer5LiftAxle2Pos_ISig_3 3000;
BA_REL_ "GenSigTimeoutTime" BU_SG_REL_ CIOM SG_ 2566886667 Trailer5LiftAxle2Pos_ISig_3 600;
BA_REL_ "GenSigFirstTimeoutTime" BU_SG_REL_ VMCU SG_ 2566886667 Trailer5LiftAxle2Pos_ISig_3 3000;
BA_REL_ "GenSigTimeoutTime" BU_SG_REL_ VMCU SG_ 2566886667 Trailer5LiftAxle2Pos_ISig_3 600;
BA_REL_ "GenSigFirstTimeoutTime" BU_SG_REL_ IC3 SG_ 2566886667 Trailer5LiftAxle2Pos_ISig_3 3000;
BA_REL_ "GenSigTimeoutTime" BU_SG_REL_ IC3 SG_ 2566886667 Trailer5LiftAxle2Pos_ISig_3 600;
BA_REL_ "GenSigFirstTimeoutTime" BU_SG_REL_ BBM SG_ 2566886667 Trailer5AxleLoad_AxleLoad_ISig_3 3000;
BA_REL_ "GenSigTimeoutTime" BU_SG_REL_ BBM SG_ 2566886667 Trailer5AxleLoad_AxleLoad_ISig_3 600;
BA_REL_ "GenSigFirstTimeoutTime" BU_SG_REL_ VMCU SG_ 2566886667 Trailer5AxleLoad_AxleLoad_ISig_3 3000;
BA_REL_ "GenSigTimeoutTime" BU_SG_REL_ VMCU SG_ 2566886667 Trailer5AxleLoad_AxleLoad_ISig_3 600;
BA_REL_ "GenSigFirstTimeoutTime" BU_SG_REL_ IC3 SG_ 2566886667 Trailer5AxleLoad_AxleLoad_ISig_3 3000;
BA_REL_ "GenSigTimeoutTime" BU_SG_REL_ IC3 SG_ 2566886667 Trailer5AxleLoad_AxleLoad_ISig_3 600;
BA_REL_ "GenSigFirstTimeoutTime" BU_SG_REL_ VMCU SG_ 2566886667 Trailer5AxleLoad_AxleId_ISig_3 3000;
BA_REL_ "GenSigTimeoutTime" BU_SG_REL_ VMCU SG_ 2566886667 Trailer5AxleLoad_AxleId_ISig_3 600;
BA_REL_ "GenSigFirstTimeoutTime" BU_SG_REL_ BBM SG_ 2566886667 Trailer5AxleLoad_AxleId_ISig_3 3000;
BA_REL_ "GenSigTimeoutTime" BU_SG_REL_ BBM SG_ 2566886667 Trailer5AxleLoad_AxleId_ISig_3 600;
BA_REL_ "GenSigFirstTimeoutTime" BU_SG_REL_ IC3 SG_ 2566886667 Trailer5AxleLoad_AxleId_ISig_3 3000;
BA_REL_ "GenSigTimeoutTime" BU_SG_REL_ IC3 SG_ 2566886667 Trailer5AxleLoad_AxleId_ISig_3 600;
BA_REL_ "GenSigFirstTimeoutTime" BU_SG_REL_ VMCU SG_ 2566886155 Trailer3AxleLoad_AxleId_ISig_3 3000;
BA_REL_ "GenSigTimeoutTime" BU_SG_REL_ VMCU SG_ 2566886155 Trailer3AxleLoad_AxleId_ISig_3 600;
BA_REL_ "GenSigFirstTimeoutTime" BU_SG_REL_ BBM SG_ 2566886155 Trailer3AxleLoad_AxleId_ISig_3 3000;
BA_REL_ "GenSigTimeoutTime" BU_SG_REL_ BBM SG_ 2566886155 Trailer3AxleLoad_AxleId_ISig_3 600;
BA_REL_ "GenSigFirstTimeoutTime" BU_SG_REL_ IC3 SG_ 2566886155 Trailer3AxleLoad_AxleId_ISig_3 3000;
BA_REL_ "GenSigTimeoutTime" BU_SG_REL_ IC3 SG_ 2566886155 Trailer3AxleLoad_AxleId_ISig_3 600;
BA_REL_ "GenSigFirstTimeoutTime" BU_SG_REL_ BBM SG_ 2566886155 Trailer3LiftAxle1Pos_ISig_3 3000;
BA_REL_ "GenSigTimeoutTime" BU_SG_REL_ BBM SG_ 2566886155 Trailer3LiftAxle1Pos_ISig_3 600;
BA_REL_ "GenSigFirstTimeoutTime" BU_SG_REL_ VMCU SG_ 2566886155 Trailer3LiftAxle1Pos_ISig_3 3000;
BA_REL_ "GenSigTimeoutTime" BU_SG_REL_ VMCU SG_ 2566886155 Trailer3LiftAxle1Pos_ISig_3 600;
BA_REL_ "GenSigFirstTimeoutTime" BU_SG_REL_ CIOM SG_ 2566886155 Trailer3LiftAxle1Pos_ISig_3 3000;
BA_REL_ "GenSigTimeoutTime" BU_SG_REL_ CIOM SG_ 2566886155 Trailer3LiftAxle1Pos_ISig_3 600;
BA_REL_ "GenSigFirstTimeoutTime" BU_SG_REL_ IC3 SG_ 2566886155 Trailer3LiftAxle1Pos_ISig_3 3000;
BA_REL_ "GenSigTimeoutTime" BU_SG_REL_ IC3 SG_ 2566886155 Trailer3LiftAxle1Pos_ISig_3 600;
BA_REL_ "GenSigFirstTimeoutTime" BU_SG_REL_ BBM SG_ 2566886155 Trailer4LiftAxle2Pos_ISig_3 3000;
BA_REL_ "GenSigTimeoutTime" BU_SG_REL_ BBM SG_ 2566886155 Trailer4LiftAxle2Pos_ISig_3 600;
BA_REL_ "GenSigFirstTimeoutTime" BU_SG_REL_ VMCU SG_ 2566886155 Trailer4LiftAxle2Pos_ISig_3 3000;
BA_REL_ "GenSigTimeoutTime" BU_SG_REL_ VMCU SG_ 2566886155 Trailer4LiftAxle2Pos_ISig_3 600;
BA_REL_ "GenSigFirstTimeoutTime" BU_SG_REL_ CIOM SG_ 2566886155 Trailer4LiftAxle2Pos_ISig_3 3000;
BA_REL_ "GenSigTimeoutTime" BU_SG_REL_ CIOM SG_ 2566886155 Trailer4LiftAxle2Pos_ISig_3 600;
BA_REL_ "GenSigFirstTimeoutTime" BU_SG_REL_ IC3 SG_ 2566886155 Trailer4LiftAxle2Pos_ISig_3 3000;
BA_REL_ "GenSigTimeoutTime" BU_SG_REL_ IC3 SG_ 2566886155 Trailer4LiftAxle2Pos_ISig_3 600;
BA_REL_ "GenSigFirstTimeoutTime" BU_SG_REL_ BBM SG_ 2566886155 Trailer4AxleLoad_AxleLoad_ISig_3 3000;
BA_REL_ "GenSigTimeoutTime" BU_SG_REL_ BBM SG_ 2566886155 Trailer4AxleLoad_AxleLoad_ISig_3 600;
BA_REL_ "GenSigFirstTimeoutTime" BU_SG_REL_ VMCU SG_ 2566886155 Trailer4AxleLoad_AxleLoad_ISig_3 3000;
BA_REL_ "GenSigTimeoutTime" BU_SG_REL_ VMCU SG_ 2566886155 Trailer4AxleLoad_AxleLoad_ISig_3 600;
BA_REL_ "GenSigFirstTimeoutTime" BU_SG_REL_ IC3 SG_ 2566886155 Trailer4AxleLoad_AxleLoad_ISig_3 3000;
BA_REL_ "GenSigTimeoutTime" BU_SG_REL_ IC3 SG_ 2566886155 Trailer4AxleLoad_AxleLoad_ISig_3 600;
BA_REL_ "GenSigFirstTimeoutTime" BU_SG_REL_ CIOM SG_ 2566886155 Trailer3LiftAxle2Pos_ISig_3 3000;
BA_REL_ "GenSigTimeoutTime" BU_SG_REL_ CIOM SG_ 2566886155 Trailer3LiftAxle2Pos_ISig_3 600;
BA_REL_ "GenSigFirstTimeoutTime" BU_SG_REL_ BBM SG_ 2566886155 Trailer3LiftAxle2Pos_ISig_3 3000;
BA_REL_ "GenSigTimeoutTime" BU_SG_REL_ BBM SG_ 2566886155 Trailer3LiftAxle2Pos_ISig_3 600;
BA_REL_ "GenSigFirstTimeoutTime" BU_SG_REL_ VMCU SG_ 2566886155 Trailer3LiftAxle2Pos_ISig_3 3000;
BA_REL_ "GenSigTimeoutTime" BU_SG_REL_ VMCU SG_ 2566886155 Trailer3LiftAxle2Pos_ISig_3 600;
BA_REL_ "GenSigFirstTimeoutTime" BU_SG_REL_ IC3 SG_ 2566886155 Trailer3LiftAxle2Pos_ISig_3 3000;
BA_REL_ "GenSigTimeoutTime" BU_SG_REL_ IC3 SG_ 2566886155 Trailer3LiftAxle2Pos_ISig_3 600;
BA_REL_ "GenSigFirstTimeoutTime" BU_SG_REL_ BBM SG_ 2566886155 Trailer3AxleLoad_AxleLoad_ISig_3 3000;
BA_REL_ "GenSigTimeoutTime" BU_SG_REL_ BBM SG_ 2566886155 Trailer3AxleLoad_AxleLoad_ISig_3 600;
BA_REL_ "GenSigFirstTimeoutTime" BU_SG_REL_ VMCU SG_ 2566886155 Trailer3AxleLoad_AxleLoad_ISig_3 3000;
BA_REL_ "GenSigTimeoutTime" BU_SG_REL_ VMCU SG_ 2566886155 Trailer3AxleLoad_AxleLoad_ISig_3 600;
BA_REL_ "GenSigFirstTimeoutTime" BU_SG_REL_ IC3 SG_ 2566886155 Trailer3AxleLoad_AxleLoad_ISig_3 3000;
BA_REL_ "GenSigTimeoutTime" BU_SG_REL_ IC3 SG_ 2566886155 Trailer3AxleLoad_AxleLoad_ISig_3 600;
BA_REL_ "GenSigFirstTimeoutTime" BU_SG_REL_ CIOM SG_ 2566886155 Trailer4LiftAxle1Pos_ISig_3 3000;
BA_REL_ "GenSigTimeoutTime" BU_SG_REL_ CIOM SG_ 2566886155 Trailer4LiftAxle1Pos_ISig_3 600;
BA_REL_ "GenSigFirstTimeoutTime" BU_SG_REL_ IC3 SG_ 2566886155 Trailer4LiftAxle1Pos_ISig_3 3000;
BA_REL_ "GenSigTimeoutTime" BU_SG_REL_ IC3 SG_ 2566886155 Trailer4LiftAxle1Pos_ISig_3 600;
BA_REL_ "GenSigFirstTimeoutTime" BU_SG_REL_ VMCU SG_ 2566886155 Trailer4LiftAxle1Pos_ISig_3 3000;
BA_REL_ "GenSigTimeoutTime" BU_SG_REL_ VMCU SG_ 2566886155 Trailer4LiftAxle1Pos_ISig_3 600;
BA_REL_ "GenSigFirstTimeoutTime" BU_SG_REL_ BBM SG_ 2566886155 Trailer4LiftAxle1Pos_ISig_3 3000;
BA_REL_ "GenSigTimeoutTime" BU_SG_REL_ BBM SG_ 2566886155 Trailer4LiftAxle1Pos_ISig_3 600;
BA_REL_ "GenSigFirstTimeoutTime" BU_SG_REL_ VMCU SG_ 2566886155 Trailer4AxleLoad_AxleId_ISig_3 3000;
BA_REL_ "GenSigTimeoutTime" BU_SG_REL_ VMCU SG_ 2566886155 Trailer4AxleLoad_AxleId_ISig_3 600;
BA_REL_ "GenSigFirstTimeoutTime" BU_SG_REL_ IC3 SG_ 2566886155 Trailer4AxleLoad_AxleId_ISig_3 3000;
BA_REL_ "GenSigTimeoutTime" BU_SG_REL_ IC3 SG_ 2566886155 Trailer4AxleLoad_AxleId_ISig_3 600;
BA_REL_ "GenSigFirstTimeoutTime" BU_SG_REL_ BBM SG_ 2566886155 Trailer4AxleLoad_AxleId_ISig_3 3000;
BA_REL_ "GenSigTimeoutTime" BU_SG_REL_ BBM SG_ 2566886155 Trailer4AxleLoad_AxleId_ISig_3 600;
BA_REL_ "GenSigFirstTimeoutTime" BU_SG_REL_ VMCU SG_ 2566885643 Trailer2AxleLoad_AxleId_ISig_3 3000;
BA_REL_ "GenSigTimeoutTime" BU_SG_REL_ VMCU SG_ 2566885643 Trailer2AxleLoad_AxleId_ISig_3 600;
BA_REL_ "GenSigFirstTimeoutTime" BU_SG_REL_ BBM SG_ 2566885643 Trailer2AxleLoad_AxleId_ISig_3 3000;
BA_REL_ "GenSigTimeoutTime" BU_SG_REL_ BBM SG_ 2566885643 Trailer2AxleLoad_AxleId_ISig_3 600;
BA_REL_ "GenSigFirstTimeoutTime" BU_SG_REL_ IC3 SG_ 2566885643 Trailer2AxleLoad_AxleId_ISig_3 3000;
BA_REL_ "GenSigTimeoutTime" BU_SG_REL_ IC3 SG_ 2566885643 Trailer2AxleLoad_AxleId_ISig_3 600;
BA_REL_ "GenSigFirstTimeoutTime" BU_SG_REL_ IC3 SG_ 2566885643 Trailer2LiftAxle2Pos_ISig_3 3000;
BA_REL_ "GenSigTimeoutTime" BU_SG_REL_ IC3 SG_ 2566885643 Trailer2LiftAxle2Pos_ISig_3 600;
BA_REL_ "GenSigFirstTimeoutTime" BU_SG_REL_ CIOM SG_ 2566885643 Trailer2LiftAxle2Pos_ISig_3 3000;
BA_REL_ "GenSigTimeoutTime" BU_SG_REL_ CIOM SG_ 2566885643 Trailer2LiftAxle2Pos_ISig_3 600;
BA_REL_ "GenSigFirstTimeoutTime" BU_SG_REL_ BBM SG_ 2566885643 Trailer2LiftAxle2Pos_ISig_3 3000;
BA_REL_ "GenSigTimeoutTime" BU_SG_REL_ BBM SG_ 2566885643 Trailer2LiftAxle2Pos_ISig_3 600;
BA_REL_ "GenSigFirstTimeoutTime" BU_SG_REL_ VMCU SG_ 2566885643 Trailer2LiftAxle2Pos_ISig_3 3000;
BA_REL_ "GenSigTimeoutTime" BU_SG_REL_ VMCU SG_ 2566885643 Trailer2LiftAxle2Pos_ISig_3 600;
BA_REL_ "GenSigFirstTimeoutTime" BU_SG_REL_ IC3 SG_ 2566885643 Trailer2AxleLoad_AxleLoad_ISig_3 3000;
BA_REL_ "GenSigTimeoutTime" BU_SG_REL_ IC3 SG_ 2566885643 Trailer2AxleLoad_AxleLoad_ISig_3 600;
BA_REL_ "GenSigFirstTimeoutTime" BU_SG_REL_ BBM SG_ 2566885643 Trailer2AxleLoad_AxleLoad_ISig_3 3000;
BA_REL_ "GenSigTimeoutTime" BU_SG_REL_ BBM SG_ 2566885643 Trailer2AxleLoad_AxleLoad_ISig_3 600;
BA_REL_ "GenSigFirstTimeoutTime" BU_SG_REL_ VMCU SG_ 2566885643 Trailer2AxleLoad_AxleLoad_ISig_3 3000;
BA_REL_ "GenSigTimeoutTime" BU_SG_REL_ VMCU SG_ 2566885643 Trailer2AxleLoad_AxleLoad_ISig_3 600;
BA_REL_ "GenSigFirstTimeoutTime" BU_SG_REL_ IC3 SG_ 2566885643 TrailerEBSFault 3000;
BA_REL_ "GenSigTimeoutTime" BU_SG_REL_ IC3 SG_ 2566885643 TrailerEBSFault 600;
BA_REL_ "GenSigFirstTimeoutTime" BU_SG_REL_ IC3 SG_ 2566885643 Trailer1AxleLoad_AxleId_ISig_3 3000;
BA_REL_ "GenSigTimeoutTime" BU_SG_REL_ IC3 SG_ 2566885643 Trailer1AxleLoad_AxleId_ISig_3 600;
BA_REL_ "GenSigFirstTimeoutTime" BU_SG_REL_ VMCU SG_ 2566885643 Trailer1AxleLoad_AxleId_ISig_3 3000;
BA_REL_ "GenSigTimeoutTime" BU_SG_REL_ VMCU SG_ 2566885643 Trailer1AxleLoad_AxleId_ISig_3 600;
BA_REL_ "GenSigFirstTimeoutTime" BU_SG_REL_ BBM SG_ 2566885643 Trailer1AxleLoad_AxleId_ISig_3 3000;
BA_REL_ "GenSigTimeoutTime" BU_SG_REL_ BBM SG_ 2566885643 Trailer1AxleLoad_AxleId_ISig_3 600;
BA_REL_ "GenSigFirstTimeoutTime" BU_SG_REL_ IC3 SG_ 2566885643 Trailer1LiftAxle1Pos_ISig_3 3000;
BA_REL_ "GenSigTimeoutTime" BU_SG_REL_ IC3 SG_ 2566885643 Trailer1LiftAxle1Pos_ISig_3 600;
BA_REL_ "GenSigFirstTimeoutTime" BU_SG_REL_ CIOM SG_ 2566885643 Trailer1LiftAxle1Pos_ISig_3 3000;
BA_REL_ "GenSigTimeoutTime" BU_SG_REL_ CIOM SG_ 2566885643 Trailer1LiftAxle1Pos_ISig_3 600;
BA_REL_ "GenSigFirstTimeoutTime" BU_SG_REL_ BBM SG_ 2566885643 Trailer1LiftAxle1Pos_ISig_3 3000;
BA_REL_ "GenSigTimeoutTime" BU_SG_REL_ BBM SG_ 2566885643 Trailer1LiftAxle1Pos_ISig_3 600;
BA_REL_ "GenSigFirstTimeoutTime" BU_SG_REL_ VMCU SG_ 2566885643 Trailer1LiftAxle1Pos_ISig_3 3000;
BA_REL_ "GenSigTimeoutTime" BU_SG_REL_ VMCU SG_ 2566885643 Trailer1LiftAxle1Pos_ISig_3 600;
BA_REL_ "GenSigFirstTimeoutTime" BU_SG_REL_ BBM SG_ 2566885643 Trailer1AxleLoad_AxleLoad_ISig_3 3000;
BA_REL_ "GenSigTimeoutTime" BU_SG_REL_ BBM SG_ 2566885643 Trailer1AxleLoad_AxleLoad_ISig_3 600;
BA_REL_ "GenSigFirstTimeoutTime" BU_SG_REL_ IC3 SG_ 2566885643 Trailer1AxleLoad_AxleLoad_ISig_3 3000;
BA_REL_ "GenSigTimeoutTime" BU_SG_REL_ IC3 SG_ 2566885643 Trailer1AxleLoad_AxleLoad_ISig_3 600;
BA_REL_ "GenSigFirstTimeoutTime" BU_SG_REL_ VMCU SG_ 2566885643 Trailer1AxleLoad_AxleLoad_ISig_3 3000;
BA_REL_ "GenSigTimeoutTime" BU_SG_REL_ VMCU SG_ 2566885643 Trailer1AxleLoad_AxleLoad_ISig_3 600;
BA_REL_ "GenSigFirstTimeoutTime" BU_SG_REL_ DACU SG_ 2566885643 TrailersConnected_ISig_3 3000;
BA_REL_ "GenSigTimeoutTime" BU_SG_REL_ DACU SG_ 2566885643 TrailersConnected_ISig_3 600;
BA_REL_ "GenSigFirstTimeoutTime" BU_SG_REL_ CIOM SG_ 2566885643 TrailersConnected_ISig_3 3000;
BA_REL_ "GenSigTimeoutTime" BU_SG_REL_ CIOM SG_ 2566885643 TrailersConnected_ISig_3 600;
BA_REL_ "GenSigFirstTimeoutTime" BU_SG_REL_ IC3 SG_ 2566885643 TrailersConnected_ISig_3 3000;
BA_REL_ "GenSigTimeoutTime" BU_SG_REL_ IC3 SG_ 2566885643 TrailersConnected_ISig_3 600;
BA_REL_ "GenSigFirstTimeoutTime" BU_SG_REL_ TECU SG_ 2566885643 TrailersConnected_ISig_3 3000;
BA_REL_ "GenSigTimeoutTime" BU_SG_REL_ TECU SG_ 2566885643 TrailersConnected_ISig_3 600;
BA_REL_ "GenSigFirstTimeoutTime" BU_SG_REL_ VMCU SG_ 2566885643 TrailersConnected_ISig_3 3000;
BA_REL_ "GenSigTimeoutTime" BU_SG_REL_ VMCU SG_ 2566885643 TrailersConnected_ISig_3 600;
BA_REL_ "GenSigFirstTimeoutTime" BU_SG_REL_ IC3 SG_ 2566885643 Trailer1LiftAxle2Pos_ISig_3 3000;
BA_REL_ "GenSigTimeoutTime" BU_SG_REL_ IC3 SG_ 2566885643 Trailer1LiftAxle2Pos_ISig_3 600;
BA_REL_ "GenSigFirstTimeoutTime" BU_SG_REL_ BBM SG_ 2566885643 Trailer1LiftAxle2Pos_ISig_3 3000;
BA_REL_ "GenSigTimeoutTime" BU_SG_REL_ BBM SG_ 2566885643 Trailer1LiftAxle2Pos_ISig_3 600;
BA_REL_ "GenSigFirstTimeoutTime" BU_SG_REL_ CIOM SG_ 2566885643 Trailer1LiftAxle2Pos_ISig_3 3000;
BA_REL_ "GenSigTimeoutTime" BU_SG_REL_ CIOM SG_ 2566885643 Trailer1LiftAxle2Pos_ISig_3 600;
BA_REL_ "GenSigFirstTimeoutTime" BU_SG_REL_ VMCU SG_ 2566885643 Trailer1LiftAxle2Pos_ISig_3 3000;
BA_REL_ "GenSigTimeoutTime" BU_SG_REL_ VMCU SG_ 2566885643 Trailer1LiftAxle2Pos_ISig_3 600;
BA_REL_ "GenSigFirstTimeoutTime" BU_SG_REL_ IC3 SG_ 2566885643 Trailer2LiftAxle1Pos_ISig_3 3000;
BA_REL_ "GenSigTimeoutTime" BU_SG_REL_ IC3 SG_ 2566885643 Trailer2LiftAxle1Pos_ISig_3 600;
BA_REL_ "GenSigFirstTimeoutTime" BU_SG_REL_ CIOM SG_ 2566885643 Trailer2LiftAxle1Pos_ISig_3 3000;
BA_REL_ "GenSigTimeoutTime" BU_SG_REL_ CIOM SG_ 2566885643 Trailer2LiftAxle1Pos_ISig_3 600;
BA_REL_ "GenSigFirstTimeoutTime" BU_SG_REL_ VMCU SG_ 2566885643 Trailer2LiftAxle1Pos_ISig_3 3000;
BA_REL_ "GenSigTimeoutTime" BU_SG_REL_ VMCU SG_ 2566885643 Trailer2LiftAxle1Pos_ISig_3 600;
BA_REL_ "GenSigFirstTimeoutTime" BU_SG_REL_ BBM SG_ 2566885643 Trailer2LiftAxle1Pos_ISig_3 3000;
BA_REL_ "GenSigTimeoutTime" BU_SG_REL_ BBM SG_ 2566885643 Trailer2LiftAxle1Pos_ISig_3 600;
BA_REL_ "GenSigFirstTimeoutTime" BU_SG_REL_ IC3 SG_ 2566885643 TrailerCommunicationType_ISig_3 3000;
BA_REL_ "GenSigTimeoutTime" BU_SG_REL_ IC3 SG_ 2566885643 TrailerCommunicationType_ISig_3 600;
BA_REL_ "GenSigFirstTimeoutTime" BU_SG_REL_ IC3 SG_ 2566906635 PredictedMileageOfNextPadChg 48000;
BA_REL_ "GenSigTimeoutTime" BU_SG_REL_ IC3 SG_ 2566906635 PredictedMileageOfNextPadChg 12000;
BA_REL_ "GenSigFirstTimeoutTime" BU_SG_REL_ VMCU SG_ 2566906635 PredictedMileageOfNextPadChg 48000;
BA_REL_ "GenSigTimeoutTime" BU_SG_REL_ VMCU SG_ 2566906635 PredictedMileageOfNextPadChg 12000;
BA_REL_ "GenSigFirstTimeoutTime" BU_SG_REL_ VMCU SG_ 2566906635 PadChgPredictionLastPadChg 48000;
BA_REL_ "GenSigTimeoutTime" BU_SG_REL_ VMCU SG_ 2566906635 PadChgPredictionLastPadChg 12000;
BA_REL_ "GenSigFirstTimeoutTime" BU_SG_REL_ BBM SG_ 2499761675 HSAAvailability 3000;
BA_REL_ "GenSigTimeoutTime" BU_SG_REL_ BBM SG_ 2499761675 HSAAvailability 300;
BA_REL_ "GenSigFirstTimeoutTime" BU_SG_REL_ TECU SG_ 2499761675 HSAAvailability 3000;
BA_REL_ "GenSigTimeoutTime" BU_SG_REL_ TECU SG_ 2499761675 HSAAvailability 240;
BA_REL_ "GenSigFirstTimeoutTime" BU_SG_REL_ IC3 SG_ 2499761675 DTCActive 3000;
BA_REL_ "GenSigTimeoutTime" BU_SG_REL_ IC3 SG_ 2499761675 DTCActive 300;
BA_REL_ "GenSigFirstTimeoutTime" BU_SG_REL_ IC3 SG_ 2499761675 StretchBrake_Stat_ISig_3 3000;
BA_REL_ "GenSigTimeoutTime" BU_SG_REL_ IC3 SG_ 2499761675 StretchBrake_Stat_ISig_3 300;
BA_REL_ "GenSigFirstTimeoutTime" BU_SG_REL_ VMCU SG_ 2499761675 StretchBrake_Stat_ISig_3 3000;
BA_REL_ "GenSigTimeoutTime" BU_SG_REL_ VMCU SG_ 2499761675 StretchBrake_Stat_ISig_3 240;
BA_REL_ "GenSigFirstTimeoutTime" BU_SG_REL_ BBM SG_ 2499761675 TrcnCtrlSlipperyRoadWarning_ISig 3000;
BA_REL_ "GenSigTimeoutTime" BU_SG_REL_ BBM SG_ 2499761675 TrcnCtrlSlipperyRoadWarning_ISig 240;
BA_REL_ "GenSigFirstTimeoutTime" BU_SG_REL_ IC3 SG_ 2499761675 TrcnCtrlSlipperyRoadWarning_ISig 3000;
BA_REL_ "GenSigTimeoutTime" BU_SG_REL_ IC3 SG_ 2499761675 TrcnCtrlSlipperyRoadWarning_ISig 300;
BA_REL_ "GenSigFirstTimeoutTime" BU_SG_REL_ DACU SG_ 2499761675 TrcnCtrlSlipperyRoadWarning_ISig 3000;
BA_REL_ "GenSigTimeoutTime" BU_SG_REL_ DACU SG_ 2499761675 TrcnCtrlSlipperyRoadWarning_ISig 300;
BA_REL_ "GenSigFirstTimeoutTime" BU_SG_REL_ VMCU SG_ 2499761675 RearAxleDiffLockActvnFuncReq_ISi 3000;
BA_REL_ "GenSigTimeoutTime" BU_SG_REL_ VMCU SG_ 2499761675 RearAxleDiffLockActvnFuncReq_ISi 500;
BA_REL_ "GenSigFirstTimeoutTime" BU_SG_REL_ VMCU SG_ 2499761675 BrakeTempWarningLevel 3000;
BA_REL_ "GenSigTimeoutTime" BU_SG_REL_ VMCU SG_ 2499761675 BrakeTempWarningLevel 240;
BA_REL_ "GenSigFirstTimeoutTime" BU_SG_REL_ DACU SG_ 2499761675 BrakeTempWarningLevel 3000;
BA_REL_ "GenSigTimeoutTime" BU_SG_REL_ DACU SG_ 2499761675 BrakeTempWarningLevel 300;
BA_REL_ "GenSigFirstTimeoutTime" BU_SG_REL_ TECU SG_ 2499761675 BrakeTempWarningLevel 3000;
BA_REL_ "GenSigTimeoutTime" BU_SG_REL_ TECU SG_ 2499761675 BrakeTempWarningLevel 240;
BA_REL_ "GenSigFirstTimeoutTime" BU_SG_REL_ EMS SG_ 2499761675 BrakeTempWarningLevel 3000;
BA_REL_ "GenSigTimeoutTime" BU_SG_REL_ EMS SG_ 2499761675 BrakeTempWarningLevel 240;
BA_REL_ "GenSigFirstTimeoutTime" BU_SG_REL_ DACU SG_ 2499761675 RollerBenchModeStatus 3000;
BA_REL_ "GenSigTimeoutTime" BU_SG_REL_ DACU SG_ 2499761675 RollerBenchModeStatus 300;
BA_REL_ "GenSigFirstTimeoutTime" BU_SG_REL_ CIOM SG_ 2499761675 RollerBenchModeStatus 3000;
BA_REL_ "GenSigTimeoutTime" BU_SG_REL_ CIOM SG_ 2499761675 RollerBenchModeStatus 300;
BA_REL_ "GenSigFirstTimeoutTime" BU_SG_REL_ IC3 SG_ 2499761675 RollerBenchModeStatus 3000;
BA_REL_ "GenSigTimeoutTime" BU_SG_REL_ IC3 SG_ 2499761675 RollerBenchModeStatus 300;
BA_REL_ "GenSigFirstTimeoutTime" BU_SG_REL_ VMCU SG_ 2499761675 RollerBenchModeStatus 3000;
BA_REL_ "GenSigTimeoutTime" BU_SG_REL_ VMCU SG_ 2499761675 RollerBenchModeStatus 240;
BA_REL_ "GenSigFirstTimeoutTime" BU_SG_REL_ VMCU SG_ 2499761675 BrakeAssistStatus 3000;
BA_REL_ "GenSigTimeoutTime" BU_SG_REL_ VMCU SG_ 2499761675 BrakeAssistStatus 300;
BA_REL_ "GenSigFirstTimeoutTime" BU_SG_REL_ BBM SG_ 2499761675 LongitudinalAcceleration_ISig_3 3000;
BA_REL_ "GenSigTimeoutTime" BU_SG_REL_ BBM SG_ 2499761675 LongitudinalAcceleration_ISig_3 240;
BA_REL_ "GenSigFirstTimeoutTime" BU_SG_REL_ IC3 SG_ 2499761675 LongitudinalAcceleration_ISig_3 3000;
BA_REL_ "GenSigTimeoutTime" BU_SG_REL_ IC3 SG_ 2499761675 LongitudinalAcceleration_ISig_3 300;
BA_REL_ "GenSigFirstTimeoutTime" BU_SG_REL_ IC3 SG_ 2499761675 ABSManAutoInhibitionStat_ISig_3 3000;
BA_REL_ "GenSigTimeoutTime" BU_SG_REL_ IC3 SG_ 2499761675 ABSManAutoInhibitionStat_ISig_3 300;
BA_REL_ "GenSigFirstTimeoutTime" BU_SG_REL_ IC3 SG_ 2499761675 TractionFunctionSelected_ISig_3 3000;
BA_REL_ "GenSigTimeoutTime" BU_SG_REL_ IC3 SG_ 2499761675 TractionFunctionSelected_ISig_3 300;
BA_REL_ "GenSigFirstTimeoutTime" BU_SG_REL_ IC3 SG_ 2499761675 PoorBrakePerformanceWarning 3000;
BA_REL_ "GenSigTimeoutTime" BU_SG_REL_ IC3 SG_ 2499761675 PoorBrakePerformanceWarning 300;
BA_REL_ "GenSigFirstTimeoutTime" BU_SG_REL_ IC3 SG_ 2499761675 VDCActive_ISig_3 3000;
BA_REL_ "GenSigTimeoutTime" BU_SG_REL_ IC3 SG_ 2499761675 VDCActive_ISig_3 300;
BA_REL_ "GenSigFirstTimeoutTime" BU_SG_REL_ TECU SG_ 2499761675 ABSInhibitionStatus_ISig_3 3000;
BA_REL_ "GenSigTimeoutTime" BU_SG_REL_ TECU SG_ 2499761675 ABSInhibitionStatus_ISig_3 240;
BA_REL_ "GenSigFirstTimeoutTime" BU_SG_REL_ CIOM SG_ 2499761675 ABSInhibitionStatus_ISig_3 3000;
BA_REL_ "GenSigTimeoutTime" BU_SG_REL_ CIOM SG_ 2499761675 ABSInhibitionStatus_ISig_3 300;
BA_REL_ "GenSigFirstTimeoutTime" BU_SG_REL_ VMCU SG_ 2499761675 ABSInhibitionStatus_ISig_3 3000;
BA_REL_ "GenSigTimeoutTime" BU_SG_REL_ VMCU SG_ 2499761675 ABSInhibitionStatus_ISig_3 300;
BA_REL_ "GenSigFirstTimeoutTime" BU_SG_REL_ IC3 SG_ 2499761675 ABSInhibitionStatus_ISig_3 3000;
BA_REL_ "GenSigTimeoutTime" BU_SG_REL_ IC3 SG_ 2499761675 ABSInhibitionStatus_ISig_3 300;
BA_REL_ "GenSigFirstTimeoutTime" BU_SG_REL_ DACU SG_ 2499761675 RearAxleSteeringFunctionStatus 3000;
BA_REL_ "GenSigTimeoutTime" BU_SG_REL_ DACU SG_ 2499761675 RearAxleSteeringFunctionStatus 600;
BA_REL_ "GenSigFirstTimeoutTime" BU_SG_REL_ CIOM SG_ 2499761675 RearAxleSteeringFunctionStatus 3000;
BA_REL_ "GenSigTimeoutTime" BU_SG_REL_ CIOM SG_ 2499761675 RearAxleSteeringFunctionStatus 300;
BA_REL_ "GenSigFirstTimeoutTime" BU_SG_REL_ IC3 SG_ 2499761675 AutoRearAxleDiffLockFnc_stat 3000;
BA_REL_ "GenSigTimeoutTime" BU_SG_REL_ IC3 SG_ 2499761675 AutoRearAxleDiffLockFnc_stat 300;
BA_REL_ "GenSigFirstTimeoutTime" BU_SG_REL_ VMCU SG_ 2499750411 TrailerCorrectionPressure 3000;
BA_REL_ "GenSigTimeoutTime" BU_SG_REL_ VMCU SG_ 2499750411 TrailerCorrectionPressure 300;
BA_REL_ "GenSigFirstTimeoutTime" BU_SG_REL_ CIOM SG_ 2499750411 ESCState_ISig_3 3000;
BA_REL_ "GenSigTimeoutTime" BU_SG_REL_ CIOM SG_ 2499750411 ESCState_ISig_3 300;
BA_REL_ "GenSigFirstTimeoutTime" BU_SG_REL_ IC3 SG_ 2499750411 ESCState_ISig_3 3000;
BA_REL_ "GenSigTimeoutTime" BU_SG_REL_ IC3 SG_ 2499750411 ESCState_ISig_3 300;
BA_REL_ "GenSigFirstTimeoutTime" BU_SG_REL_ DACU SG_ 2499750411 HillHolderMode_ISig_3 3000;
BA_REL_ "GenSigTimeoutTime" BU_SG_REL_ DACU SG_ 2499750411 HillHolderMode_ISig_3 300;
BA_REL_ "GenSigFirstTimeoutTime" BU_SG_REL_ TECU SG_ 2499750411 HillHolderMode_ISig_3 3000;
BA_REL_ "GenSigTimeoutTime" BU_SG_REL_ TECU SG_ 2499750411 HillHolderMode_ISig_3 300;
BA_REL_ "GenSigFirstTimeoutTime" BU_SG_REL_ DACU SG_ 2499750411 HSAState_ISig_3 3000;
BA_REL_ "GenSigTimeoutTime" BU_SG_REL_ DACU SG_ 2499750411 HSAState_ISig_3 300;
BA_REL_ "GenSigFirstTimeoutTime" BU_SG_REL_ IC3 SG_ 2499750411 SasAdaptationInProgress 3000;
BA_REL_ "GenSigTimeoutTime" BU_SG_REL_ IC3 SG_ 2499750411 SasAdaptationInProgress 300;
BA_REL_ "GenSigFirstTimeoutTime" BU_SG_REL_ IC3 SG_ 2499750411 ESCStatus 3000;
BA_REL_ "GenSigTimeoutTime" BU_SG_REL_ IC3 SG_ 2499750411 ESCStatus 300;
BA_REL_ "GenSigFirstTimeoutTime" BU_SG_REL_ IC3 SG_ 2499750411 BrakePedalTestState 3000;
BA_REL_ "GenSigTimeoutTime" BU_SG_REL_ IC3 SG_ 2499750411 BrakePedalTestState 300;
BA_REL_ "GenSigFirstTimeoutTime" BU_SG_REL_ VMCU SG_ 2499750411 ABSOffRoadStatus 3000;
BA_REL_ "GenSigTimeoutTime" BU_SG_REL_ VMCU SG_ 2499750411 ABSOffRoadStatus 300;
BA_REL_ "GenSigFirstTimeoutTime" BU_SG_REL_ IC3 SG_ 2499750411 ABSOffRoadStatus 3000;
BA_REL_ "GenSigTimeoutTime" BU_SG_REL_ IC3 SG_ 2499750411 ABSOffRoadStatus 300;
BA_REL_ "GenSigFirstTimeoutTime" BU_SG_REL_ TECU SG_ 2499750411 ABSOffRoadStatus 3000;
BA_REL_ "GenSigTimeoutTime" BU_SG_REL_ TECU SG_ 2499750411 ABSOffRoadStatus 300;
BA_REL_ "GenSigFirstTimeoutTime" BU_SG_REL_ IC3 SG_ 2499750411 HillStartAidStatus 3000;
BA_REL_ "GenSigTimeoutTime" BU_SG_REL_ IC3 SG_ 2499750411 HillStartAidStatus 300;
BA_REL_ "GenSigFirstTimeoutTime" BU_SG_REL_ VMCU SG_ 2499750411 RoadSpeedInformation 3000;
BA_REL_ "GenSigTimeoutTime" BU_SG_REL_ VMCU SG_ 2499750411 RoadSpeedInformation 300;
BA_REL_ "GenSigFirstTimeoutTime" BU_SG_REL_ TECU SG_ 2499750411 XBRSystemInformation 3000;
BA_REL_ "GenSigTimeoutTime" BU_SG_REL_ TECU SG_ 2499750411 XBRSystemInformation 300;
BA_REL_ "GenSigFirstTimeoutTime" BU_SG_REL_ DACU SG_ 2499750411 XBRSystemInformation 3000;
BA_REL_ "GenSigTimeoutTime" BU_SG_REL_ DACU SG_ 2499750411 XBRSystemInformation 300;
BA_REL_ "GenSigFirstTimeoutTime" BU_SG_REL_ EMS SG_ 2499750411 XBRSystemInformation 3000;
BA_REL_ "GenSigTimeoutTime" BU_SG_REL_ EMS SG_ 2499750411 XBRSystemInformation 300;
BA_REL_ "GenSigFirstTimeoutTime" BU_SG_REL_ BBM SG_ 2566767627 XBRActiveControlMode_ISig_3 6000;
BA_REL_ "GenSigTimeoutTime" BU_SG_REL_ BBM SG_ 2566767627 XBRActiveControlMode_ISig_3 600;
BA_REL_ "GenSigFirstTimeoutTime" BU_SG_REL_ EMS SG_ 2566767627 XBRActiveControlMode_ISig_3 3000;
BA_REL_ "GenSigTimeoutTime" BU_SG_REL_ EMS SG_ 2566767627 XBRActiveControlMode_ISig_3 600;
BA_REL_ "GenSigFirstTimeoutTime" BU_SG_REL_ TECU SG_ 2566767627 XBRActiveControlMode_ISig_3 3000;
BA_REL_ "GenSigTimeoutTime" BU_SG_REL_ TECU SG_ 2566767627 XBRActiveControlMode_ISig_3 600;
BA_REL_ "GenSigFirstTimeoutTime" BU_SG_REL_ DACU SG_ 2566767627 XBRActiveControlMode_ISig_3 3000;
BA_REL_ "GenSigTimeoutTime" BU_SG_REL_ DACU SG_ 2566767627 XBRActiveControlMode_ISig_3 600;
BA_REL_ "GenSigFirstTimeoutTime" BU_SG_REL_ VMCU SG_ 2566767627 XBRActiveControlMode_ISig_3 3000;
BA_REL_ "GenSigTimeoutTime" BU_SG_REL_ VMCU SG_ 2566767627 XBRActiveControlMode_ISig_3 600;
BA_REL_ "GenSigFirstTimeoutTime" BU_SG_REL_ TECU SG_ 2566767627 EPBHillHolderMode_ISig_3 3000;
BA_REL_ "GenSigTimeoutTime" BU_SG_REL_ TECU SG_ 2566767627 EPBHillHolderMode_ISig_3 600;
BA_REL_ "GenSigFirstTimeoutTime" BU_SG_REL_ IC3 SG_ 2566767627 EPBHillHolderMode_ISig_3 3000;
BA_REL_ "GenSigTimeoutTime" BU_SG_REL_ IC3 SG_ 2566767627 EPBHillHolderMode_ISig_3 600;
BA_REL_ "GenSigFirstTimeoutTime" BU_SG_REL_ VMCU SG_ 2566767627 EPBHillHolderMode_ISig_3 3000;
BA_REL_ "GenSigTimeoutTime" BU_SG_REL_ VMCU SG_ 2566767627 EPBHillHolderMode_ISig_3 600;
BA_REL_ "GenSigFirstTimeoutTime" BU_SG_REL_ DACU SG_ 2566767627 FoundationBrakeUse_ISig_3 3000;
BA_REL_ "GenSigTimeoutTime" BU_SG_REL_ DACU SG_ 2566767627 FoundationBrakeUse_ISig_3 600;
BA_REL_ "GenSigFirstTimeoutTime" BU_SG_REL_ CIOM SG_ 2566767627 FoundationBrakeUse_ISig_3 3000;
BA_REL_ "GenSigTimeoutTime" BU_SG_REL_ CIOM SG_ 2566767627 FoundationBrakeUse_ISig_3 600;
BA_REL_ "GenSigFirstTimeoutTime" BU_SG_REL_ EMS SG_ 2566767627 FoundationBrakeUse_ISig_3 3000;
BA_REL_ "GenSigTimeoutTime" BU_SG_REL_ EMS SG_ 2566767627 FoundationBrakeUse_ISig_3 600;
BA_REL_ "GenSigFirstTimeoutTime" BU_SG_REL_ TECU SG_ 2566767627 FoundationBrakeUse_ISig_3 3000;
BA_REL_ "GenSigTimeoutTime" BU_SG_REL_ TECU SG_ 2566767627 FoundationBrakeUse_ISig_3 600;
BA_REL_ "GenSigFirstTimeoutTime" BU_SG_REL_ VMCU SG_ 2566767627 FoundationBrakeUse_ISig_3 3000;
BA_REL_ "GenSigTimeoutTime" BU_SG_REL_ VMCU SG_ 2566767627 FoundationBrakeUse_ISig_3 600;
BA_REL_ "GenSigFirstTimeoutTime" BU_SG_REL_ BBM SG_ 2566767627 XBRSystemState 6000;
BA_REL_ "GenSigTimeoutTime" BU_SG_REL_ BBM SG_ 2566767627 XBRSystemState 600;
BA_REL_ "GenSigFirstTimeoutTime" BU_SG_REL_ DACU SG_ 2566767627 XBRSystemState 3000;
BA_REL_ "GenSigTimeoutTime" BU_SG_REL_ DACU SG_ 2566767627 XBRSystemState 600;
BA_REL_ "GenSigFirstTimeoutTime" BU_SG_REL_ EMS SG_ 2566767627 XBRSystemState 3000;
BA_REL_ "GenSigTimeoutTime" BU_SG_REL_ EMS SG_ 2566767627 XBRSystemState 600;
BA_REL_ "GenSigFirstTimeoutTime" BU_SG_REL_ TECU SG_ 2566767627 XBRSystemState 3000;
BA_REL_ "GenSigTimeoutTime" BU_SG_REL_ TECU SG_ 2566767627 XBRSystemState 600;
BA_REL_ "GenSigFirstTimeoutTime" BU_SG_REL_ IC3 SG_ 2566767627 BrakeTemperatureWarning 3000;
BA_REL_ "GenSigTimeoutTime" BU_SG_REL_ IC3 SG_ 2566767627 BrakeTemperatureWarning 600;
BA_REL_ "GenSigFirstTimeoutTime" BU_SG_REL_ TECU SG_ 2566831883 RrAxle1LeftWheelRelativeSpeed_IS 3000;
BA_REL_ "GenSigTimeoutTime" BU_SG_REL_ TECU SG_ 2566831883 RrAxle1LeftWheelRelativeSpeed_IS 240;
BA_REL_ "GenSigFirstTimeoutTime" BU_SG_REL_ VMCU SG_ 2566831883 RrAxle1LeftWheelRelativeSpeed_IS 3000;
BA_REL_ "GenSigTimeoutTime" BU_SG_REL_ VMCU SG_ 2566831883 RrAxle1LeftWheelRelativeSpeed_IS 240;
BA_REL_ "GenSigFirstTimeoutTime" BU_SG_REL_ VMCU SG_ 2566831883 RrAxle1RightWheelRelativeSpeed_I 3000;
BA_REL_ "GenSigTimeoutTime" BU_SG_REL_ VMCU SG_ 2566831883 RrAxle1RightWheelRelativeSpeed_I 240;
BA_REL_ "GenSigFirstTimeoutTime" BU_SG_REL_ TECU SG_ 2566831883 RrAxle1RightWheelRelativeSpeed_I 3000;
BA_REL_ "GenSigTimeoutTime" BU_SG_REL_ TECU SG_ 2566831883 RrAxle1RightWheelRelativeSpeed_I 240;
BA_REL_ "GenSigFirstTimeoutTime" BU_SG_REL_ TECU SG_ 2566831883 FrAxleRightWheelRelativeSpeed_IS 3000;
BA_REL_ "GenSigTimeoutTime" BU_SG_REL_ TECU SG_ 2566831883 FrAxleRightWheelRelativeSpeed_IS 240;
BA_REL_ "GenSigFirstTimeoutTime" BU_SG_REL_ VMCU SG_ 2566831883 FrAxleRightWheelRelativeSpeed_IS 3000;
BA_REL_ "GenSigTimeoutTime" BU_SG_REL_ VMCU SG_ 2566831883 FrAxleRightWheelRelativeSpeed_IS 240;
BA_REL_ "GenSigFirstTimeoutTime" BU_SG_REL_ TECU SG_ 2566831883 RrAxle2RightWheelRelativeSpeed_I 3000;
BA_REL_ "GenSigTimeoutTime" BU_SG_REL_ TECU SG_ 2566831883 RrAxle2RightWheelRelativeSpeed_I 240;
BA_REL_ "GenSigFirstTimeoutTime" BU_SG_REL_ VMCU SG_ 2566831883 RrAxle2RightWheelRelativeSpeed_I 3000;
BA_REL_ "GenSigTimeoutTime" BU_SG_REL_ VMCU SG_ 2566831883 RrAxle2RightWheelRelativeSpeed_I 240;
BA_REL_ "GenSigFirstTimeoutTime" BU_SG_REL_ TECU SG_ 2566831883 RrAxle2LeftWheelRelativeSpeed_IS 3000;
BA_REL_ "GenSigTimeoutTime" BU_SG_REL_ TECU SG_ 2566831883 RrAxle2LeftWheelRelativeSpeed_IS 240;
BA_REL_ "GenSigFirstTimeoutTime" BU_SG_REL_ VMCU SG_ 2566831883 RrAxle2LeftWheelRelativeSpeed_IS 3000;
BA_REL_ "GenSigTimeoutTime" BU_SG_REL_ VMCU SG_ 2566831883 RrAxle2LeftWheelRelativeSpeed_IS 240;
BA_REL_ "GenSigFirstTimeoutTime" BU_SG_REL_ IC3 SG_ 2566831883 FrontAxleSpeed_ISig_3 3000;
BA_REL_ "GenSigTimeoutTime" BU_SG_REL_ IC3 SG_ 2566831883 FrontAxleSpeed_ISig_3 240;
BA_REL_ "GenSigFirstTimeoutTime" BU_SG_REL_ VMCU SG_ 2566831883 FrontAxleSpeed_ISig_3 3000;
BA_REL_ "GenSigTimeoutTime" BU_SG_REL_ VMCU SG_ 2566831883 FrontAxleSpeed_ISig_3 240;
BA_REL_ "GenSigFirstTimeoutTime" BU_SG_REL_ BBM SG_ 2566831883 FrontAxleSpeed_ISig_3 3000;
BA_REL_ "GenSigTimeoutTime" BU_SG_REL_ BBM SG_ 2566831883 FrontAxleSpeed_ISig_3 240;
BA_REL_ "GenSigFirstTimeoutTime" BU_SG_REL_ EMS SG_ 2566831883 FrontAxleSpeed_ISig_3 3000;
BA_REL_ "GenSigTimeoutTime" BU_SG_REL_ EMS SG_ 2566831883 FrontAxleSpeed_ISig_3 300;
BA_REL_ "GenSigFirstTimeoutTime" BU_SG_REL_ CIOM SG_ 2566831883 FrontAxleSpeed_ISig_3 3000;
BA_REL_ "GenSigTimeoutTime" BU_SG_REL_ CIOM SG_ 2566831883 FrontAxleSpeed_ISig_3 240;
BA_REL_ "GenSigFirstTimeoutTime" BU_SG_REL_ DACU SG_ 2566831883 FrontAxleSpeed_ISig_3 3000;
BA_REL_ "GenSigTimeoutTime" BU_SG_REL_ DACU SG_ 2566831883 FrontAxleSpeed_ISig_3 240;
BA_REL_ "GenSigFirstTimeoutTime" BU_SG_REL_ TECU SG_ 2566831883 FrontAxleSpeed_ISig_3 3000;
BA_REL_ "GenSigTimeoutTime" BU_SG_REL_ TECU SG_ 2566831883 FrontAxleSpeed_ISig_3 240;
BA_REL_ "GenSigFirstTimeoutTime" BU_SG_REL_ TACHO SG_ 2566831883 FrontAxleSpeed_ISig_3 3000;
BA_REL_ "GenSigTimeoutTime" BU_SG_REL_ TACHO SG_ 2566831883 FrontAxleSpeed_ISig_3 250;
BA_REL_ "GenSigFirstTimeoutTime" BU_SG_REL_ TECU SG_ 2566831883 FrAxleLeftWheelRelativeSpeed_ISi 3000;
BA_REL_ "GenSigTimeoutTime" BU_SG_REL_ TECU SG_ 2566831883 FrAxleLeftWheelRelativeSpeed_ISi 240;
BA_REL_ "GenSigFirstTimeoutTime" BU_SG_REL_ VMCU SG_ 2566831883 FrAxleLeftWheelRelativeSpeed_ISi 3000;
BA_REL_ "GenSigTimeoutTime" BU_SG_REL_ VMCU SG_ 2566831883 FrAxleLeftWheelRelativeSpeed_ISi 240;
VAL_ 2566898187 Trailer2CalibInfo_LoadRange_ISig 3 "LoadRange_AxleLoadCalibrationNotSupported" 2 "LoadRange_AxleLoadCalibrationDataForMediumLoad" 1 "LoadRange_AxleLoadCalibrationDataForHeavyLoad" 0 "LoadRange_AxleLoadCalibrationDataForLowLoad" ;
VAL_ 2566898187 Trailer2CalibInfo_CalibUsage_ISi 3 "CalibUsage_StoredCalibrationData_NOT_UsedForAxleLoadOutput" 2 "CalibUsage_spare2" 1 "CalibUsage_spare1" 0 "CalibUsage_StoredCalibrationDataUsedForAxleLoadOutput" ;
VAL_ 2566898187 Trailer2CalibInfo_DataStorage_IS 3 "TrailerCalibDataStore_AxleLoadCalibrationNotSupported" 2 "TrailerCalibDataStore_CalibrationAbortedTimeoutOrError" 1 "TrailerCalibDataStore_NewAxleLoadCalibDataStored" 0 "TrailerCalibDataStore_NoAxleLoadCalibrationDataStorageReq" ;
VAL_ 2566897931 Trailer1CalibInfo_CalibUsage_ISi 3 "CalibUsage_StoredCalibrationData_NOT_UsedForAxleLoadOutput" 2 "CalibUsage_spare2" 1 "CalibUsage_spare1" 0 "CalibUsage_StoredCalibrationDataUsedForAxleLoadOutput" ;
VAL_ 2566897931 Trailer1CalibInfo_DataStorage_IS 3 "TrailerCalibDataStore_AxleLoadCalibrationNotSupported" 2 "TrailerCalibDataStore_CalibrationAbortedTimeoutOrError" 1 "TrailerCalibDataStore_NewAxleLoadCalibDataStored" 0 "TrailerCalibDataStore_NoAxleLoadCalibrationDataStorageReq" ;
VAL_ 2566897931 Trailer1CalibInfo_LoadRange_ISig 3 "LoadRange_AxleLoadCalibrationNotSupported" 2 "LoadRange_AxleLoadCalibrationDataForMediumLoad" 1 "LoadRange_AxleLoadCalibrationDataForHeavyLoad" 0 "LoadRange_AxleLoadCalibrationDataForLowLoad" ;
VAL_ 2566878475 Trailer5RampLevel_LvlPos_ISig_3 3 "LvlPos_NotAvailable" 2 "LvlPos_Error" 1 "LvlPos_VehicleBodyHeightAtLevel2" 0 "LvlPos_VehicleBodyHeightAtLevel1" ;
VAL_ 2566878475 Trailer5RampLevel_LvlStatus_ISig 3 "LvlStatus_NotAvailable" 2 "LvlStatus_Error" 1 "LvlStatus_VehicelBodyAtRequestedLevel" 0 "LvlStatus_VehicelBodyNotAtRequestedLevel" ;
VAL_ 2566878475 Trailer5NormalLevel_LvlPos_ISig_ 3 "LvlPos_NotAvailable" 2 "LvlPos_Error" 1 "LvlPos_VehicleBodyHeightAtLevel2" 0 "LvlPos_VehicleBodyHeightAtLevel1" ;
VAL_ 2566878475 Trailer5BrkLining_Warning_ISig_3 3 "Warning_NotAvailable" 2 "Warning_Error" 1 "Warning_Warning" 0 "Warning_NoWarning" ;
VAL_ 2566878475 Trailer5NormalLevel_LvlStatus_IS 3 "LvlStatus_NotAvailable" 2 "LvlStatus_Error" 1 "LvlStatus_VehicelBodyAtRequestedLevel" 0 "LvlStatus_VehicelBodyNotAtRequestedLevel" ;
VAL_ 2566878219 Trailer4BrkLining_Warning_ISig_3 3 "Warning_NotAvailable" 2 "Warning_Error" 1 "Warning_Warning" 0 "Warning_NoWarning" ;
VAL_ 2566878219 Trailer4NormalLevel_LvlPos_ISig_ 3 "LvlPos_NotAvailable" 2 "LvlPos_Error" 1 "LvlPos_VehicleBodyHeightAtLevel2" 0 "LvlPos_VehicleBodyHeightAtLevel1" ;
VAL_ 2566878219 Trailer4RampLevel_LvlPos_ISig_3 3 "LvlPos_NotAvailable" 2 "LvlPos_Error" 1 "LvlPos_VehicleBodyHeightAtLevel2" 0 "LvlPos_VehicleBodyHeightAtLevel1" ;
VAL_ 2566878219 Trailer4RampLevel_LvlStatus_ISig 3 "LvlStatus_NotAvailable" 2 "LvlStatus_Error" 1 "LvlStatus_VehicelBodyAtRequestedLevel" 0 "LvlStatus_VehicelBodyNotAtRequestedLevel" ;
VAL_ 2566878219 Trailer4NormalLevel_LvlStatus_IS 3 "LvlStatus_NotAvailable" 2 "LvlStatus_Error" 1 "LvlStatus_VehicelBodyAtRequestedLevel" 0 "LvlStatus_VehicelBodyNotAtRequestedLevel" ;
VAL_ 2566877963 Trailer3RampLevel_LvlStatus_ISig 3 "LvlStatus_NotAvailable" 2 "LvlStatus_Error" 1 "LvlStatus_VehicelBodyAtRequestedLevel" 0 "LvlStatus_VehicelBodyNotAtRequestedLevel" ;
VAL_ 2566877963 Trailer3RampLevel_LvlPos_ISig_3 3 "LvlPos_NotAvailable" 2 "LvlPos_Error" 1 "LvlPos_VehicleBodyHeightAtLevel2" 0 "LvlPos_VehicleBodyHeightAtLevel1" ;
VAL_ 2566877963 Trailer3NormalLevel_LvlStatus_IS 3 "LvlStatus_NotAvailable" 2 "LvlStatus_Error" 1 "LvlStatus_VehicelBodyAtRequestedLevel" 0 "LvlStatus_VehicelBodyNotAtRequestedLevel" ;
VAL_ 2566877963 Trailer3BrkLining_Warning_ISig_3 3 "Warning_NotAvailable" 2 "Warning_Error" 1 "Warning_Warning" 0 "Warning_NoWarning" ;
VAL_ 2566877963 Trailer3NormalLevel_LvlPos_ISig_ 3 "LvlPos_NotAvailable" 2 "LvlPos_Error" 1 "LvlPos_VehicleBodyHeightAtLevel2" 0 "LvlPos_VehicleBodyHeightAtLevel1" ;
VAL_ 2566877707 Trailer2NormalLevel_LvlStatus_IS 3 "LvlStatus_NotAvailable" 2 "LvlStatus_Error" 1 "LvlStatus_VehicelBodyAtRequestedLevel" 0 "LvlStatus_VehicelBodyNotAtRequestedLevel" ;
VAL_ 2566877707 Trailer2BrkLining_Warning_ISig_3 3 "Warning_NotAvailable" 2 "Warning_Error" 1 "Warning_Warning" 0 "Warning_NoWarning" ;
VAL_ 2566877707 Trailer2NormalLevel_LvlPos_ISig_ 3 "LvlPos_NotAvailable" 2 "LvlPos_Error" 1 "LvlPos_VehicleBodyHeightAtLevel2" 0 "LvlPos_VehicleBodyHeightAtLevel1" ;
VAL_ 2566877707 Trailer2RampLevel_LvlStatus_ISig 3 "LvlStatus_NotAvailable" 2 "LvlStatus_Error" 1 "LvlStatus_VehicelBodyAtRequestedLevel" 0 "LvlStatus_VehicelBodyNotAtRequestedLevel" ;
VAL_ 2566877707 Trailer2RampLevel_LvlPos_ISig_3 3 "LvlPos_NotAvailable" 2 "LvlPos_Error" 1 "LvlPos_VehicleBodyHeightAtLevel2" 0 "LvlPos_VehicleBodyHeightAtLevel1" ;
VAL_ 2566877451 Trailer1NormalLevel_LvlPos_ISig_ 3 "LvlPos_NotAvailable" 2 "LvlPos_Error" 1 "LvlPos_VehicleBodyHeightAtLevel2" 0 "LvlPos_VehicleBodyHeightAtLevel1" ;
VAL_ 2566877451 Trailer1NormalLevel_LvlStatus_IS 3 "LvlStatus_NotAvailable" 2 "LvlStatus_Error" 1 "LvlStatus_VehicelBodyAtRequestedLevel" 0 "LvlStatus_VehicelBodyNotAtRequestedLevel" ;
VAL_ 2566877451 Trailer1RampLevel_LvlPos_ISig_3 3 "LvlPos_NotAvailable" 2 "LvlPos_Error" 1 "LvlPos_VehicleBodyHeightAtLevel2" 0 "LvlPos_VehicleBodyHeightAtLevel1" ;
VAL_ 2566877451 Trailer1BrkLining_Warning_ISig_3 3 "Warning_NotAvailable" 2 "Warning_Error" 1 "Warning_Warning" 0 "Warning_NoWarning" ;
VAL_ 2566877451 Trailer1RampLevel_LvlStatus_ISig 3 "LvlStatus_NotAvailable" 2 "LvlStatus_Error" 1 "LvlStatus_VehicelBodyAtRequestedLevel" 0 "LvlStatus_VehicelBodyNotAtRequestedLevel" ;
VAL_ 2566903051 Trailer5GeometricData_Index_ISig 255 "TrailerGeometricDataIndex_NotAvailable" 254 "TrailerGeometricDataIndex_Error" 38 "TrailerGeometricDataIndex_TrailerHeightRear" 37 "TrailerGeometricDataIndex_ChassisHeight" 36 "TrailerGeometricDataIndex_TrailerHeightFront" 35 "TrailerGeometricDataIndex_LoadingHeightFront" 34 "TrailerGeometricDataIndex_LoadingHeightRear" 33 "TrailerGeometricDataIndex_CouplingHeight2" 32 "TrailerGeometricDataIndex_CouplingHeight1" 31 "TrailerGeometricDataIndex_TotalLengthOfTrailer" 30 "TrailerGeometricDataIndex_DistanceFirstToSecondCouplingPoint" 29 "TrailerGeometricDataIndex_WheelBaseAxle19ToAxle20" 28 "TrailerGeometricDataIndex_WheelBaseAxle18ToAxle19" 27 "TrailerGeometricDataIndex_WheelBaseAxle17ToAxle18" 26 "TrailerGeometricDataIndex_WheelBaseAxle16ToAxle17" 25 "TrailerGeometricDataIndex_WheelBaseAxle15ToAxle16" 24 "TrailerGeometricDataIndex_WheelBaseAxle14ToAxle15" 23 "TrailerGeometricDataIndex_WheelBaseAxle13ToAxle14" 22 "TrailerGeometricDataIndex_WheelBaseAxle12ToAxle13" 21 "TrailerGeometricDataIndex_WheelBaseAxle11ToAxle12" 20 "TrailerGeometricDataIndex_WheelBaseAxle10ToAxle11" 19 "TrailerGeometricDataIndex_WheelBaseAxle9ToAxle10" 18 "TrailerGeometricDataIndex_WheelBaseAxle8ToAxle9" 17 "TrailerGeometricDataIndex_WheelBaseAxle7ToAxle8" 16 "TrailerGeometricDataIndex_WheelBaseAxle6ToAxle7" 15 "TrailerGeometricDataIndex_WheelBaseAxle5ToAxle6" 14 "TrailerGeometricDataIndex_WheelBaseAxle4ToAxle5" 13 "TrailerGeometricDataIndex_WheelBaseAxle3ToAxle4" 12 "TrailerGeometricDataIndex_WheelBaseAxle2ToAxle3" 11 "TrailerGeometricDataIndex_WheelBaseAxle1ToAxle2" 10 "TrailerGeometricDataIndex_AxleNumberOfLiftAxle5" 9 "TrailerGeometricDataIndex_AxleNumberOfLiftAxle4" 8 "TrailerGeometricDataIndex_AxleNumberOfLiftAxle3" 7 "TrailerGeometricDataIndex_AxleNumberOfLiftAxle2" 6 "TrailerGeometricDataIndex_AxleNumberOfLiftAxle1" 5 "TrailerGeometricDataIndex_NumberOfLiftAxles" 4 "TrailerGeometricDataIndex_NumberOfFrontAxles" 3 "TrailerGeometricDataIndex_NumberOfAxles" 2 "TrailerGeometricDataIndex_TrackWidth" 1 "TrailerGeometricDataIndex_DistanceCouplingToAxle1" 0 "TrailerGeometricDataIndex_TypeOfTrailer" ;
VAL_ 2566903051 PadChangePredictionAxleNumber 7 "PadChangePredictionAxleNumber_Spare_01" 6 "PadChangePredictionAxleNumber_Spare" 5 "PadChangePredictionAxleNumber_AxleNo5" 4 "PadChangePredictionAxleNumber_AxleNo4" 3 "PadChangePredictionAxleNumber_AxleNo3" 2 "PadChangePredictionAxleNumber_AxleNo2" 1 "PadChangePredictionAxleNumber_AxleNo1" 0 "PadChangePredictionAxleNumber_NotApplicable" ;
VAL_ 2566903051 LiningWearWarning 3 "Warning_NotAvailable" 2 "Warning_Error" 1 "Warning_Warning" 0 "Warning_NoWarning" ;
VAL_ 2566902539 Trailer3GeometricData_Index_ISig 255 "TrailerGeometricDataIndex_NotAvailable" 254 "TrailerGeometricDataIndex_Error" 38 "TrailerGeometricDataIndex_TrailerHeightRear" 37 "TrailerGeometricDataIndex_ChassisHeight" 36 "TrailerGeometricDataIndex_TrailerHeightFront" 35 "TrailerGeometricDataIndex_LoadingHeightFront" 34 "TrailerGeometricDataIndex_LoadingHeightRear" 33 "TrailerGeometricDataIndex_CouplingHeight2" 32 "TrailerGeometricDataIndex_CouplingHeight1" 31 "TrailerGeometricDataIndex_TotalLengthOfTrailer" 30 "TrailerGeometricDataIndex_DistanceFirstToSecondCouplingPoint" 29 "TrailerGeometricDataIndex_WheelBaseAxle19ToAxle20" 28 "TrailerGeometricDataIndex_WheelBaseAxle18ToAxle19" 27 "TrailerGeometricDataIndex_WheelBaseAxle17ToAxle18" 26 "TrailerGeometricDataIndex_WheelBaseAxle16ToAxle17" 25 "TrailerGeometricDataIndex_WheelBaseAxle15ToAxle16" 24 "TrailerGeometricDataIndex_WheelBaseAxle14ToAxle15" 23 "TrailerGeometricDataIndex_WheelBaseAxle13ToAxle14" 22 "TrailerGeometricDataIndex_WheelBaseAxle12ToAxle13" 21 "TrailerGeometricDataIndex_WheelBaseAxle11ToAxle12" 20 "TrailerGeometricDataIndex_WheelBaseAxle10ToAxle11" 19 "TrailerGeometricDataIndex_WheelBaseAxle9ToAxle10" 18 "TrailerGeometricDataIndex_WheelBaseAxle8ToAxle9" 17 "TrailerGeometricDataIndex_WheelBaseAxle7ToAxle8" 16 "TrailerGeometricDataIndex_WheelBaseAxle6ToAxle7" 15 "TrailerGeometricDataIndex_WheelBaseAxle5ToAxle6" 14 "TrailerGeometricDataIndex_WheelBaseAxle4ToAxle5" 13 "TrailerGeometricDataIndex_WheelBaseAxle3ToAxle4" 12 "TrailerGeometricDataIndex_WheelBaseAxle2ToAxle3" 11 "TrailerGeometricDataIndex_WheelBaseAxle1ToAxle2" 10 "TrailerGeometricDataIndex_AxleNumberOfLiftAxle5" 9 "TrailerGeometricDataIndex_AxleNumberOfLiftAxle4" 8 "TrailerGeometricDataIndex_AxleNumberOfLiftAxle3" 7 "TrailerGeometricDataIndex_AxleNumberOfLiftAxle2" 6 "TrailerGeometricDataIndex_AxleNumberOfLiftAxle1" 5 "TrailerGeometricDataIndex_NumberOfLiftAxles" 4 "TrailerGeometricDataIndex_NumberOfFrontAxles" 3 "TrailerGeometricDataIndex_NumberOfAxles" 2 "TrailerGeometricDataIndex_TrackWidth" 1 "TrailerGeometricDataIndex_DistanceCouplingToAxle1" 0 "TrailerGeometricDataIndex_TypeOfTrailer" ;
VAL_ 2566902539 Trailer4GeometricData_Index_ISig 255 "TrailerGeometricDataIndex_NotAvailable" 254 "TrailerGeometricDataIndex_Error" 38 "TrailerGeometricDataIndex_TrailerHeightRear" 37 "TrailerGeometricDataIndex_ChassisHeight" 36 "TrailerGeometricDataIndex_TrailerHeightFront" 35 "TrailerGeometricDataIndex_LoadingHeightFront" 34 "TrailerGeometricDataIndex_LoadingHeightRear" 33 "TrailerGeometricDataIndex_CouplingHeight2" 32 "TrailerGeometricDataIndex_CouplingHeight1" 31 "TrailerGeometricDataIndex_TotalLengthOfTrailer" 30 "TrailerGeometricDataIndex_DistanceFirstToSecondCouplingPoint" 29 "TrailerGeometricDataIndex_WheelBaseAxle19ToAxle20" 28 "TrailerGeometricDataIndex_WheelBaseAxle18ToAxle19" 27 "TrailerGeometricDataIndex_WheelBaseAxle17ToAxle18" 26 "TrailerGeometricDataIndex_WheelBaseAxle16ToAxle17" 25 "TrailerGeometricDataIndex_WheelBaseAxle15ToAxle16" 24 "TrailerGeometricDataIndex_WheelBaseAxle14ToAxle15" 23 "TrailerGeometricDataIndex_WheelBaseAxle13ToAxle14" 22 "TrailerGeometricDataIndex_WheelBaseAxle12ToAxle13" 21 "TrailerGeometricDataIndex_WheelBaseAxle11ToAxle12" 20 "TrailerGeometricDataIndex_WheelBaseAxle10ToAxle11" 19 "TrailerGeometricDataIndex_WheelBaseAxle9ToAxle10" 18 "TrailerGeometricDataIndex_WheelBaseAxle8ToAxle9" 17 "TrailerGeometricDataIndex_WheelBaseAxle7ToAxle8" 16 "TrailerGeometricDataIndex_WheelBaseAxle6ToAxle7" 15 "TrailerGeometricDataIndex_WheelBaseAxle5ToAxle6" 14 "TrailerGeometricDataIndex_WheelBaseAxle4ToAxle5" 13 "TrailerGeometricDataIndex_WheelBaseAxle3ToAxle4" 12 "TrailerGeometricDataIndex_WheelBaseAxle2ToAxle3" 11 "TrailerGeometricDataIndex_WheelBaseAxle1ToAxle2" 10 "TrailerGeometricDataIndex_AxleNumberOfLiftAxle5" 9 "TrailerGeometricDataIndex_AxleNumberOfLiftAxle4" 8 "TrailerGeometricDataIndex_AxleNumberOfLiftAxle3" 7 "TrailerGeometricDataIndex_AxleNumberOfLiftAxle2" 6 "TrailerGeometricDataIndex_AxleNumberOfLiftAxle1" 5 "TrailerGeometricDataIndex_NumberOfLiftAxles" 4 "TrailerGeometricDataIndex_NumberOfFrontAxles" 3 "TrailerGeometricDataIndex_NumberOfAxles" 2 "TrailerGeometricDataIndex_TrackWidth" 1 "TrailerGeometricDataIndex_DistanceCouplingToAxle1" 0 "TrailerGeometricDataIndex_TypeOfTrailer" ;
VAL_ 2566902027 Trailer2GeometricData_Index_ISig 255 "TrailerGeometricDataIndex_NotAvailable" 254 "TrailerGeometricDataIndex_Error" 38 "TrailerGeometricDataIndex_TrailerHeightRear" 37 "TrailerGeometricDataIndex_ChassisHeight" 36 "TrailerGeometricDataIndex_TrailerHeightFront" 35 "TrailerGeometricDataIndex_LoadingHeightFront" 34 "TrailerGeometricDataIndex_LoadingHeightRear" 33 "TrailerGeometricDataIndex_CouplingHeight2" 32 "TrailerGeometricDataIndex_CouplingHeight1" 31 "TrailerGeometricDataIndex_TotalLengthOfTrailer" 30 "TrailerGeometricDataIndex_DistanceFirstToSecondCouplingPoint" 29 "TrailerGeometricDataIndex_WheelBaseAxle19ToAxle20" 28 "TrailerGeometricDataIndex_WheelBaseAxle18ToAxle19" 27 "TrailerGeometricDataIndex_WheelBaseAxle17ToAxle18" 26 "TrailerGeometricDataIndex_WheelBaseAxle16ToAxle17" 25 "TrailerGeometricDataIndex_WheelBaseAxle15ToAxle16" 24 "TrailerGeometricDataIndex_WheelBaseAxle14ToAxle15" 23 "TrailerGeometricDataIndex_WheelBaseAxle13ToAxle14" 22 "TrailerGeometricDataIndex_WheelBaseAxle12ToAxle13" 21 "TrailerGeometricDataIndex_WheelBaseAxle11ToAxle12" 20 "TrailerGeometricDataIndex_WheelBaseAxle10ToAxle11" 19 "TrailerGeometricDataIndex_WheelBaseAxle9ToAxle10" 18 "TrailerGeometricDataIndex_WheelBaseAxle8ToAxle9" 17 "TrailerGeometricDataIndex_WheelBaseAxle7ToAxle8" 16 "TrailerGeometricDataIndex_WheelBaseAxle6ToAxle7" 15 "TrailerGeometricDataIndex_WheelBaseAxle5ToAxle6" 14 "TrailerGeometricDataIndex_WheelBaseAxle4ToAxle5" 13 "TrailerGeometricDataIndex_WheelBaseAxle3ToAxle4" 12 "TrailerGeometricDataIndex_WheelBaseAxle2ToAxle3" 11 "TrailerGeometricDataIndex_WheelBaseAxle1ToAxle2" 10 "TrailerGeometricDataIndex_AxleNumberOfLiftAxle5" 9 "TrailerGeometricDataIndex_AxleNumberOfLiftAxle4" 8 "TrailerGeometricDataIndex_AxleNumberOfLiftAxle3" 7 "TrailerGeometricDataIndex_AxleNumberOfLiftAxle2" 6 "TrailerGeometricDataIndex_AxleNumberOfLiftAxle1" 5 "TrailerGeometricDataIndex_NumberOfLiftAxles" 4 "TrailerGeometricDataIndex_NumberOfFrontAxles" 3 "TrailerGeometricDataIndex_NumberOfAxles" 2 "TrailerGeometricDataIndex_TrackWidth" 1 "TrailerGeometricDataIndex_DistanceCouplingToAxle1" 0 "TrailerGeometricDataIndex_TypeOfTrailer" ;
VAL_ 2566902027 Trailer1GeometricData_Index_ISig 255 "TrailerGeometricDataIndex_NotAvailable" 254 "TrailerGeometricDataIndex_Error" 38 "TrailerGeometricDataIndex_TrailerHeightRear" 37 "TrailerGeometricDataIndex_ChassisHeight" 36 "TrailerGeometricDataIndex_TrailerHeightFront" 35 "TrailerGeometricDataIndex_LoadingHeightFront" 34 "TrailerGeometricDataIndex_LoadingHeightRear" 33 "TrailerGeometricDataIndex_CouplingHeight2" 32 "TrailerGeometricDataIndex_CouplingHeight1" 31 "TrailerGeometricDataIndex_TotalLengthOfTrailer" 30 "TrailerGeometricDataIndex_DistanceFirstToSecondCouplingPoint" 29 "TrailerGeometricDataIndex_WheelBaseAxle19ToAxle20" 28 "TrailerGeometricDataIndex_WheelBaseAxle18ToAxle19" 27 "TrailerGeometricDataIndex_WheelBaseAxle17ToAxle18" 26 "TrailerGeometricDataIndex_WheelBaseAxle16ToAxle17" 25 "TrailerGeometricDataIndex_WheelBaseAxle15ToAxle16" 24 "TrailerGeometricDataIndex_WheelBaseAxle14ToAxle15" 23 "TrailerGeometricDataIndex_WheelBaseAxle13ToAxle14" 22 "TrailerGeometricDataIndex_WheelBaseAxle12ToAxle13" 21 "TrailerGeometricDataIndex_WheelBaseAxle11ToAxle12" 20 "TrailerGeometricDataIndex_WheelBaseAxle10ToAxle11" 19 "TrailerGeometricDataIndex_WheelBaseAxle9ToAxle10" 18 "TrailerGeometricDataIndex_WheelBaseAxle8ToAxle9" 17 "TrailerGeometricDataIndex_WheelBaseAxle7ToAxle8" 16 "TrailerGeometricDataIndex_WheelBaseAxle6ToAxle7" 15 "TrailerGeometricDataIndex_WheelBaseAxle5ToAxle6" 14 "TrailerGeometricDataIndex_WheelBaseAxle4ToAxle5" 13 "TrailerGeometricDataIndex_WheelBaseAxle3ToAxle4" 12 "TrailerGeometricDataIndex_WheelBaseAxle2ToAxle3" 11 "TrailerGeometricDataIndex_WheelBaseAxle1ToAxle2" 10 "TrailerGeometricDataIndex_AxleNumberOfLiftAxle5" 9 "TrailerGeometricDataIndex_AxleNumberOfLiftAxle4" 8 "TrailerGeometricDataIndex_AxleNumberOfLiftAxle3" 7 "TrailerGeometricDataIndex_AxleNumberOfLiftAxle2" 6 "TrailerGeometricDataIndex_AxleNumberOfLiftAxle1" 5 "TrailerGeometricDataIndex_NumberOfLiftAxles" 4 "TrailerGeometricDataIndex_NumberOfFrontAxles" 3 "TrailerGeometricDataIndex_NumberOfAxles" 2 "TrailerGeometricDataIndex_TrackWidth" 1 "TrailerGeometricDataIndex_DistanceCouplingToAxle1" 0 "TrailerGeometricDataIndex_TypeOfTrailer" ;
VAL_ 2566886667 Trailer5LiftAxle1Pos_ISig_3 3 "TrailerLiftAxlePos_NotAvailable" 2 "TrailerLiftAxlePos_Error" 1 "TrailerLiftAxlePos_AxleLifted" 0 "TrailerLiftAxlePos_AxleDown" ;
VAL_ 2566886667 Trailer5LiftAxle2Pos_ISig_3 3 "TrailerLiftAxlePos_NotAvailable" 2 "TrailerLiftAxlePos_Error" 1 "TrailerLiftAxlePos_AxleLifted" 0 "TrailerLiftAxlePos_AxleDown" ;
VAL_ 2566886155 Trailer3LiftAxle1Pos_ISig_3 3 "TrailerLiftAxlePos_NotAvailable" 2 "TrailerLiftAxlePos_Error" 1 "TrailerLiftAxlePos_AxleLifted" 0 "TrailerLiftAxlePos_AxleDown" ;
VAL_ 2566886155 Trailer4LiftAxle2Pos_ISig_3 3 "TrailerLiftAxlePos_NotAvailable" 2 "TrailerLiftAxlePos_Error" 1 "TrailerLiftAxlePos_AxleLifted" 0 "TrailerLiftAxlePos_AxleDown" ;
VAL_ 2566886155 Trailer3LiftAxle2Pos_ISig_3 3 "TrailerLiftAxlePos_NotAvailable" 2 "TrailerLiftAxlePos_Error" 1 "TrailerLiftAxlePos_AxleLifted" 0 "TrailerLiftAxlePos_AxleDown" ;
VAL_ 2566886155 Trailer4LiftAxle1Pos_ISig_3 3 "TrailerLiftAxlePos_NotAvailable" 2 "TrailerLiftAxlePos_Error" 1 "TrailerLiftAxlePos_AxleLifted" 0 "TrailerLiftAxlePos_AxleDown" ;
VAL_ 2566885643 Trailer2LiftAxle2Pos_ISig_3 3 "TrailerLiftAxlePos_NotAvailable" 2 "TrailerLiftAxlePos_Error" 1 "TrailerLiftAxlePos_AxleLifted" 0 "TrailerLiftAxlePos_AxleDown" ;
VAL_ 2566885643 TrailerEBSFault 3 "OkNok_NotAvailable" 2 "OkNok_Error" 1 "OkNok_NotOK" 0 "OkNok_OK" ;
VAL_ 2566885643 Trailer1LiftAxle1Pos_ISig_3 3 "TrailerLiftAxlePos_NotAvailable" 2 "TrailerLiftAxlePos_Error" 1 "TrailerLiftAxlePos_AxleLifted" 0 "TrailerLiftAxlePos_AxleDown" ;
VAL_ 2566885643 Trailer1LiftAxle2Pos_ISig_3 3 "TrailerLiftAxlePos_NotAvailable" 2 "TrailerLiftAxlePos_Error" 1 "TrailerLiftAxlePos_AxleLifted" 0 "TrailerLiftAxlePos_AxleDown" ;
VAL_ 2566885643 Trailer2LiftAxle1Pos_ISig_3 3 "TrailerLiftAxlePos_NotAvailable" 2 "TrailerLiftAxlePos_Error" 1 "TrailerLiftAxlePos_AxleLifted" 0 "TrailerLiftAxlePos_AxleDown" ;
VAL_ 2566885643 TrailerCommunicationType_ISig_3 7 "TrailerCommunicationType_NotAvailable" 6 "TrailerCommunicationType_Error" 5 "TrailerCommunicationType_Spare3" 4 "TrailerCommunicationType_Spare2" 3 "TrailerCommunicationType_Spare1" 2 "TrailerCommunicationType_SAE_J2497_Communication" 1 "TrailerCommunicationType_ISO_11992_2_Communication" 0 "TrailerCommunicationType_NoCommunication" ;
VAL_ 2499761675 HSAAvailability 3 "NotAvailable_NotAvailable" 2 "NotAvailable_Error" 1 "NotAvailable_FunctionAvailable" 0 "NotAvailable_FunctionNotAvailable" ;
VAL_ 2499761675 DTCActive 3 "DTCActive_DTCStatusInfoNotAvailableOrNotSupported" 2 "DTCActive_ErrorIndicator" 1 "DTCActive_DTCActive" 0 "DTCActive_DTCStatusInfoAvailableButNotActive" ;
VAL_ 2499761675 StretchBrake_Stat_ISig_3 7 "StretchBrake_Stat_NotAvailable" 6 "StretchBrake_Stat_Error" 5 "StretchBrake_Stat_Spare_02" 4 "StretchBrake_Stat_Spare_01" 3 "StretchBrake_Stat_Spare" 2 "StretchBrake_Stat_Active" 1 "StretchBrake_Stat_Enabled" 0 "StretchBrake_Stat_Disabled" ;
VAL_ 2499761675 TrcnCtrlSlipperyRoadWarning_ISig 3 "InactiveActive_NotAvailable" 2 "InactiveActive_Error" 1 "InactiveActive_Active" 0 "InactiveActive_Inactive" ;
VAL_ 2499761675 RearAxleDiffLockActvnFuncReq_ISi 3 "RearAxleDiffLockActvnFuncReq_TakeNoAction" 2 "RearAxleDiffLockActvnFuncReq_Reserved" 1 "RearAxleDiffLockActvnFuncReq_DisengageDifferentialLock" 0 "RearAxleDiffLockActvnFuncReq_EngageDifferentialLock" ;
VAL_ 2499761675 RollerBenchModeStatus 3 "InactiveActive_NotAvailable" 2 "InactiveActive_Error" 1 "InactiveActive_Active" 0 "InactiveActive_Inactive" ;
VAL_ 2499761675 BrakeAssistStatus 3 "OffOn_NotAvailable" 2 "OffOn_Error" 1 "OffOn_On" 0 "OffOn_Off" ;
VAL_ 2499761675 ABSManAutoInhibitionStat_ISig_3 7 "ABSManAutoInhibitionStat_NotAvailable" 6 "ABSManAutoInhibitionStat_Error" 5 "ABSManAutoInhibitionStat_Spare02" 4 "ABSManAutoInhibitionStat_Spare01" 3 "ABSManAutoInhibitionStat_Spare" 2 "ABSManAutoInhibitionStat_ABSAutomaticInhibition" 1 "ABSManAutoInhibitionStat_ABSManualInhibition" 0 "ABSManAutoInhibitionStat_ABSNoInhibition" ;
VAL_ 2499761675 TractionFunctionSelected_ISig_3 7 "TractionFunctionSelected_NotAvailable" 6 "TractionFunctionSelected_Error" 5 "TractionFunctionSelected_Spare_02" 4 "TractionFunctionSelected_Spare_01" 3 "TractionFunctionSelected_Spare" 2 "TractionFunctionSelected_TractionOFFROAD" 1 "TractionFunctionSelected_TractionOFF" 0 "TractionFunctionSelected_TractionON" ;
VAL_ 2499761675 PoorBrakePerformanceWarning 3 "Warning_NotAvailable" 2 "Warning_Error" 1 "Warning_Warning" 0 "Warning_NoWarning" ;
VAL_ 2499761675 VDCActive_ISig_3 3 "VDCActive_NotAvailableOrNotInstalled" 2 "VDCActive_ErrorIndicator" 1 "VDCActive_VDCActive" 0 "VDCActive_VDCPassiveButInstalled" ;
VAL_ 2499761675 ABSInhibitionStatus_ISig_3 3 "Inhibit_NotAvailable" 2 "Inhibit_Error" 1 "Inhibit_InhibitActive" 0 "Inhibit_NoInhibit" ;
VAL_ 2499761675 RearAxleSteeringFunctionStatus 7 "RearAxleSteeringFunctionStatus_NotAvailable" 6 "RearAxleSteeringFunctionStatus_Error" 5 "RearAxleSteeringFunctionStatus_SpareValue_01" 4 "RearAxleSteeringFunctionStatus_SpareValue" 3 "RearAxleSteeringFunctionStatus_ActiveFailureMode" 2 "RearAxleSteeringFunctionStatus_PassiveFailureMode" 1 "RearAxleSteeringFunctionStatus_Active" 0 "RearAxleSteeringFunctionStatus_NotActive" ;
VAL_ 2499761675 AutoRearAxleDiffLockFnc_stat 3 "InactiveActive_NotAvailable" 2 "InactiveActive_Error" 1 "InactiveActive_Active" 0 "InactiveActive_Inactive" ;
VAL_ 2499750411 ESCState_ISig_3 7 "ESCState_NotAvailable" 6 "ESCState_Error" 5 "ESCState_Spare03" 4 "ESCState_Spare02" 3 "ESCState_Spare01" 2 "ESCState_Reduced" 1 "ESCState_On" 0 "ESCState_Off" ;
VAL_ 2499750411 HillHolderMode_ISig_3 7 "HillHolderMode_NotAvailable" 6 "HillHolderMode_Reserved" 5 "HillHolderMode_Spare2" 4 "HillHolderMode_Spare1" 3 "HillHolderMode_OnHold_PressureApplied" 2 "HillHolderMode_Active_WillChangeToInactiveSoon" 1 "HillHolderMode_Active" 0 "HillHolderMode_Inactive" ;
VAL_ 2499750411 HSAState_ISig_3 3 "HSAState_NotAvailable" 2 "HSAState_HSA_FunctionFullyOperational" 1 "HSAState_HSA_FunctionnotWorking" 0 "HSAState_HSA_FunctionRestrictedFunctionalityAvailable" ;
VAL_ 2499750411 SasAdaptationInProgress 3 "OffOn_NotAvailable" 2 "OffOn_Error" 1 "OffOn_On" 0 "OffOn_Off" ;
VAL_ 2499750411 ESCStatus 7 "ESCStatus_NotAvailable" 6 "ESCStatus_Error" 5 "ESCStatus_PartlyMalfunctioning" 4 "ESCStatus_FullyMalfunctioning" 3 "ESCStatus_ESCOn" 2 "ESCStatus_Spare3" 1 "ESCStatus_ESCReduced" 0 "ESCStatus_ESCOff" ;
VAL_ 2499750411 BrakePedalTestState 15 "BrakePedalTestState_NotAvailable" 14 "BrakePedalTestState_Error" 13 "BrakePedalTestState_Spare_06" 12 "BrakePedalTestState_Spare_05" 11 "BrakePedalTestState_Spare_04" 10 "BrakePedalTestState_Spare_03" 9 "BrakePedalTestState_Spare_02" 8 "BrakePedalTestState_Spare_01" 7 "BrakePedalTestState_Spare" 6 "BrakePedalTestState_TestInterrIncorrOpByDrAtLeastOneActFault" 5 "BrakePedalTestState_TestWasCorrectlyOpByDrAtLeastOneActFault" 4 "BrakePedalTestState_TestWasCorrectlyOperatedByDrFaultDeleted" 3 "BrakePedalTestState_BrakePedalReleaseIsNeeded" 2 "BrakePedalTestState_FullBrakePedalActuationIsNeeded" 1 "BrakePedalTestState_TestIsNeededKeepBrakePedalReleased" 0 "BrakePedalTestState_BrakePedalTestIsNotNeeded" ;
VAL_ 2499750411 ABSOffRoadStatus 3 "OffOn_NotAvailable" 2 "OffOn_Error" 1 "OffOn_On" 0 "OffOn_Off" ;
VAL_ 2499750411 HillStartAidStatus 7 "HillStartAidStatus_NotAvailable" 6 "HillStartAidStatus_Error" 5 "HillStartAidStatus_NotDefined2" 4 "HillStartAidStatus_ActiveWithWarningHigh" 3 "HillStartAidStatus_ActiveWithWarningLow" 2 "HillStartAidStatus_ActiveButWillChangeToInactiveInAShortTime" 1 "HillStartAidStatus_Active" 0 "HillStartAidStatus_Inactive" ;
VAL_ 2499750411 XBRSystemInformation 7 "XBRSystemInformation_NotAvailable" 6 "XBRSystemInformation_Spare03" 5 "XBRSystemInformation_Spare02" 4 "XBRSystemInformation_OnlyEBIOrHighestPriorityAccepted" 3 "XBRSystemInformation_ExternalBrakeDemandExecutionNotPossible" 2 "XBRSystemInformation_NoEBIAndOnlyHighestPriorityIsAccepted" 1 "XBRSystemInformation_NoEBIButElseFullyOperational" 0 "XBRSystemInformation_AnyBrakeRequestWillBeAccepted" ;
VAL_ 2566767627 XBRActiveControlMode_ISig_3 15 "XBRActiveControlMode_NotAvailable" 3 "XBRActiveControlMode_MaximumModeOfXBRAccelControlExecuted" 2 "XBRActiveControlMode_AdditionModeoXBRAccelControlExecuted" 1 "XBRActiveControlMode_DriversBrakeDemandExecNoExtBrakeDemand" 0 "XBRActiveControlMode_NoBrakeDemandBeingExecutedDefaultMode" ;
VAL_ 2566767627 EPBHillHolderMode_ISig_3 7 "EPBHillHolderMode_NotAvailable" 6 "EPBHillHolderMode_Reserved" 5 "EPBHillHolderMode_NotDefined_02" 4 "EPBHillHolderMode_NotDefined_01" 3 "EPBHillHolderMode_NotDefined" 2 "EPBHillHolderMode_ActiveWillChngToInactiveInShortTime" 1 "EPBHillHolderMode_Active" 0 "EPBHillHolderMode_Inactive" ;
VAL_ 2566767627 FoundationBrakeUse_ISig_3 3 "FoundationBrakeUse_NotAvailable" 2 "FoundationBrakeUse_Reserved" 1 "FoundationBrakeUse_FoundationBrakesInUse" 0 "FoundationBrakeUse_FoundationBrakesNotInUse" ;
VAL_ 2566767627 XBRSystemState 3 "XBRSystemState_NotAvailable" 2 "XBRSystemState_NoExternalBrakeDemandAccepted" 1 "XBRSystemState_OnlyHighestXBRPriorityDemandAccepted" 0 "XBRSystemState_ExternalBrakeDemandAccepted" ;
VAL_ 2566767627 BrakeTemperatureWarning 3 "Warning_NotAvailable" 2 "Warning_Error" 1 "Warning_Warning" 0 "Warning_NoWarning" ;
SIG_GROUP_ 2566898187 Trailer2CalibInfo_sg_ISig_3 1 : Trailer2CalibInfo_LoadRange_ISig Trailer2CalibInfo_CalibUsage_ISi Trailer2CalibInfo_UncalibLoad_IS Trailer2CalibInfo_ScaleLoad_ISig Trailer2CalibInfo_DataStorage_IS Trailer2CalibInfo_AxleId_ISig_3 Trailer2CalibInfo_Year_ISig_3 Trailer2CalibInfo_Month_ISig_3;
SIG_GROUP_ 2566897931 Trailer1CalibInfo_sg_ISig_3 1 : Trailer1CalibInfo_CalibUsage_ISi Trailer1CalibInfo_ScaleLoad_ISig Trailer1CalibInfo_DataStorage_IS Trailer1CalibInfo_Month_ISig_3 Trailer1CalibInfo_LoadRange_ISig Trailer1CalibInfo_AxleId_ISig_3 Trailer1CalibInfo_UncalibLoad_IS Trailer1CalibInfo_Year_ISig_3;
SIG_GROUP_ 2566878475 Trailer5RampLevel_sg_ISig_3 1 : Trailer5RampLevel_LvlPos_ISig_3 Trailer5RampLevel_LvlStatus_ISig;
SIG_GROUP_ 2566878475 Trailer5RelBodyLevel_sg 1 : Trailer5RelBodyLevel_FrontLevel Trailer5RelBodyLevel_RearLevel;
SIG_GROUP_ 2566878475 Trailer5BrkLining_sg_ISig_3 1 : Trailer5BrkLining_Wear_ISig_3 Trailer5BrkLining_BrkLnTireId_IS Trailer5BrkLining_Warning_ISig_3;
SIG_GROUP_ 2566878475 Trailer5NormalLevel_sg_ISig_3 1 : Trailer5NormalLevel_LvlPos_ISig_ Trailer5NormalLevel_LvlStatus_IS;
SIG_GROUP_ 2566878219 Trailer4BrkLining_sg_ISig_3 1 : Trailer4BrkLining_Warning_ISig_3 Trailer4BrkLining_Wear_ISig_3 Trailer4BrkLining_BrkLnTireId_IS;
SIG_GROUP_ 2566878219 Trailer4RampLevel_sg_ISig_3 1 : Trailer4RampLevel_LvlPos_ISig_3 Trailer4RampLevel_LvlStatus_ISig;
SIG_GROUP_ 2566878219 Trailer4NormalLevel_sg_ISig_3 1 : Trailer4NormalLevel_LvlPos_ISig_ Trailer4NormalLevel_LvlStatus_IS;
SIG_GROUP_ 2566878219 Trailer4RelBodyLevel_sg 1 : Trailer4RelBodyLevel_RearLevel Trailer4RelBodyLevel_FrontLevel;
SIG_GROUP_ 2566877963 Trailer3RelBodyLevel_sg 1 : Trailer3RelBodyLevel_FrontLevel Trailer3RelBodyLevel_RearLevel;
SIG_GROUP_ 2566877963 Trailer3RampLevel_sg_ISig_3 1 : Trailer3RampLevel_LvlStatus_ISig Trailer3RampLevel_LvlPos_ISig_3;
SIG_GROUP_ 2566877963 Trailer3NormalLevel_sg_ISig_3 1 : Trailer3NormalLevel_LvlStatus_IS Trailer3NormalLevel_LvlPos_ISig_;
SIG_GROUP_ 2566877963 Trailer3BrkLining_sg_ISig_3 1 : Trailer3BrkLining_BrkLnTireId_IS Trailer3BrkLining_Wear_ISig_3 Trailer3BrkLining_Warning_ISig_3;
SIG_GROUP_ 2566877707 Trailer2RelBodyLevel_sg 1 : Trailer2RelBodyLevel_FrontLevel Trailer2RelBodyLevel_RearLevel;
SIG_GROUP_ 2566877707 Trailer2RampLevel_sg_ISig_3 1 : Trailer2RampLevel_LvlStatus_ISig Trailer2RampLevel_LvlPos_ISig_3;
SIG_GROUP_ 2566877707 Trailer2BrkLining_sg_ISig_3 1 : Trailer2BrkLining_BrkLnTireId_IS Trailer2BrkLining_Warning_ISig_3 Trailer2BrkLining_Wear_ISig_3;
SIG_GROUP_ 2566877707 Trailer2NormalLevel_sg_ISig_3 1 : Trailer2NormalLevel_LvlStatus_IS Trailer2NormalLevel_LvlPos_ISig_;
SIG_GROUP_ 2566877451 Trailer1BrkLining_sg_ISig_3 1 : Trailer1BrkLining_Warning_ISig_3 Trailer1BrkLining_BrkLnTireId_IS Trailer1BrkLining_Wear_ISig_3;
SIG_GROUP_ 2566877451 Trailer1RampLevel_sg_ISig_3 1 : Trailer1RampLevel_LvlPos_ISig_3 Trailer1RampLevel_LvlStatus_ISig;
SIG_GROUP_ 2566877451 Trailer1NormalLevel_sg_ISig_3 1 : Trailer1NormalLevel_LvlPos_ISig_ Trailer1NormalLevel_LvlStatus_IS;
SIG_GROUP_ 2566877451 Trailer1RelBodyLevel_sg 1 : Trailer1RelBodyLevel_RearLevel Trailer1RelBodyLevel_FrontLevel;
SIG_GROUP_ 2566903051 Trailer5GeometricData_sg_ISig_3 1 : Trailer5GeometricData_Index_ISig Trailer5GeometricData_Content_IS;
SIG_GROUP_ 2566902539 Trailer4GeometricData_sg_ISig_3 1 : Trailer4GeometricData_Content_IS Trailer4GeometricData_Index_ISig;
SIG_GROUP_ 2566902539 Trailer3GeometricData_sg_ISig_3 1 : Trailer3GeometricData_Index_ISig Trailer3GeometricData_Content_IS;
SIG_GROUP_ 2566902027 Trailer1GeometricData_sg_ISig_3 1 : Trailer1GeometricData_Content_IS Trailer1GeometricData_Index_ISig;
SIG_GROUP_ 2566902027 Trailer2GeometricData_sg_ISig_3 1 : Trailer2GeometricData_Index_ISig Trailer2GeometricData_Content_IS;
SIG_GROUP_ 2566886667 Trailer5AxleLoad_sg_ISig_3 1 : Trailer5AxleLoad_AxleLoad_ISig_3 Trailer5AxleLoad_AxleId_ISig_3;
SIG_GROUP_ 2566886155 Trailer3AxleLoad_sg_ISig_3 1 : Trailer3AxleLoad_AxleId_ISig_3 Trailer3AxleLoad_AxleLoad_ISig_3;
SIG_GROUP_ 2566886155 Trailer4AxleLoad_sg_ISig_3 1 : Trailer4AxleLoad_AxleLoad_ISig_3 Trailer4AxleLoad_AxleId_ISig_3;
SIG_GROUP_ 2566885643 Trailer2AxleLoad_sg_ISig_3 1 : Trailer2AxleLoad_AxleId_ISig_3 Trailer2AxleLoad_AxleLoad_ISig_3;
SIG_GROUP_ 2566885643 Trailer1AxleLoad_sg_ISig_3 1 : Trailer1AxleLoad_AxleId_ISig_3 Trailer1AxleLoad_AxleLoad_ISig_3;
